VERSION ""

NS_ :

BS_:

BU_: MCTM_LS TIM_LS EOCM2cp_K2_LS EOCM2cp_K1_LS ADIMa_LS BCM_LS SAM_SR_LS SAM_SL_LS SAM_PR_LS SAM_PL_LS CGM3a_LS Dummy_LS VICM_LS ECC_LS PEPS_LS AOS_LS SDM_PR_LS AOS2_LS DLM_LS SCCM_2_LS SCCM_1_LS UPA_LS ADIMb_LS

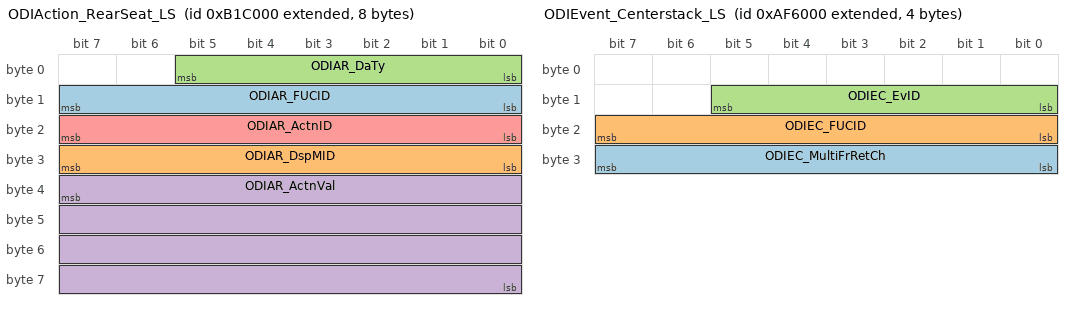
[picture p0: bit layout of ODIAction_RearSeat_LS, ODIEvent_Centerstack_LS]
BO_ 2159132672 ODIAction_RearSeat_LS: 8 MCTM_LS
 SG_ ODIAR_FUCID : 15|8@0+ (1,0) [0|255] ""  ECC_LS,CGM3a_LS
 SG_ ODIAR_DspMID : 31|8@0+ (1,0) [0|255] ""  ECC_LS,CGM3a_LS
 SG_ ODIAR_DaTy : 5|6@0+ (1,0) [0|63] ""  ECC_LS,CGM3a_LS
 SG_ ODIAR_ActnVal : 39|32@0+ (1,0) [0|4294967295] ""  ECC_LS,CGM3a_LS
 SG_ ODIAR_ActnID : 23|8@0+ (1,0) [0|255] ""  ECC_LS,CGM3a_LS

BO_ 2158968832 ODI_RearSeat_2_Centerstack_LS: 8 MCTM_LS
 SG_ ODI_RSD2CntrStck : 7|64@0+ (1,0) [0|1.84467440737096E+019] ""  CGM3a_LS

BO_ 2158895104 ODI_CenterStack_2_RearSeat_LS: 8 CGM3a_LS
 SG_ ODI_CntrStck2RSD : 7|64@0+ (1,0) [0|1.84467440737096E+019] ""  MCTM_LS

BO_ 2158960640 ODIIndication_Centerstack_LS: 8 CGM3a_LS
 SG_ ODIIC_FUCID : 7|8@0+ (1,0) [0|255] ""  MCTM_LS
 SG_ ODIIC_ODIInd9 : 23|1@0+ (1,0) [0|1] ""  MCTM_LS
 SG_ ODIIC_ODIInd8 : 8|1@0+ (1,0) [0|1] ""  MCTM_LS
 SG_ ODIIC_ODIInd7 : 9|1@0+ (1,0) [0|1] ""  MCTM_LS
 SG_ ODIIC_ODIInd6 : 10|1@0+ (1,0) [0|1] ""  MCTM_LS
 SG_ ODIIC_ODIInd56 : 56|1@0+ (1,0) [0|1] ""  MCTM_LS
 SG_ ODIIC_ODIInd55 : 57|1@0+ (1,0) [0|1] ""  MCTM_LS
 SG_ ODIIC_ODIInd54 : 58|1@0+ (1,0) [0|1] ""  MCTM_LS
 SG_ ODIIC_ODIInd53 : 59|1@0+ (1,0) [0|1] ""  MCTM_LS
 SG_ ODIIC_ODIInd52 : 60|1@0+ (1,0) [0|1] ""  MCTM_LS
 SG_ ODIIC_ODIInd51 : 61|1@0+ (1,0) [0|1] ""  MCTM_LS
 SG_ ODIIC_ODIInd50 : 62|1@0+ (1,0) [0|1] ""  MCTM_LS
 SG_ ODIIC_ODIInd5 : 11|1@0+ (1,0) [0|1] ""  MCTM_LS
 SG_ ODIIC_ODIInd49 : 63|1@0+ (1,0) [0|1] ""  MCTM_LS
 SG_ ODIIC_ODIInd48 : 48|1@0+ (1,0) [0|1] ""  MCTM_LS
 SG_ ODIIC_ODIInd47 : 49|1@0+ (1,0) [0|1] ""  MCTM_LS
 SG_ ODIIC_ODIInd46 : 50|1@0+ (1,0) [0|1] ""  MCTM_LS
 SG_ ODIIC_ODIInd45 : 51|1@0+ (1,0) [0|1] ""  MCTM_LS
 SG_ ODIIC_ODIInd44 : 52|1@0+ (1,0) [0|1] ""  MCTM_LS
 SG_ ODIIC_ODIInd43 : 53|1@0+ (1,0) [0|1] ""  MCTM_LS
 SG_ ODIIC_ODIInd42 : 54|1@0+ (1,0) [0|1] ""  MCTM_LS
 SG_ ODIIC_ODIInd41 : 55|1@0+ (1,0) [0|1] ""  MCTM_LS
 SG_ ODIIC_ODIInd40 : 40|1@0+ (1,0) [0|1] ""  MCTM_LS
 SG_ ODIIC_ODIInd4 : 12|1@0+ (1,0) [0|1] ""  MCTM_LS
 SG_ ODIIC_ODIInd39 : 41|1@0+ (1,0) [0|1] ""  MCTM_LS
 SG_ ODIIC_ODIInd38 : 42|1@0+ (1,0) [0|1] ""  MCTM_LS
 SG_ ODIIC_ODIInd37 : 43|1@0+ (1,0) [0|1] ""  MCTM_LS
 SG_ ODIIC_ODIInd36 : 44|1@0+ (1,0) [0|1] ""  MCTM_LS
 SG_ ODIIC_ODIInd35 : 45|1@0+ (1,0) [0|1] ""  MCTM_LS
 SG_ ODIIC_ODIInd34 : 46|1@0+ (1,0) [0|1] ""  MCTM_LS
 SG_ ODIIC_ODIInd33 : 47|1@0+ (1,0) [0|1] ""  MCTM_LS
 SG_ ODIIC_ODIInd32 : 32|1@0+ (1,0) [0|1] ""  MCTM_LS
 SG_ ODIIC_ODIInd31 : 33|1@0+ (1,0) [0|1] ""  MCTM_LS
 SG_ ODIIC_ODIInd30 : 34|1@0+ (1,0) [0|1] ""  MCTM_LS
 SG_ ODIIC_ODIInd3 : 13|1@0+ (1,0) [0|1] ""  MCTM_LS
 SG_ ODIIC_ODIInd29 : 35|1@0+ (1,0) [0|1] ""  MCTM_LS
 SG_ ODIIC_ODIInd28 : 36|1@0+ (1,0) [0|1] ""  MCTM_LS
 SG_ ODIIC_ODIInd27 : 37|1@0+ (1,0) [0|1] ""  MCTM_LS
 SG_ ODIIC_ODIInd26 : 38|1@0+ (1,0) [0|1] ""  MCTM_LS
 SG_ ODIIC_ODIInd25 : 39|1@0+ (1,0) [0|1] ""  MCTM_LS
 SG_ ODIIC_ODIInd24 : 24|1@0+ (1,0) [0|1] ""  MCTM_LS
 SG_ ODIIC_ODIInd23 : 25|1@0+ (1,0) [0|1] ""  MCTM_LS
 SG_ ODIIC_ODIInd22 : 26|1@0+ (1,0) [0|1] ""  MCTM_LS
 SG_ ODIIC_ODIInd21 : 27|1@0+ (1,0) [0|1] ""  MCTM_LS
 SG_ ODIIC_ODIInd20 : 28|1@0+ (1,0) [0|1] ""  MCTM_LS
 SG_ ODIIC_ODIInd2 : 14|1@0+ (1,0) [0|1] ""  MCTM_LS
 SG_ ODIIC_ODIInd19 : 29|1@0+ (1,0) [0|1] ""  MCTM_LS
 SG_ ODIIC_ODIInd18 : 30|1@0+ (1,0) [0|1] ""  MCTM_LS
 SG_ ODIIC_ODIInd17 : 31|1@0+ (1,0) [0|1] ""  MCTM_LS
 SG_ ODIIC_ODIInd16 : 16|1@0+ (1,0) [0|1] ""  MCTM_LS
 SG_ ODIIC_ODIInd15 : 17|1@0+ (1,0) [0|1] ""  MCTM_LS
 SG_ ODIIC_ODIInd14 : 18|1@0+ (1,0) [0|1] ""  MCTM_LS
 SG_ ODIIC_ODIInd13 : 19|1@0+ (1,0) [0|1] ""  MCTM_LS
 SG_ ODIIC_ODIInd12 : 20|1@0+ (1,0) [0|1] ""  MCTM_LS
 SG_ ODIIC_ODIInd11 : 21|1@0+ (1,0) [0|1] ""  MCTM_LS
 SG_ ODIIC_ODIInd10 : 22|1@0+ (1,0) [0|1] ""  MCTM_LS
 SG_ ODIIC_ODIInd1 : 15|1@0+ (1,0) [0|1] ""  MCTM_LS

BO_ 2158977024 ODIEvent_Centerstack_LS: 4 CGM3a_LS
 SG_ ODIEC_MultiFrRetCh : 31|8@0+ (1,0) [0|255] ""  MCTM_LS
 SG_ ODIEC_FUCID : 23|8@0+ (1,0) [0|255] ""  MCTM_LS
 SG_ ODIEC_EvID : 13|6@0+ (1,0) [0|63] ""  MCTM_LS

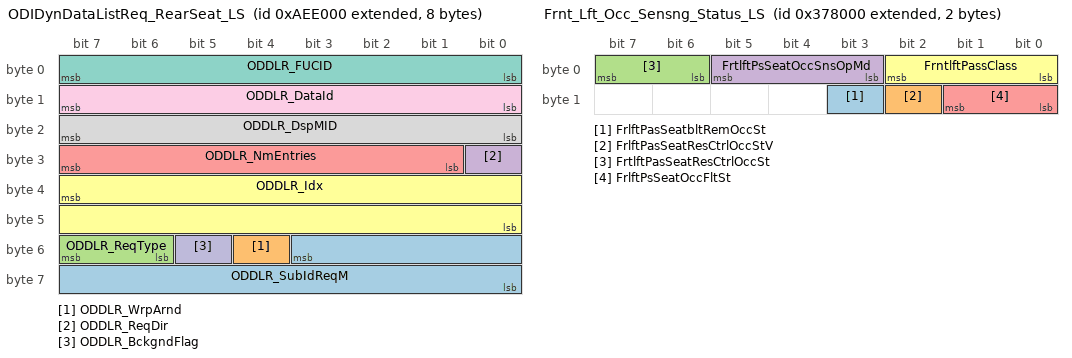
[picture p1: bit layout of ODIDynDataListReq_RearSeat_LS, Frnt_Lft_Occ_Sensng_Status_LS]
BO_ 2158944256 ODIDynDataListReq_RearSeat_LS: 8 MCTM_LS
 SG_ ODDLR_SubIdReqM : 51|12@0+ (1,0) [0|4095] ""  CGM3a_LS
 SG_ ODDLR_WrpArnd : 52|1@0+ (1,0) [0|1] ""  CGM3a_LS
 SG_ ODDLR_ReqType : 55|2@0+ (1,0) [0|3] ""  CGM3a_LS
 SG_ ODDLR_ReqDir : 24|1@0+ (1,0) [0|1] ""  CGM3a_LS
 SG_ ODDLR_NmEntries : 31|7@0+ (1,0) [0|127] ""  CGM3a_LS
 SG_ ODDLR_Idx : 39|16@0+ (1,0) [0|65535] ""  CGM3a_LS
 SG_ ODDLR_FUCID : 7|8@0+ (1,0) [0|255] ""  CGM3a_LS
 SG_ ODDLR_DspMID : 23|8@0+ (1,0) [0|255] ""  CGM3a_LS
 SG_ ODDLR_DataId : 15|8@0+ (1,0) [0|255] ""  CGM3a_LS
 SG_ ODDLR_BckgndFlag : 53|1@0+ (1,0) [0|1] ""  CGM3a_LS

BO_ 2151120896 Frnt_Lft_Occ_Sensng_Status_LS: 2 AOS2_LS
 SG_ FrlftPasSeatbltRemOccSt : 11|1@0+ (1,0) [0|1] ""  SDM_PR_LS,MCTM_LS,ECC_LS,CGM3a_LS,ADIMb_LS
 SG_ FrlftPasSeatResCtrlOccStV : 10|1@0+ (1,0) [0|1] ""  SDM_PR_LS,MCTM_LS,ECC_LS,CGM3a_LS,ADIMb_LS
 SG_ FrtlftPasSeatResCtrlOccSt : 7|2@0+ (1,0) [0|3] ""  SDM_PR_LS,MCTM_LS,ECC_LS,CGM3a_LS,ADIMb_LS
 SG_ FrtlftPsSeatOccSnsOpMd : 5|3@0+ (1,0) [0|7] "N/A"  SDM_PR_LS,MCTM_LS,ECC_LS,CGM3a_LS,ADIMb_LS
 SG_ FrlftPsSeatOccFltSt : 9|2@0+ (1,0) [0|3] "N/A"  SDM_PR_LS,MCTM_LS,ECC_LS,CGM3a_LS,ADIMb_LS
 SG_ FrntlftPassClass : 2|3@0+ (1,0) [0|7] ""  SDM_PR_LS,MCTM_LS,ECC_LS,CGM3a_LS,ADIMb_LS

BO_ 2154332160 Car_Sharing_Veh_Chlng_LS: 8 BCM_LS
 SG_ CrShrngVehChlng : 7|64@0+ (1,0) [0|1.84467440737096E+019] ""  CGM3a_LS

BO_ 2154414080 Car_Shring_Conectn_Uniq_ID1_LS: 8 BCM_LS
 SG_ CrShrngConnUnqIdntfr1 : 7|64@0+ (1,0) [0|1.84467440737096E+019] ""  CGM3a_LS

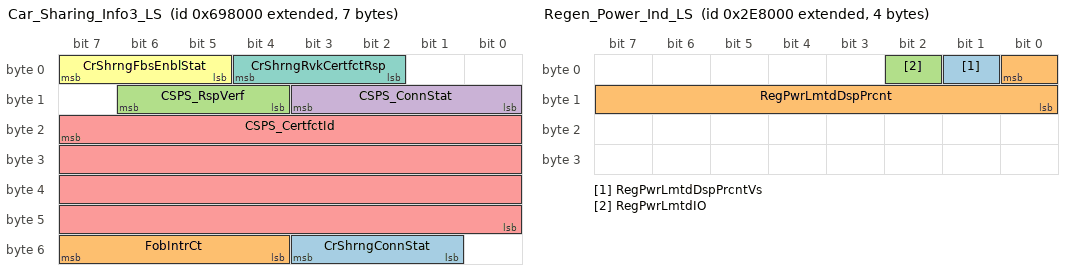
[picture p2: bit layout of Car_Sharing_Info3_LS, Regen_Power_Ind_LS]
BO_ 2154397696 Car_Sharing_Info3_LS: 7 BCM_LS
 SG_ CrShrngConnStat : 51|3@0+ (1,0) [0|7] ""  CGM3a_LS
 SG_ FobIntrCt : 55|4@0+ (1,0) [0|15] ""  CGM3a_LS
 SG_ CSPS_RspVerf : 14|3@0+ (1,0) [0|7] ""  CGM3a_LS
 SG_ CSPS_ConnStat : 11|4@0+ (1,0) [0|15] ""  CGM3a_LS
 SG_ CSPS_CertfctId : 23|32@0+ (1,0) [0|4294967295] ""  CGM3a_LS
 SG_ CrShrngFbsEnblStat : 7|3@0+ (1,0) [0|7] ""  PEPS_LS,CGM3a_LS
 SG_ CrShrngRvkCertfctRsp : 4|3@0+ (1,0) [0|7] ""  CGM3a_LS

BO_ 2154536960 Car_sharing_Encrypt_Secret_LS: 8 BCM_LS
 SG_ CrShrngEncrpScrt : 7|64@0+ (1,0) [0|1.84467440737096E+019] ""  CGM3a_LS

BO_ 2154545152 Car_Shar_Intrmdt_CA_Cert_Rsp_LS: 8 BCM_LS
 SG_ CrShrgIntCtftAthrtyCtftRp : 7|64@0+ (1,0) [0|1.84467440737096E+019] ""  CGM3a_LS

BO_ 2154504192 Car_Sharing_User_Cert_Resp_LS: 8 BCM_LS
 SG_ CrShrngUsrCertfctRsp : 7|64@0+ (1,0) [0|1.84467440737096E+019] ""  CGM3a_LS

BO_ 2154463232 Car_Sharing_Phone_Resp2_LS: 8 CGM3a_LS
 SG_ CrShrngPhRsp2 : 7|64@0+ (1,0) [0|1.84467440737096E+019] ""  BCM_LS

BO_ 2154446848 Car_Sharing_Phone_Resp1_LS: 8 CGM3a_LS
 SG_ CrShrngPhRsp1 : 7|64@0+ (1,0) [0|1.84467440737096E+019] ""  BCM_LS

BO_ 1347 UUDT_Resp_From_SCCM1_LS: 8 SCCM_1_LS
 SG_ DgnInf_LS543 : 7|64@0+ (1,0) [0|1.84467440737096E+019] ""  CGM3a_LS

BO_ 2152177664 OTA_Electric_Pwr_Readiness_LS: 1 BCM_LS
 SG_ RmtRflshElecPwrRdness : 7|8@0+ (0.025,0) [0|6.375] "AmpHour"  CGM3a_LS

BO_ 2150531072 Regen_Power_Ind_LS: 4 VICM_LS
 SG_ RegPwrLmtdDspPrcntVs : 1|1@0+ (1,0) [0|1] ""  CGM3a_LS
 SG_ RegPwrLmtdDspPrcnt : 0|9@0- (0.392157,0) [-100.392192|100.000035] "%"  CGM3a_LS
 SG_ RegPwrLmtdIO : 2|1@0+ (1,0) [0|1] ""  CGM3a_LS

BO_ 856 Temp_Diag_CAN_Resp_LS_358: 8 Dummy_LS
 SG_ DgnInf : 7|64@0+ (1,0) [0|1.84467440737096E+019] ""  CGM3a_LS

BO_ 921 Temp_Diag_CAN_Resp_LS_399: 8 Dummy_LS
 SG_ DgnInf : 7|64@0+ (1,0) [0|1.84467440737096E+019] ""  CGM3a_LS

BO_ 88 Temp_Diag_CAN_Req_LS_058: 8 CGM3a_LS
 SG_ DgnInf : 7|64@0+ (1,0) [0|1.84467440737096E+019] ""  Dummy_LS

BO_ 153 Temp_Diag_CAN_Req_LS_099: 8 CGM3a_LS
 SG_ DgnInf : 7|64@0+ (1,0) [0|1.84467440737096E+019] ""  Dummy_LS

BO_ 2159255552 ODI_CenterStack_2_BCM_LS: 8 CGM3a_LS
 SG_ ODI_CntrStck2BCM : 7|64@0+ (1,0) [0|1.84467440737096E+019] ""  BCM_LS

BO_ 2159247360 ODI_BCM_2_CenterStack_LS: 8 BCM_LS
 SG_ ODI_BCM2CntrStck : 7|64@0+ (1,0) [0|1.84467440737096E+019] ""  CGM3a_LS

BO_ 2154725376 Auxiliary_Heater_LS: 1 ECC_LS
 SG_ AuxHtrAtv378 : 6|1@0+ (1,0) [0|1] ""  CGM3a_LS,ECC_LS
 SG_ AuxHtrRq : 7|1@0+ (1,0) [0|1] ""  CGM3a_LS,ECC_LS

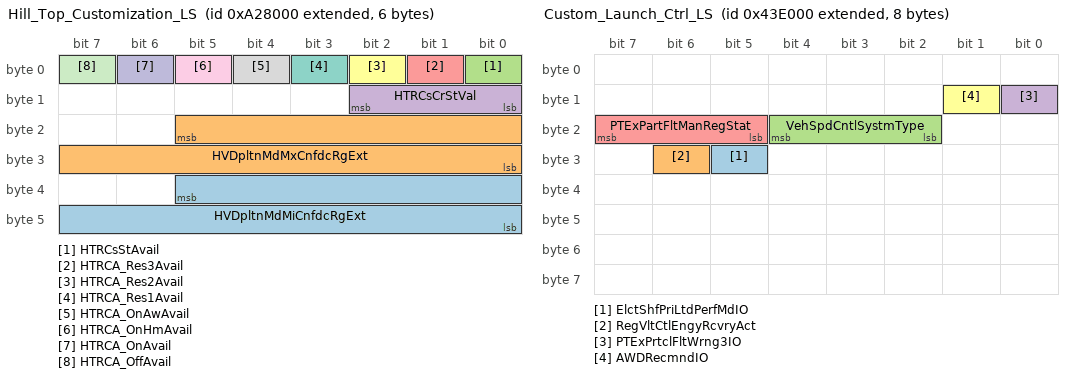
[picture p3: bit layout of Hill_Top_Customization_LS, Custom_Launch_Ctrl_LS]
BO_ 2158133248 Hill_Top_Customization_LS: 6 VICM_LS
 SG_ HVDpltnMdMiCnfdcRgExt : 37|14@0+ (0.1,0) [0|1638.3] "km"  CGM3a_LS
 SG_ HVDpltnMdMxCnfdcRgExt : 21|14@0+ (0.1,0) [0|1638.3] "km"  CGM3a_LS
 SG_ HTRCsStAvail : 0|1@0+ (1,0) [0|1] ""  CGM3a_LS
 SG_ HTRCsCrStVal : 10|3@0+ (1,0) [0|7] ""  CGM3a_LS
 SG_ HTRCA_Res3Avail : 1|1@0+ (1,0) [0|1] ""  CGM3a_LS
 SG_ HTRCA_Res2Avail : 2|1@0+ (1,0) [0|1] ""  CGM3a_LS
 SG_ HTRCA_Res1Avail : 3|1@0+ (1,0) [0|1] ""  CGM3a_LS
 SG_ HTRCA_OnAwAvail : 4|1@0+ (1,0) [0|1] ""  CGM3a_LS
 SG_ HTRCA_OnHmAvail : 5|1@0+ (1,0) [0|1] ""  CGM3a_LS
 SG_ HTRCA_OnAvail : 6|1@0+ (1,0) [0|1] ""  CGM3a_LS
 SG_ HTRCA_OffAvail : 7|1@0+ (1,0) [0|1] ""  CGM3a_LS

BO_ 2151931904 Custom_Launch_Ctrl_LS: 8 BCM_LS
 SG_ ElctShfPriLtdPerfMdIO : 29|1@0+ (1,0) [0|1] ""  CGM3a_LS
 SG_ RegVltCtlEngyRcvryAct : 30|1@0+ (1,0) [0|1] ""  CGM3a_LS
 SG_ VehSpdCntlSystmType : 20|3@0+ (1,0) [0|7] ""  CGM3a_LS
 SG_ PTExPrtclFltWrng3IO : 8|1@0+ (1,0) [0|1] ""  CGM3a_LS
 SG_ PTExPartFltManRegStat : 23|3@0+ (1,0) [0|7] ""  CGM3a_LS
 SG_ AWDRecmndIO : 9|1@0+ (1,0) [0|1] ""  CGM3a_LS

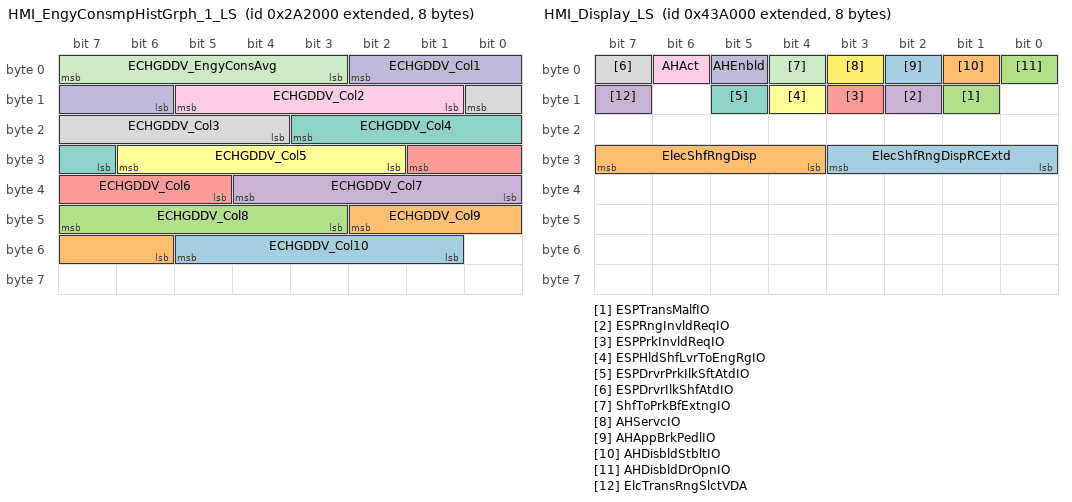
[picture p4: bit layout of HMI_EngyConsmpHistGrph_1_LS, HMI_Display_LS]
BO_ 2150244352 HMI_EngyConsmpHistGrph_1_LS: 8 VICM_LS
 SG_ ECHGDDV_Col10 : 53|5@0+ (1,0) [0|31] ""  CGM3a_LS
 SG_ ECHGDDV_Col9 : 42|5@0+ (1,0) [0|31] ""  CGM3a_LS
 SG_ ECHGDDV_Col8 : 47|5@0+ (1,0) [0|31] ""  CGM3a_LS
 SG_ ECHGDDV_Col7 : 36|5@0+ (1,0) [0|31] ""  CGM3a_LS
 SG_ ECHGDDV_Col6 : 25|5@0+ (1,0) [0|31] ""  CGM3a_LS
 SG_ ECHGDDV_Col5 : 30|5@0+ (1,0) [0|31] ""  CGM3a_LS
 SG_ ECHGDDV_Col4 : 19|5@0+ (1,0) [0|31] ""  CGM3a_LS
 SG_ ECHGDDV_Col3 : 8|5@0+ (1,0) [0|31] ""  CGM3a_LS
 SG_ ECHGDDV_Col2 : 13|5@0+ (1,0) [0|31] ""  CGM3a_LS
 SG_ ECHGDDV_Col1 : 2|5@0+ (1,0) [0|31] ""  CGM3a_LS
 SG_ ECHGDDV_EngyConsAvg : 7|5@0+ (1,0) [0|31] ""  CGM3a_LS

BO_ 579 USDT_Req_to_SCCM1_LS: 8 CGM3a_LS
 SG_ DgnInf : 7|64@0+ (1,0) [0|1.84467440737096E+019] ""  CGM3a_LS,SCCM_1_LS

BO_ 2155028480 Lane_Change_Threat_LS: 2 UPA_LS
 SG_ RtLnChngThrtAprchSpd : 15|8@0- (1,0) [-128|127] "km/h"  BCM_LS,CGM3a_LS
 SG_ RgtLnChgThrt : 0|1@0+ (1,0) [0|1] ""  BCM_LS,CGM3a_LS

BO_ 2151915520 HMI_Display_LS: 8 BCM_LS
 SG_ ElecShfRngDispRCExtd : 27|4@0+ (1,0) [0|15] ""  CGM3a_LS
 SG_ ElecShfRngDisp : 31|4@0+ (1,0) [0|15] ""  CGM3a_LS
 SG_ ESPTransMalfIO : 9|1@0+ (1,0) [0|1] ""  CGM3a_LS
 SG_ ESPRngInvldReqIO : 10|1@0+ (1,0) [0|1] ""  CGM3a_LS
 SG_ ESPPrkInvldReqIO : 11|1@0+ (1,0) [0|1] ""  CGM3a_LS
 SG_ ESPHldShfLvrToEngRgIO : 12|1@0+ (1,0) [0|1] ""  CGM3a_LS
 SG_ ESPDrvrPrkIlkSftAtdIO : 13|1@0+ (1,0) [0|1] ""  CGM3a_LS
 SG_ ESPDrvrIlkShfAtdIO : 7|1@0+ (1,0) [0|1] ""  CGM3a_LS
 SG_ AHAct : 6|1@0+ (1,0) [0|1] ""  CGM3a_LS
 SG_ AHEnbld : 5|1@0+ (1,0) [0|1] ""  CGM3a_LS
 SG_ ShfToPrkBfExtngIO : 4|1@0+ (1,0) [0|1] ""  CGM3a_LS
 SG_ AHServcIO : 3|1@0+ (1,0) [0|1] ""  CGM3a_LS
 SG_ AHAppBrkPedlIO : 2|1@0+ (1,0) [0|1] ""  CGM3a_LS
 SG_ AHDisbldStbltIO : 1|1@0+ (1,0) [0|1] ""  CGM3a_LS
 SG_ AHDisbldDrOpnIO : 0|1@0+ (1,0) [0|1] ""  CGM3a_LS
 SG_ ElcTransRngSlctVDA : 15|1@0+ (1,0) [0|1] ""  CGM3a_LS

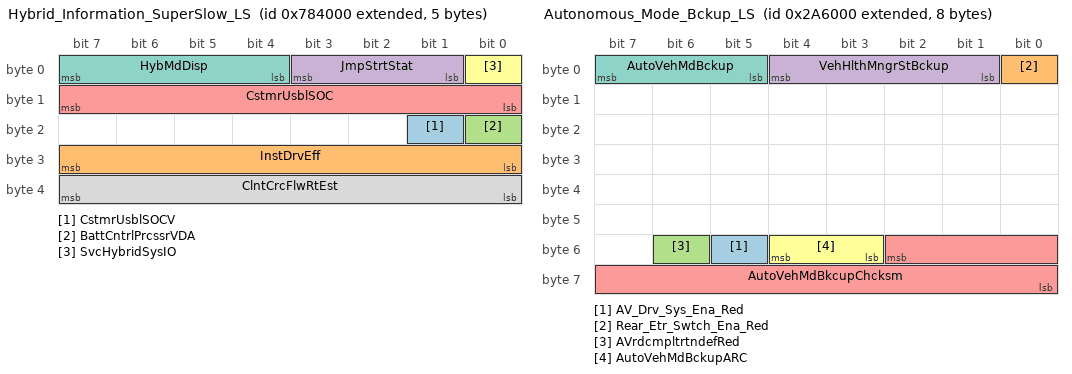
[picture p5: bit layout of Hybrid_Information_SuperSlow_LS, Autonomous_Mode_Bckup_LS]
BO_ 2155364352 Hybrid_Information_SuperSlow_LS: 5 VICM_LS
 SG_ CstmrUsblSOCV : 17|1@0+ (1,0) [0|1] ""  DLM_LS,CGM3a_LS,ADIMa_LS,ADIMb_LS
 SG_ InstDrvEff : 31|8@0- (0.78125,0) [-100|99.21875] "%"  CGM3a_LS
 SG_ BattCntrlPrcssrVDA : 16|1@0+ (1,0) [0|1] ""  CGM3a_LS
 SG_ JmpStrtStat : 3|3@0+ (1,0) [0|7] ""  CGM3a_LS
 SG_ CstmrUsblSOC : 15|8@0+ (0.39216,0) [0|100.0008] "%"  DLM_LS,CGM3a_LS,ADIMa_LS,ADIMb_LS
 SG_ SvcHybridSysIO : 0|1@0+ (1,0) [0|1] ""  CGM3a_LS
 SG_ HybMdDisp : 7|4@0+ (1,0) [0|15] ""  CGM3a_LS
 SG_ ClntCrcFlwRtEst : 39|8@0+ (0.392157,0) [0|100.000035] "%"  CGM3a_LS

BO_ 2150260736 Autonomous_Mode_Bckup_LS: 8 ADIMb_LS
 SG_ AV_Drv_Sys_Ena_Red : 53|1@0+ (1,0) [0|1] ""  MCTM_LS,CGM3a_LS
 SG_ Rear_Etr_Swtch_Ena_Red : 0|1@0+ (1,0) [0|1] ""  MCTM_LS,CGM3a_LS
 SG_ AVrdcmpltrtndefRed : 54|1@0+ (1,0) [0|1] ""  CGM3a_LS,MCTM_LS,BCM_LS
 SG_ VehHlthMngrStBckup : 4|4@0+ (1,0) [0|15] ""  CGM3a_LS,SDM_PR_LS
 SG_ AutoVehMdBkcupChcksm : 50|11@0+ (1,0) [0|2047] ""  MCTM_LS,CGM3a_LS,SCCM_2_LS,SCCM_1_LS,SDM_PR_LS,BCM_LS
 SG_ AutoVehMdBckupARC : 52|2@0+ (1,0) [0|3] ""  MCTM_LS,CGM3a_LS,SCCM_2_LS,SCCM_1_LS,SDM_PR_LS,BCM_LS
 SG_ AutoVehMdBckup : 7|3@0+ (1,0) [0|7] ""  MCTM_LS,CGM3a_LS,PEPS_LS,SCCM_2_LS,SCCM_1_LS,SDM_PR_LS,BCM_LS

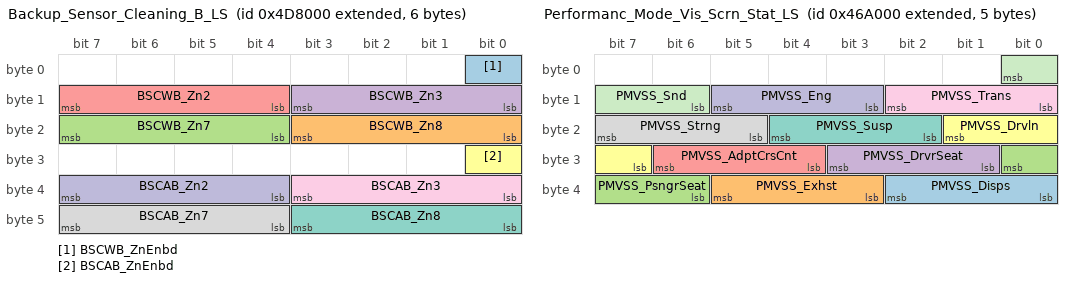
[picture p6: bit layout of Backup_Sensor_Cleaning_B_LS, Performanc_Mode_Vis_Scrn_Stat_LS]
BO_ 2152562688 Backup_Sensor_Cleaning_B_LS: 6 ADIMb_LS
 SG_ BSCWB_ZnEnbd : 0|1@0+ (1,0) [0|1] ""  CGM3a_LS,SCCM_2_LS
 SG_ BSCWB_Zn8 : 19|4@0+ (0.25,0) [0|3.75] "s"  CGM3a_LS,SCCM_2_LS
 SG_ BSCWB_Zn7 : 23|4@0+ (0.25,0) [0|3.75] "s"  CGM3a_LS,SCCM_2_LS
 SG_ BSCWB_Zn3 : 11|4@0+ (0.25,0) [0|3.75] "s"  CGM3a_LS,SCCM_2_LS
 SG_ BSCWB_Zn2 : 15|4@0+ (0.25,0) [0|3.75] "s"  CGM3a_LS,SCCM_2_LS
 SG_ BSCAB_ZnEnbd : 24|1@0+ (1,0) [0|1] ""  CGM3a_LS,SCCM_2_LS
 SG_ BSCAB_Zn8 : 43|4@0+ (0.25,0) [0|3.75] "s"  CGM3a_LS,SCCM_2_LS
 SG_ BSCAB_Zn7 : 47|4@0+ (0.25,0) [0|3.75] "s"  CGM3a_LS,SCCM_2_LS
 SG_ BSCAB_Zn3 : 35|4@0+ (0.25,0) [0|3.75] "s"  CGM3a_LS,SCCM_2_LS
 SG_ BSCAB_Zn2 : 39|4@0+ (0.25,0) [0|3.75] "s"  CGM3a_LS,SCCM_2_LS

BO_ 2152112128 Performanc_Mode_Vis_Scrn_Stat_LS: 5 BCM_LS
 SG_ PMVSS_Disps : 34|3@0+ (1,0) [0|7] ""  CGM3a_LS
 SG_ PMVSS_Exhst : 37|3@0+ (1,0) [0|7] ""  CGM3a_LS
 SG_ PMVSS_PsngrSeat : 24|3@0+ (1,0) [0|7] ""  CGM3a_LS
 SG_ PMVSS_DrvrSeat : 27|3@0+ (1,0) [0|7] ""  CGM3a_LS
 SG_ PMVSS_AdptCrsCnt : 30|3@0+ (1,0) [0|7] ""  CGM3a_LS
 SG_ PMVSS_Drvln : 17|3@0+ (1,0) [0|7] ""  CGM3a_LS
 SG_ PMVSS_Susp : 20|3@0+ (1,0) [0|7] ""  CGM3a_LS
 SG_ PMVSS_Strng : 23|3@0+ (1,0) [0|7] ""  CGM3a_LS
 SG_ PMVSS_Trans : 10|3@0+ (1,0) [0|7] ""  CGM3a_LS
 SG_ PMVSS_Eng : 13|3@0+ (1,0) [0|7] ""  CGM3a_LS
 SG_ PMVSS_Snd : 0|3@0+ (1,0) [0|7] ""  CGM3a_LS

BO_ 2153857024 Teen_Driver_Event_Report_2_LS: 8 BCM_LS
 SG_ TnDrvTrCtrlEvntsRpt : 49|10@0+ (1,0) [0|1023] "counts"  CGM3a_LS
 SG_ TnDrvDrowDrvAlrtsRpt : 43|10@0+ (1,0) [0|1023] "counts"  CGM3a_LS
 SG_ TDRCADD_WOTEvnts : 11|1@0+ (1,0) [0|1] ""  CGM3a_LS
 SG_ TDRCADD_LDWEvnts : 10|1@0+ (1,0) [0|1] ""  CGM3a_LS
 SG_ TDRCADD_FCMBrEvts : 13|1@0+ (1,0) [0|1] ""  CGM3a_LS
 SG_ TDRCADD_DrwDrvAlrt : 12|1@0+ (1,0) [0|1] ""  CGM3a_LS
 SG_ TDRCADD_RCMBrEvts : 14|1@0+ (1,0) [0|1] ""  CGM3a_LS
 SG_ TDRCADD_FCImntAlrts : 15|1@0+ (1,0) [0|1] ""  CGM3a_LS
 SG_ TDRCADD_FCHdwyAlrt : 0|1@0+ (1,0) [0|1] ""  CGM3a_LS
 SG_ TDRCADD_StCtrlEvnts : 2|1@0+ (1,0) [0|1] ""  CGM3a_LS
 SG_ TDRCADD_ABSAtvEvt : 1|1@0+ (1,0) [0|1] ""  CGM3a_LS
 SG_ TDRCADD_TrCtrlEvnts : 3|1@0+ (1,0) [0|1] ""  CGM3a_LS
 SG_ TDRCADD_OvSpdEvnt : 4|1@0+ (1,0) [0|1] ""  CGM3a_LS
 SG_ TDRCADD_DistDrvn : 5|1@0+ (1,0) [0|1] ""  CGM3a_LS
 SG_ TDRCADD_MaxSpd : 6|1@0+ (1,0) [0|1] ""  CGM3a_LS
 SG_ TnDrvStblCtrlEvntsRpt : 37|10@0+ (1,0) [0|1023] "counts"  CGM3a_LS
 SG_ TnDrvABSAtvEvntsRpt : 31|10@0+ (1,0) [0|1023] "counts"  CGM3a_LS
 SG_ TeenDrvWOTEvntsRpt : 9|10@0+ (1,0) [0|1023] "counts"  CGM3a_LS

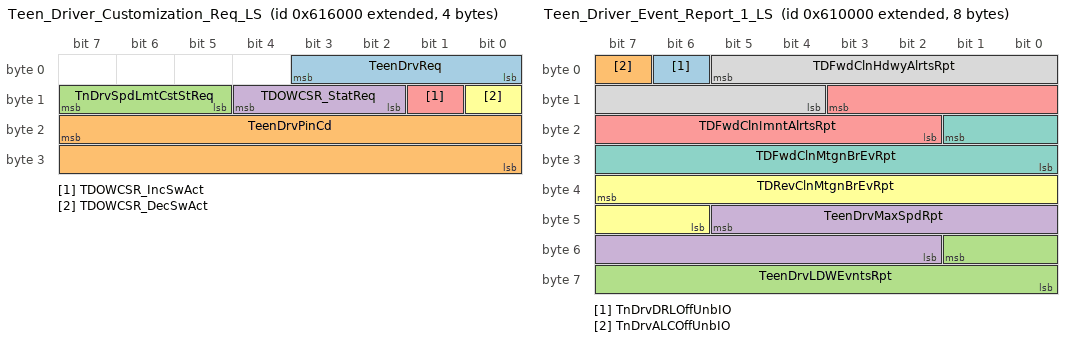
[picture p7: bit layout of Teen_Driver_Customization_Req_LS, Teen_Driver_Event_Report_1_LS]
BO_ 2153865216 Teen_Driver_Customization_Req_LS: 4 CGM3a_LS
 SG_ TeenDrvReq : 3|4@0+ (1,0) [0|15] ""  BCM_LS
 SG_ TeenDrvPinCd : 23|16@0+ (1,0) [0|39321] ""  BCM_LS
 SG_ TnDrvSpdLmtCstStReq : 15|3@0+ (1,0) [0|7] ""  BCM_LS
 SG_ TDOWCSR_StatReq : 12|3@0+ (1,0) [0|7] ""  BCM_LS
 SG_ TDOWCSR_IncSwAct : 9|1@0+ (1,0) [0|1] ""  BCM_LS
 SG_ TDOWCSR_DecSwAct : 8|1@0+ (1,0) [0|1] ""  BCM_LS

BO_ 2153840640 Teen_Driver_Event_Report_1_LS: 8 BCM_LS
 SG_ TnDrvDRLOffUnbIO : 6|1@0+ (1,0) [0|1] ""  CGM3a_LS
 SG_ TnDrvALCOffUnbIO : 7|1@0+ (1,0) [0|1] ""  CGM3a_LS
 SG_ TeenDrvLDWEvntsRpt : 49|10@0+ (1,0) [0|1023] "counts"  CGM3a_LS
 SG_ TeenDrvMaxSpdRpt : 45|12@0+ (0.0625,0) [0|255.9375] "km/h"  CGM3a_LS
 SG_ TDFwdClnImntAlrtsRpt : 11|10@0+ (1,0) [0|1023] "counts"  CGM3a_LS
 SG_ TDRevClnMtgnBrEvRpt : 39|10@0+ (1,0) [0|1023] "counts"  CGM3a_LS
 SG_ TDFwdClnMtgnBrEvRpt : 17|10@0+ (1,0) [0|1023] "counts"  CGM3a_LS
 SG_ TDFwdClnHdwyAlrtsRpt : 5|10@0+ (1,0) [0|1023] "counts"  CGM3a_LS

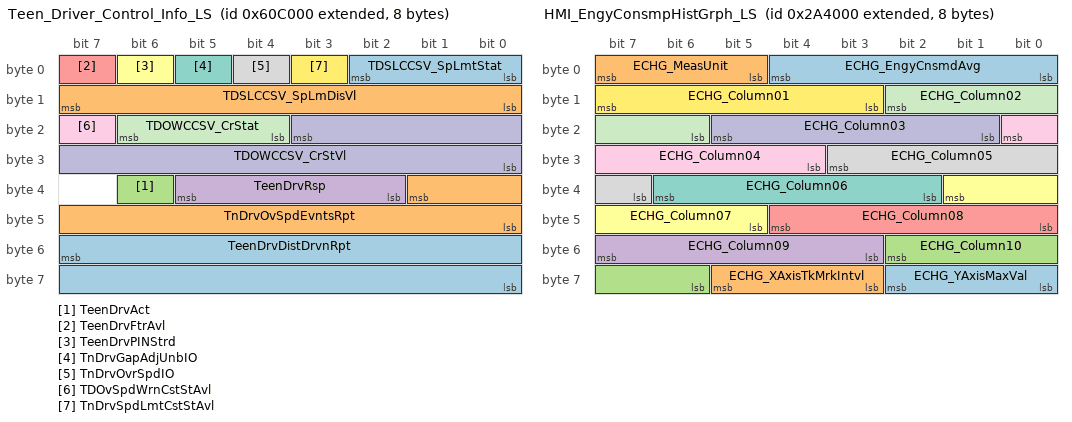
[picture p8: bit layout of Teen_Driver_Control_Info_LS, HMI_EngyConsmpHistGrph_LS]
BO_ 2153824256 Teen_Driver_Control_Info_LS: 8 BCM_LS
 SG_ TeenDrvDistDrvnRpt : 55|16@0+ (1,0) [0|65535] "km"  CGM3a_LS,EOCM2cp_K2_LS
 SG_ TnDrvOvSpdEvntsRpt : 33|10@0+ (1,0) [0|1023] "counts"  CGM3a_LS,EOCM2cp_K2_LS
 SG_ TeenDrvAct : 38|1@0+ (1,0) [0|1] ""  CGM3a_LS,UPA_LS,EOCM2cp_K2_LS
 SG_ TeenDrvRsp : 37|4@0+ (1,0) [0|15] ""  CGM3a_LS,EOCM2cp_K2_LS
 SG_ TeenDrvFtrAvl : 7|1@0+ (1,0) [0|1] ""  CGM3a_LS,EOCM2cp_K2_LS
 SG_ TeenDrvPINStrd : 6|1@0+ (1,0) [0|1] ""  CGM3a_LS,EOCM2cp_K2_LS
 SG_ TnDrvGapAdjUnbIO : 5|1@0+ (1,0) [0|1] ""  CGM3a_LS,EOCM2cp_K2_LS
 SG_ TnDrvOvrSpdIO : 4|1@0+ (1,0) [0|1] ""  CGM3a_LS,EOCM2cp_K2_LS
 SG_ TDOvSpdWrnCstStAvl : 23|1@0+ (1,0) [0|1] ""  CGM3a_LS,EOCM2cp_K2_LS
 SG_ TDOWCCSV_CrStVl : 19|12@0+ (0.0625,0) [0|255.9375] "km/h"  CGM3a_LS,EOCM2cp_K2_LS
 SG_ TDOWCCSV_CrStat : 22|3@0+ (1,0) [0|7] ""  CGM3a_LS,EOCM2cp_K2_LS
 SG_ TnDrvSpdLmtCstStAvl : 3|1@0+ (1,0) [0|1] ""  CGM3a_LS,EOCM2cp_K2_LS
 SG_ TDSLCCSV_SpLmtStat : 2|3@0+ (1,0) [0|7] ""  CGM3a_LS,EOCM2cp_K2_LS
 SG_ TDSLCCSV_SpLmDisVl : 15|8@0+ (2,0) [0|510] "km/h"  CGM3a_LS,EOCM2cp_K2_LS

BO_ 2150252544 HMI_EngyConsmpHistGrph_LS: 8 VICM_LS
 SG_ ECHG_YAxisMaxVal : 58|3@0+ (1,0) [0|7] ""  CGM3a_LS
 SG_ ECHG_XAxisTkMrkIntvl : 61|3@0+ (1,0) [0|7] ""  CGM3a_LS
 SG_ ECHG_Column10 : 50|5@0+ (1,0) [0|31] ""  CGM3a_LS
 SG_ ECHG_Column09 : 55|5@0+ (1,0) [0|31] ""  CGM3a_LS
 SG_ ECHG_Column08 : 44|5@0+ (1,0) [0|31] ""  CGM3a_LS
 SG_ ECHG_Column07 : 33|5@0+ (1,0) [0|31] ""  CGM3a_LS
 SG_ ECHG_Column06 : 38|5@0+ (1,0) [0|31] ""  CGM3a_LS
 SG_ ECHG_Column05 : 27|5@0+ (1,0) [0|31] ""  CGM3a_LS
 SG_ ECHG_Column04 : 16|5@0+ (1,0) [0|31] ""  CGM3a_LS
 SG_ ECHG_Column03 : 21|5@0+ (1,0) [0|31] ""  CGM3a_LS
 SG_ ECHG_Column02 : 10|5@0+ (1,0) [0|31] ""  CGM3a_LS
 SG_ ECHG_Column01 : 15|5@0+ (1,0) [0|31] ""  CGM3a_LS
 SG_ ECHG_EngyCnsmdAvg : 4|5@0+ (1,0) [0|31] ""  CGM3a_LS
 SG_ ECHG_MeasUnit : 7|3@0+ (1,0) [0|7] ""  CGM3a_LS

BO_ 2150391808 HMI_Hourmeter_Data_LS: 6 CGM3a_LS
 SG_ EngRunAtvTm : 31|24@0+ (1,0) [0|16777215] "min"  BCM_LS
 SG_ EngIdlAtvTm : 7|24@0+ (1,0) [0|16777215] "min"  BCM_LS

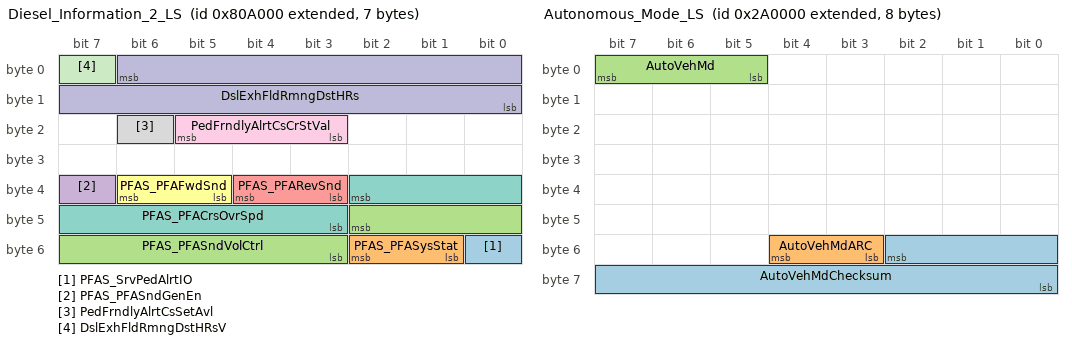
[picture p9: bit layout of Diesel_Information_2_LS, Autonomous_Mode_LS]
BO_ 2155913216 Diesel_Information_2_LS: 7 BCM_LS
 SG_ PFAS_SrvPedAlrtIO : 48|1@0+ (1,0) [0|1] ""  CGM3a_LS
 SG_ PFAS_PFASysStat : 50|2@0+ (1,0) [0|3] ""  CGM3a_LS
 SG_ PFAS_PFASndVolCtrl : 42|8@0+ (0.392157,0) [0|100.000035] "%"  CGM3a_LS
 SG_ PFAS_PFASndGenEn : 39|1@0+ (1,0) [0|1] ""  CGM3a_LS
 SG_ PFAS_PFARevSnd : 36|2@0+ (1,0) [0|3] ""  CGM3a_LS
 SG_ PFAS_PFAFwdSnd : 38|2@0+ (1,0) [0|3] ""  CGM3a_LS
 SG_ PFAS_PFACrsOvrSpd : 34|8@0+ (1,0) [0|255] "km/h"  CGM3a_LS
 SG_ PedFrndlyAlrtCsSetAvl : 22|1@0+ (1,0) [0|1] ""  CGM3a_LS
 SG_ PedFrndlyAlrtCsCrStVal : 21|3@0+ (1,0) [0|7] ""  CGM3a_LS
 SG_ DslExhFldRmngDstHRs : 6|15@0+ (2,0) [0|65534] "km"  CGM3a_LS
 SG_ DslExhFldRmngDstHRsV : 7|1@0+ (1,0) [0|1] ""  CGM3a_LS

BO_ 2034 CCP_Data_Transmission_Object_LS: 8 SAM_PL_LS
 SG_ DgnInf : 7|64@0+ (1,0) [0|1.84467440737096E+019] ""  CGM3a_LS

BO_ 2032 CCP_Command_Receive_Object_LS: 8 CGM3a_LS
 SG_ DgnInf : 7|64@0+ (1,0) [0|1.84467440737096E+019] ""  SAM_SR_LS,SAM_SL_LS,SAM_PR_LS,SAM_PL_LS

BO_ 2150236160 Autonomous_Mode_LS: 8 ADIMa_LS
 SG_ AutoVehMdChecksum : 50|11@0+ (1,0) [0|2047] ""  SAM_SR_LS,SAM_SL_LS,SAM_PR_LS,SAM_PL_LS,SCCM_2_LS,SCCM_1_LS,CGM3a_LS,SDM_PR_LS
 SG_ AutoVehMdARC : 52|2@0+ (1,0) [0|3] ""  SAM_SR_LS,SAM_SL_LS,SAM_PR_LS,SAM_PL_LS,SCCM_2_LS,SCCM_1_LS,CGM3a_LS,SDM_PR_LS
 SG_ AutoVehMd : 7|3@0+ (1,0) [0|7] ""  SAM_SR_LS,SAM_SL_LS,SAM_PR_LS,SAM_PL_LS,SCCM_2_LS,SCCM_1_LS,PEPS_LS,CGM3a_LS,SDM_PR_LS

BO_ 2159157248 ODI_CenterStack_2_TEL_LS: 8 MCTM_LS
 SG_ ODI_CntrStck2TEL : 7|64@0+ (1,0) [0|1.84467440737096E+019] ""  CGM3a_LS

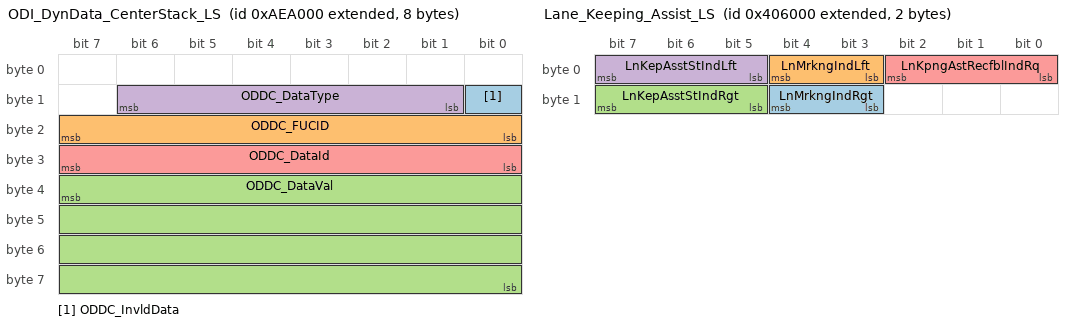
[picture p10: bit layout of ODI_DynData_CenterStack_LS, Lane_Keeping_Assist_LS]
BO_ 2158927872 ODI_DynData_CenterStack_LS: 8 MCTM_LS
 SG_ ODDC_InvldData : 8|1@0+ (1,0) [0|1] ""  MCTM_LS,CGM3a_LS
 SG_ ODDC_FUCID : 23|8@0+ (1,0) [0|255] ""  MCTM_LS,CGM3a_LS
 SG_ ODDC_DataVal : 39|32@0+ (1,0) [0|4294967295] ""  MCTM_LS,CGM3a_LS
 SG_ ODDC_DataType : 14|6@0+ (1,0) [0|63] ""  MCTM_LS,CGM3a_LS
 SG_ ODDC_DataId : 31|8@0+ (1,0) [0|255] ""  MCTM_LS,CGM3a_LS

BO_ 2151702528 Lane_Keeping_Assist_LS: 2 EOCM2cp_K2_LS
 SG_ LnMrkngIndRgt : 12|2@0+ (1,0) [0|3] ""  CGM3a_LS
 SG_ LnMrkngIndLft : 4|2@0+ (1,0) [0|3] ""  CGM3a_LS
 SG_ LnKepAsstStIndRgt : 15|3@0+ (1,0) [0|7] ""  CGM3a_LS
 SG_ LnKepAsstStIndLft : 7|3@0+ (1,0) [0|7] ""  CGM3a_LS
 SG_ LnKpngAstRecfblIndRq : 2|3@0+ (1,0) [0|7] ""  CGM3a_LS

BO_ 2155970560 HVAC_PowerManager_Status_LS: 1 ECC_LS
 SG_ ClmCntLdShdLvlRq : 3|4@0+ (1,0) [0|15] ""  CGM3a_LS
 SG_ ClmCntBatSaverIO : 5|1@0+ (1,0) [0|1] ""  CGM3a_LS

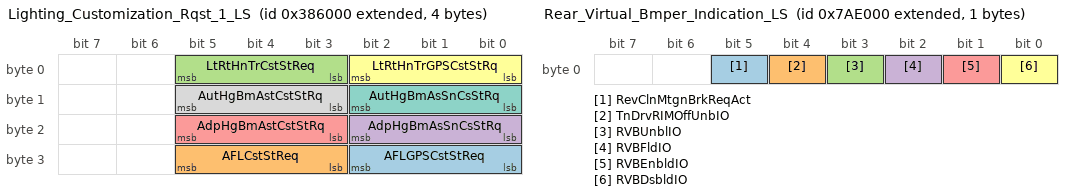
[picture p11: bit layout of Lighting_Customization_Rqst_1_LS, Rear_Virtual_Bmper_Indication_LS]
BO_ 2151178240 Lighting_Customization_Rqst_1_LS: 4 CGM3a_LS
 SG_ AFLGPSCstStReq : 26|3@0+ (1,0) [0|7] ""  EOCM2cp_K2_LS,BCM_LS
 SG_ AFLCstStReq : 29|3@0+ (1,0) [0|7] ""  BCM_LS,EOCM2cp_K2_LS
 SG_ LtRtHnTrCstStReq : 5|3@0+ (1,0) [0|7] ""  BCM_LS
 SG_ AdpHgBmAsSnCsStRq : 18|3@0+ (1,0) [0|7] ""  BCM_LS,EOCM2cp_K2_LS
 SG_ AdpHgBmAstCstStRq : 21|3@0+ (1,0) [0|7] ""  BCM_LS,EOCM2cp_K2_LS
 SG_ LtRtHnTrGPSCstStRq : 2|3@0+ (1,0) [0|7] ""  BCM_LS
 SG_ AutHgBmAsSnCsStRq : 10|3@0+ (1,0) [0|7] ""  BCM_LS,EOCM2cp_K2_LS
 SG_ AutHgBmAstCstStRq : 13|3@0+ (1,0) [0|7] ""  BCM_LS,EOCM2cp_K2_LS

BO_ 2152013824 Smart_High_Beam_Cust_LS: 1 EOCM2cp_K2_LS
 SG_ SmrtHgBmAstCstSetAvail : 4|1@0+ (1,0) [0|1] ""  CGM3a_LS
 SG_ SmrtHgBmAstCstCurrSetVal : 7|3@0+ (1,0) [0|7] ""  CGM3a_LS

BO_ 2155536384 Rear_Virtual_Bmper_Indication_LS: 1 EOCM2cp_K2_LS
 SG_ RevClnMtgnBrkReqAct : 5|1@0+ (1,0) [0|1] ""  CGM3a_LS
 SG_ TnDrvRIMOffUnbIO : 4|1@0+ (1,0) [0|1] ""  CGM3a_LS
 SG_ RVBUnblIO : 3|1@0+ (1,0) [0|1] ""  CGM3a_LS
 SG_ RVBFldIO : 2|1@0+ (1,0) [0|1] ""  CGM3a_LS
 SG_ RVBEnbldIO : 1|1@0+ (1,0) [0|1] ""  CGM3a_LS
 SG_ RVBDsbldIO : 0|1@0+ (1,0) [0|1] ""  CGM3a_LS

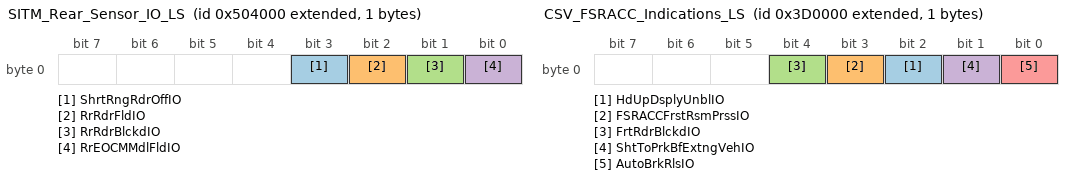
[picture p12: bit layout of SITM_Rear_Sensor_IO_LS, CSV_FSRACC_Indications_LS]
BO_ 2152742912 SITM_Rear_Sensor_IO_LS: 1 EOCM2cp_K2_LS
 SG_ ShrtRngRdrOffIO : 3|1@0+ (1,0) [0|1] ""  CGM3a_LS
 SG_ RrRdrFldIO : 2|1@0+ (1,0) [0|1] ""  CGM3a_LS
 SG_ RrRdrBlckdIO : 1|1@0+ (1,0) [0|1] ""  CGM3a_LS
 SG_ RrEOCMMdlFldIO : 0|1@0+ (1,0) [0|1] ""  CGM3a_LS

BO_ 2151481344 CSV_FSRACC_Indications_LS: 1 EOCM2cp_K2_LS
 SG_ HdUpDsplyUnblIO : 2|1@0+ (1,0) [0|1] ""  CGM3a_LS
 SG_ FSRACCFrstRsmPrssIO : 3|1@0+ (1,0) [0|1] ""  CGM3a_LS
 SG_ FrtRdrBlckdIO : 4|1@0+ (1,0) [0|1] ""  CGM3a_LS
 SG_ ShtToPrkBfExtngVehIO : 1|1@0+ (1,0) [0|1] ""  CGM3a_LS
 SG_ AutoBrkRlsIO : 0|1@0+ (1,0) [0|1] ""  CGM3a_LS

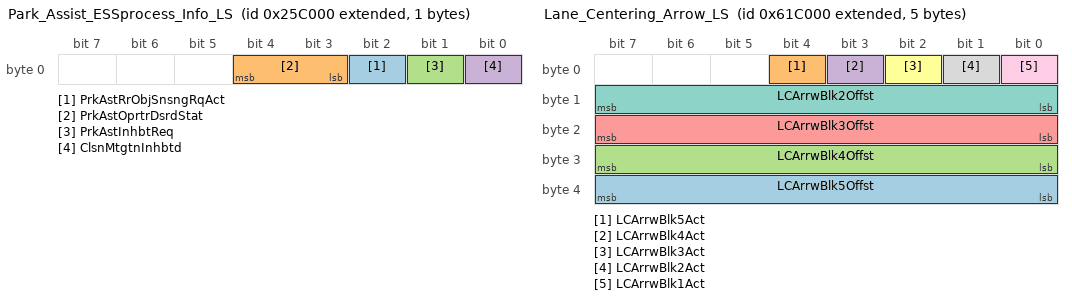
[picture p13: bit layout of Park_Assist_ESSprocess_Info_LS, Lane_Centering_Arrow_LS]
BO_ 2149957632 Park_Assist_ESSprocess_Info_LS: 1 EOCM2cp_K2_LS
 SG_ PrkAstRrObjSnsngRqAct : 2|1@0+ (1,0) [0|1] ""  CGM3a_LS,UPA_LS
 SG_ PrkAstOprtrDsrdStat : 4|2@0+ (1,0) [0|3] ""  CGM3a_LS,UPA_LS
 SG_ PrkAstInhbtReq : 1|1@0+ (1,0) [0|1] ""  CGM3a_LS,UPA_LS
 SG_ ClsnMtgtnInhbtd : 0|1@0+ (1,0) [0|1] ""  CGM3a_LS,UPA_LS

BO_ 2153889792 Lane_Centering_Arrow_LS: 5 EOCM2cp_K2_LS
 SG_ LCArrwBlk5Offst : 39|8@0- (1,0) [-128|127] ""  CGM3a_LS
 SG_ LCArrwBlk5Act : 4|1@0+ (1,0) [0|1] ""  CGM3a_LS
 SG_ LCArrwBlk4Offst : 31|8@0- (1,0) [-128|127] ""  CGM3a_LS
 SG_ LCArrwBlk4Act : 3|1@0+ (1,0) [0|1] ""  CGM3a_LS
 SG_ LCArrwBlk3Offst : 23|8@0- (1,0) [-128|127] ""  CGM3a_LS
 SG_ LCArrwBlk3Act : 2|1@0+ (1,0) [0|1] ""  CGM3a_LS
 SG_ LCArrwBlk2Offst : 15|8@0- (1,0) [-128|127] ""  CGM3a_LS
 SG_ LCArrwBlk2Act : 1|1@0+ (1,0) [0|1] ""  CGM3a_LS
 SG_ LCArrwBlk1Act : 0|1@0+ (1,0) [0|1] ""  CGM3a_LS

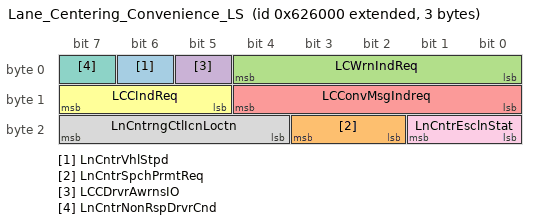
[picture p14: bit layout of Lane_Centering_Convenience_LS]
BO_ 2153930752 Lane_Centering_Convenience_LS: 3 EOCM2cp_K2_LS
 SG_ LnCntrVhlStpd : 6|1@0+ (1,0) [0|1] ""  CGM3a_LS
 SG_ LnCntrSpchPrmtReq : 19|2@0+ (1,0) [0|3] ""  CGM3a_LS
 SG_ LCWrnIndReq : 4|5@0+ (1,0) [0|31] ""  CGM3a_LS
 SG_ LCCDrvrAwrnsIO : 5|1@0+ (1,0) [0|1] ""  CGM3a_LS
 SG_ LCConvMsgIndreq : 12|5@0+ (1,0) [0|31] ""  CGM3a_LS
 SG_ LCCIndReq : 15|3@0+ (1,0) [0|7] ""  CGM3a_LS
 SG_ LnCntrNonRspDrvrCnd : 7|1@0+ (1,0) [0|1] ""  CGM3a_LS
 SG_ LnCntrngCtlIcnLoctn : 23|4@0- (1,0) [-8|7] ""  CGM3a_LS
 SG_ LnCntrEsclnStat : 17|2@0+ (1,0) [0|3] ""  CGM3a_LS

BO_TX_BU_ 2154725376 : BCM_LS,ECC_LS;
BO_TX_BU_ 2155028480 : EOCM2cp_K2_LS,UPA_LS;
BO_TX_BU_ 2034 : SAM_SR_LS,SAM_SL_LS,SAM_PR_LS,SAM_PL_LS;
BO_TX_BU_ 2158927872 : CGM3a_LS,MCTM_LS;
CM_ SG_ 2159132672 ODIAR_FUCID "ODI - Primary ID of Functional Unit in FU Database";
CM_ SG_ 2159132672 ODIAR_DspMID "ODI - ID that identifies the display requesting the data.  See detailed requirements in ODI GMLAN Protocol.";
CM_ SG_ 2159132672 ODIAR_ActnVal "ODI-Integer value for Actions with values.
FUDatabase definition of Action includes ActionDataType that defines whether or not Action has a value. 
For Actions without a value, this field is always sent as 0.";
CM_ SG_ 2159132672 ODIAR_ActnID "ODI-ActionId within the FUClass";
CM_ SG_ 2158960640 ODIIC_FUCID "ODI - Primary ID of Functional Unit in FU Database";
CM_ SG_ 2158977024 ODIEC_FUCID "ODI - Primary ID of Functional Unit in FU Database";
CM_ SG_ 2158977024 ODIEC_EvID "EventID within FUClass";
CM_ SG_ 2158944256 ODDLR_SubIdReqM "ODI-The number of list entries, starting at the Index, to send";
CM_ SG_ 2158944256 ODDLR_WrpArnd "ODI-Boolean that shall be set to true if the list shall wrap around.";
CM_ SG_ 2158944256 ODDLR_ReqType "ODI - Type of Request";
CM_ SG_ 2158944256 ODDLR_ReqDir "ODI-Boolean that shall be set to true if req down, set to false if set to up";
CM_ SG_ 2158944256 ODDLR_NmEntries "ODI-The number of list entries, starting at the Index, to send";
CM_ SG_ 2158944256 ODDLR_Idx "ODI-The index within the remote FU’s list at which to start sending data";
CM_ SG_ 2158944256 ODDLR_FUCID "ODI - Primary ID of Functional Unit in FU Database";
CM_ SG_ 2158944256 ODDLR_DspMID "ODI - ID that identifies the display requesting the data.  See detailed requirements in ODI GMLAN Protocol.";
CM_ SG_ 2158944256 ODDLR_DataId "ODI-Data Id for the dynamic list";
CM_ SG_ 2158944256 ODDLR_BckgndFlag "ODI-Informs FU as to priority of response.
Applies to all DataIds in the message.
$0=Immediate response required
$1=Background response";
CM_ SG_ 2151120896 FrtlftPsSeatOccSnsOpMd "TBD";
CM_ SG_ 2151120896 FrlftPsSeatOccFltSt "TBD";
CM_ SG_ 2154725376 AuxHtrAtv378 "Auxiliary Heater shall be used to denote a heater function that uses some kind of power, electrical or mechanical,  that was generated by the engine.";
CM_ SG_ 2154725376 AuxHtrRq "Auxiliary Heater shall be used to denote a heater function that uses some kind of power, electrical or mechanical,  that was generated by the engine.";
CM_ SG_ 2158927872 ODDC_InvldData "ODI";
CM_ SG_ 2158927872 ODDC_FUCID "ODI - Primary ID of Functional Unit in FU Database";
CM_ SG_ 2158927872 ODDC_DataVal "ODI";
CM_ SG_ 2158927872 ODDC_DataType "ODI";
CM_ SG_ 2158927872 ODDC_DataId "ODI-Data Id for the dynamic list";
CM_ BO_ 2151481344 "CAUTION!!!! BOTH GATED AND Tx ON LS!! DO NOT ADD ONLY GATED SIGNALS";
BA_DEF_ SG_  "VNSigPrimaryTriggering" ENUM  "No","Yes";
BA_DEF_ SG_  "VNSigRemoteDiagnostics" ENUM  "No","Yes";
BA_DEF_ SG_  "VNSigInfotainment" ENUM  "No","Yes";
BA_DEF_ SG_  "VNSigParkedVehicle" ENUM  "No","Yes";
BA_DEF_ SG_  "VNSigIntermediate" ENUM  "No","Yes";
BA_DEF_ SG_  "VNSigUnused_4" ENUM  "No","Yes";
BA_DEF_ SG_  "SignalType" STRING ;
BA_DEF_ SG_  "PacketOrder" INT 0 65535;
BA_DEF_ SG_  "SignalLongName" STRING ;
BA_DEF_ SG_  "GenSigStartValue" INT 0 65535;
BA_DEF_ SG_  "VNSigDiagnostic" ENUM  "No","Yes";
BA_DEF_ SG_  "VNSigAllNodes" ENUM  "No","Yes";
BA_DEF_ SG_  "GenSigDeltaValue" INT 0 0;
BA_DEF_ SG_  "GenSigSendType" ENUM  "not used","not used","not used","not used","not used","not used","not used","NoSigSendType","not used","not used","OnAnyChange","OnChangeIfActive","OnDelta";
BA_DEF_ SG_  "GenSigSendOnInit" ENUM  "Not Initialized","Application","Handler";
BA_DEF_ BO_  "AppGenMsgCycleTime" INT 0 0;
BA_DEF_ BO_  "TpTxIndex" INT 0 99;
BA_DEF_ BO_  "GenMsgILSupport" ENUM  "No","Yes";
BA_DEF_ BO_  "TpApplType" STRING ;
BA_DEF_ BO_  "Prio" INT 0 7;
BA_DEF_ BO_  "MessageSubnet" ENUM  "LS","HS","CE","PE","HV","FO","LE","HE2","PHS","PCE","DLCLS","DLCHS","DLCCE","DLCFO";
BA_DEF_ BO_  "GenMsgMandatoryToSupervision" ENUM  "No","Yes";
BA_DEF_ BO_  "DiagState" ENUM  "No","Yes";
BA_DEF_ BO_  "GenMsgStartDelayTime" INT 0 100000;
BA_DEF_ BO_  "GenMsgDelayTime" INT 0 100000;
BA_DEF_ BO_  "GenMsgCycleTime" INT 0 100000;
BA_DEF_ BO_  "GenMsgCycleTimeFast" INT 0 100000;
BA_DEF_ BO_  "GenMsgSendType" ENUM  "cyclicX","spontanX","cyclicIfActiveX","spontanWithDelay","cyclicAndSpontanX","cyclicAndSpontanWithDelay","spontanWithRepitition","cyclicIfActiveAndSpontanWD";
BA_DEF_ BO_  "DiagResponse" ENUM  "No","Yes";
BA_DEF_ BO_  "DiagRequest" ENUM  "No","Yes";
BA_DEF_ BO_  "NmMessage" ENUM  "No","Yes";
BA_DEF_REL_ BU_SG_REL_  "GenSigSuprvRespComment" STRING ;
BA_DEF_REL_ BU_SG_REL_  "GenSigVBitResp" ENUM  "No","Yes";
BA_DEF_REL_ BU_SG_REL_  "GenSigVBitRespComment" STRING ;
BA_DEF_REL_ BU_SG_REL_  "GenSigVDAFailComment" STRING ;
BA_DEF_REL_ BU_SG_REL_  "GenSigVDAFailResp" ENUM  "No","Yes";
BA_DEF_REL_ BU_SG_REL_  "GenSigRxStartValue" STRING ;
BA_DEF_REL_ BU_SG_REL_  "GenSigSuprvRespSubValue" INT 0 65535;
BA_DEF_REL_ BU_SG_REL_  "GenSigSuprvResp" ENUM  "None","Notify App","Substitute Default";
BA_DEF_REL_ BU_SG_REL_  "GenSigTimeoutMsg" HEX 0 268435455;
BA_DEF_REL_ BU_SG_REL_  "GenSigTimeoutTime" INT 0 15000;
BA_DEF_DEF_  "VNSigPrimaryTriggering" "No";
BA_DEF_DEF_  "VNSigRemoteDiagnostics" "No";
BA_DEF_DEF_  "VNSigInfotainment" "No";
BA_DEF_DEF_  "VNSigParkedVehicle" "No";
BA_DEF_DEF_  "VNSigIntermediate" "No";
BA_DEF_DEF_  "VNSigUnused_4" "No";
BA_DEF_DEF_  "SignalType" "";
BA_DEF_DEF_  "PacketOrder" 0;
BA_DEF_DEF_  "SignalLongName" "";
BA_DEF_DEF_  "GenSigStartValue" 0;
BA_DEF_DEF_  "VNSigDiagnostic" "No";
BA_DEF_DEF_  "VNSigAllNodes" "No";
BA_DEF_DEF_  "GenSigDeltaValue" 0;
BA_DEF_DEF_  "GenSigSendType" "NoSigSendType";
BA_DEF_DEF_  "GenSigSendOnInit" "Not Initialized";
BA_DEF_DEF_  "AppGenMsgCycleTime" 0;
BA_DEF_DEF_  "TpTxIndex" 0;
BA_DEF_DEF_  "GenMsgILSupport" "Yes";
BA_DEF_DEF_  "TpApplType" "";
BA_DEF_DEF_  "Prio" 4;
BA_DEF_DEF_  "MessageSubnet" "LS";
BA_DEF_DEF_  "GenMsgMandatoryToSupervision" "No";
BA_DEF_DEF_  "DiagState" "No";
BA_DEF_DEF_  "GenMsgStartDelayTime" 0;
BA_DEF_DEF_  "GenMsgDelayTime" 0;
BA_DEF_DEF_  "GenMsgCycleTime" 0;
BA_DEF_DEF_  "GenMsgCycleTimeFast" 0;
BA_DEF_DEF_  "GenMsgSendType" "spontanX";
BA_DEF_DEF_  "DiagResponse" "No";
BA_DEF_DEF_  "DiagRequest" "No";
BA_DEF_DEF_  "NmMessage" "No";
BA_DEF_DEF_REL_ "GenSigSuprvRespComment" "";
BA_DEF_DEF_REL_ "GenSigVBitResp" "No";
BA_DEF_DEF_REL_ "GenSigVBitRespComment" "";
BA_DEF_DEF_REL_ "GenSigVDAFailComment" "";
BA_DEF_DEF_REL_ "GenSigVDAFailResp" "No";
BA_DEF_DEF_REL_ "GenSigRxStartValue" "";
BA_DEF_DEF_REL_ "GenSigSuprvRespSubValue" 0;
BA_DEF_DEF_REL_ "GenSigSuprvResp" "None";
BA_DEF_DEF_REL_ "GenSigTimeoutMsg" 0;
BA_DEF_DEF_REL_ "GenSigTimeoutTime" 0;
BA_ "GenMsgDelayTime" BO_ 2159132672 20;
BA_ "GenMsgDelayTime" BO_ 2158968832 10;
BA_ "GenMsgDelayTime" BO_ 2158895104 10;
BA_ "GenMsgDelayTime" BO_ 2158960640 100;
BA_ "GenMsgDelayTime" BO_ 2158977024 100;
BA_ "GenMsgDelayTime" BO_ 2158944256 20;
BA_ "GenMsgDelayTime" BO_ 2151120896 100;
BA_ "GenMsgDelayTime" BO_ 2154332160 100;
BA_ "GenMsgDelayTime" BO_ 2154414080 100;
BA_ "GenMsgDelayTime" BO_ 2154397696 100;
BA_ "TpTxIndex" BO_ 2154536960 3;
BA_ "TpTxIndex" BO_ 2154545152 2;
BA_ "TpTxIndex" BO_ 2154504192 1;
BA_ "GenMsgDelayTime" BO_ 2154463232 100;
BA_ "GenMsgDelayTime" BO_ 2154446848 100;
BA_ "GenMsgILSupport" BO_ 1347 0;
BA_ "TpApplType" BO_ 1347 "DiagUUDTResponse";
BA_ "Prio" BO_ 1347 0;
BA_ "GenMsgCycleTime" BO_ 2152177664 2000;
BA_ "GenMsgSendType" BO_ 2152177664 0;
BA_ "GenMsgDelayTime" BO_ 2150531072 100;
BA_ "Prio" BO_ 856 0;
BA_ "DiagResponse" BO_ 856 1;
BA_ "Prio" BO_ 921 0;
BA_ "DiagResponse" BO_ 921 1;
BA_ "Prio" BO_ 88 0;
BA_ "DiagRequest" BO_ 88 1;
BA_ "Prio" BO_ 153 0;
BA_ "DiagRequest" BO_ 153 1;
BA_ "GenMsgDelayTime" BO_ 2159255552 10;
BA_ "GenMsgDelayTime" BO_ 2159247360 10;
BA_ "GenMsgDelayTime" BO_ 2154725376 100;
BA_ "GenMsgDelayTime" BO_ 2158133248 100;
BA_ "GenMsgDelayTime" BO_ 2151931904 100;
BA_ "GenMsgDelayTime" BO_ 2150244352 100;
BA_ "Prio" BO_ 579 0;
BA_ "DiagRequest" BO_ 579 1;
BA_ "GenMsgDelayTime" BO_ 2155028480 100;
BA_ "GenMsgCycleTime" BO_ 2151915520 250;
BA_ "GenMsgSendType" BO_ 2151915520 0;
BA_ "GenMsgStartDelayTime" BO_ 2155364352 10;
BA_ "GenMsgDelayTime" BO_ 2155364352 100;
BA_ "GenMsgCycleTime" BO_ 2155364352 250;
BA_ "Prio" BO_ 2150260736 0;
BA_ "GenMsgCycleTime" BO_ 2150260736 100;
BA_ "GenMsgSendType" BO_ 2150260736 0;
BA_ "GenMsgDelayTime" BO_ 2152562688 100;
BA_ "GenMsgDelayTime" BO_ 2152112128 100;
BA_ "GenMsgDelayTime" BO_ 2153857024 100;
BA_ "GenMsgDelayTime" BO_ 2153865216 100;
BA_ "GenMsgDelayTime" BO_ 2153840640 100;
BA_ "GenMsgDelayTime" BO_ 2153824256 100;
BA_ "GenMsgDelayTime" BO_ 2150252544 100;
BA_ "GenMsgDelayTime" BO_ 2150391808 100;
BA_ "GenMsgCycleTime" BO_ 2155913216 1000;
BA_ "GenMsgSendType" BO_ 2155913216 0;
BA_ "Prio" BO_ 2034 0;
BA_ "DiagResponse" BO_ 2034 1;
BA_ "Prio" BO_ 2032 0;
BA_ "DiagRequest" BO_ 2032 1;
BA_ "Prio" BO_ 2150236160 0;
BA_ "GenMsgCycleTime" BO_ 2150236160 100;
BA_ "GenMsgSendType" BO_ 2150236160 0;
BA_ "GenMsgDelayTime" BO_ 2159157248 10;
BA_ "GenMsgDelayTime" BO_ 2158927872 100;
BA_ "GenMsgDelayTime" BO_ 2151702528 100;
BA_ "GenMsgDelayTime" BO_ 2155970560 100;
BA_ "GenMsgDelayTime" BO_ 2151178240 100;
BA_ "GenMsgDelayTime" BO_ 2152013824 100;
BA_ "GenMsgDelayTime" BO_ 2155536384 100;
BA_ "GenMsgDelayTime" BO_ 2152742912 100;
BA_ "GenMsgCycleTime" BO_ 2151481344 200;
BA_ "GenMsgSendType" BO_ 2151481344 0;
BA_ "GenMsgDelayTime" BO_ 2149957632 100;
BA_ "AppGenMsgCycleTime" BO_ 2153889792 250;
BA_ "GenMsgDelayTime" BO_ 2153889792 100;
BA_ "GenMsgDelayTime" BO_ 2153930752 100;
BA_ "SignalType" SG_ 2159132672 ODIAR_FUCID "UNM";
BA_ "PacketOrder" SG_ 2159132672 ODIAR_FUCID 2;
BA_ "SignalLongName" SG_ 2159132672 ODIAR_FUCID "Open Display Interface Action Rear Seat Display : FU Class ID";
BA_ "VNSigAllNodes" SG_ 2159132672 ODIAR_FUCID 1;
BA_ "SignalType" SG_ 2159132672 ODIAR_DspMID "ENM";
BA_ "PacketOrder" SG_ 2159132672 ODIAR_DspMID 4;
BA_ "SignalLongName" SG_ 2159132672 ODIAR_DspMID "Open Display Interface Action Rear Seat Display : Display Mask ID";
BA_ "VNSigAllNodes" SG_ 2159132672 ODIAR_DspMID 1;
BA_ "SignalType" SG_ 2159132672 ODIAR_DaTy "ENM";
BA_ "PacketOrder" SG_ 2159132672 ODIAR_DaTy 1;
BA_ "SignalLongName" SG_ 2159132672 ODIAR_DaTy "Open Display Interface Action Rear Seat Display : DataType";
BA_ "VNSigAllNodes" SG_ 2159132672 ODIAR_DaTy 1;
BA_ "SignalType" SG_ 2159132672 ODIAR_ActnVal "UNM";
BA_ "PacketOrder" SG_ 2159132672 ODIAR_ActnVal 5;
BA_ "SignalLongName" SG_ 2159132672 ODIAR_ActnVal "Open Display Interface Action Rear Seat Display : Action Value";
BA_ "VNSigAllNodes" SG_ 2159132672 ODIAR_ActnVal 1;
BA_ "SignalType" SG_ 2159132672 ODIAR_ActnID "UNM";
BA_ "PacketOrder" SG_ 2159132672 ODIAR_ActnID 3;
BA_ "SignalLongName" SG_ 2159132672 ODIAR_ActnID "Open Display Interface Action Rear Seat Display : Action ID";
BA_ "VNSigAllNodes" SG_ 2159132672 ODIAR_ActnID 1;
BA_ "GenSigDeltaValue" SG_ 2158968832 ODI_RSD2CntrStck 1;
BA_ "SignalType" SG_ 2158968832 ODI_RSD2CntrStck "UNM";
BA_ "SignalLongName" SG_ 2158968832 ODI_RSD2CntrStck "Open Display Interface Rear Seat Display 2 Centerstack";
BA_ "VNSigAllNodes" SG_ 2158968832 ODI_RSD2CntrStck 1;
BA_ "GenSigDeltaValue" SG_ 2158895104 ODI_CntrStck2RSD 1;
BA_ "SignalType" SG_ 2158895104 ODI_CntrStck2RSD "UNM";
BA_ "SignalLongName" SG_ 2158895104 ODI_CntrStck2RSD "Open Display Interface Centerstack 2 Rear Seat Display";
BA_ "VNSigAllNodes" SG_ 2158895104 ODI_CntrStck2RSD 1;
BA_ "VNSigInfotainment" SG_ 2158960640 ODIIC_FUCID 1;
BA_ "SignalType" SG_ 2158960640 ODIIC_FUCID "UNM";
BA_ "PacketOrder" SG_ 2158960640 ODIIC_FUCID 1;
BA_ "SignalLongName" SG_ 2158960640 ODIIC_FUCID "Open Display Interface Indication Centerstack: Functional Unit Class ID";
BA_ "VNSigAllNodes" SG_ 2158960640 ODIIC_FUCID 1;
BA_ "VNSigInfotainment" SG_ 2158960640 ODIIC_ODIInd9 1;
BA_ "SignalType" SG_ 2158960640 ODIIC_ODIInd9 "BLN";
BA_ "PacketOrder" SG_ 2158960640 ODIIC_ODIInd9 10;
BA_ "SignalLongName" SG_ 2158960640 ODIIC_ODIInd9 "Open Display Interface Indication Centerstack : Open Display Interface Indication 9";
BA_ "VNSigAllNodes" SG_ 2158960640 ODIIC_ODIInd9 1;
BA_ "VNSigInfotainment" SG_ 2158960640 ODIIC_ODIInd8 1;
BA_ "SignalType" SG_ 2158960640 ODIIC_ODIInd8 "BLN";
BA_ "PacketOrder" SG_ 2158960640 ODIIC_ODIInd8 9;
BA_ "SignalLongName" SG_ 2158960640 ODIIC_ODIInd8 "Open Display Interface Indication Centerstack : Open Display Interface Indication 8";
BA_ "VNSigAllNodes" SG_ 2158960640 ODIIC_ODIInd8 1;
BA_ "VNSigInfotainment" SG_ 2158960640 ODIIC_ODIInd7 1;
BA_ "SignalType" SG_ 2158960640 ODIIC_ODIInd7 "BLN";
BA_ "PacketOrder" SG_ 2158960640 ODIIC_ODIInd7 8;
BA_ "SignalLongName" SG_ 2158960640 ODIIC_ODIInd7 "Open Display Interface Indication Centerstack : Open Display Interface Indication 7";
BA_ "VNSigAllNodes" SG_ 2158960640 ODIIC_ODIInd7 1;
BA_ "VNSigInfotainment" SG_ 2158960640 ODIIC_ODIInd6 1;
BA_ "SignalType" SG_ 2158960640 ODIIC_ODIInd6 "BLN";
BA_ "PacketOrder" SG_ 2158960640 ODIIC_ODIInd6 7;
BA_ "SignalLongName" SG_ 2158960640 ODIIC_ODIInd6 "Open Display Interface Indication Centerstack : Open Display Interface Indication 6";
BA_ "VNSigAllNodes" SG_ 2158960640 ODIIC_ODIInd6 1;
BA_ "VNSigInfotainment" SG_ 2158960640 ODIIC_ODIInd56 1;
BA_ "SignalType" SG_ 2158960640 ODIIC_ODIInd56 "BLN";
BA_ "PacketOrder" SG_ 2158960640 ODIIC_ODIInd56 57;
BA_ "SignalLongName" SG_ 2158960640 ODIIC_ODIInd56 "Open Display Interface Indication Centerstack : Open Display Interface Indication 56";
BA_ "VNSigAllNodes" SG_ 2158960640 ODIIC_ODIInd56 1;
BA_ "VNSigInfotainment" SG_ 2158960640 ODIIC_ODIInd55 1;
BA_ "SignalType" SG_ 2158960640 ODIIC_ODIInd55 "BLN";
BA_ "PacketOrder" SG_ 2158960640 ODIIC_ODIInd55 56;
BA_ "SignalLongName" SG_ 2158960640 ODIIC_ODIInd55 "Open Display Interface Indication Centerstack : Open Display Interface Indication 55";
BA_ "VNSigAllNodes" SG_ 2158960640 ODIIC_ODIInd55 1;
BA_ "VNSigInfotainment" SG_ 2158960640 ODIIC_ODIInd54 1;
BA_ "SignalType" SG_ 2158960640 ODIIC_ODIInd54 "BLN";
BA_ "PacketOrder" SG_ 2158960640 ODIIC_ODIInd54 55;
BA_ "SignalLongName" SG_ 2158960640 ODIIC_ODIInd54 "Open Display Interface Indication Centerstack : Open Display Interface Indication 54";
BA_ "VNSigAllNodes" SG_ 2158960640 ODIIC_ODIInd54 1;
BA_ "VNSigInfotainment" SG_ 2158960640 ODIIC_ODIInd53 1;
BA_ "SignalType" SG_ 2158960640 ODIIC_ODIInd53 "BLN";
BA_ "PacketOrder" SG_ 2158960640 ODIIC_ODIInd53 54;
BA_ "SignalLongName" SG_ 2158960640 ODIIC_ODIInd53 "Open Display Interface Indication Centerstack : Open Display Interface Indication 53";
BA_ "VNSigAllNodes" SG_ 2158960640 ODIIC_ODIInd53 1;
BA_ "VNSigInfotainment" SG_ 2158960640 ODIIC_ODIInd52 1;
BA_ "SignalType" SG_ 2158960640 ODIIC_ODIInd52 "BLN";
BA_ "PacketOrder" SG_ 2158960640 ODIIC_ODIInd52 53;
BA_ "SignalLongName" SG_ 2158960640 ODIIC_ODIInd52 "Open Display Interface Indication Centerstack : Open Display Interface Indication 52";
BA_ "VNSigAllNodes" SG_ 2158960640 ODIIC_ODIInd52 1;
BA_ "VNSigInfotainment" SG_ 2158960640 ODIIC_ODIInd51 1;
BA_ "SignalType" SG_ 2158960640 ODIIC_ODIInd51 "BLN";
BA_ "PacketOrder" SG_ 2158960640 ODIIC_ODIInd51 52;
BA_ "SignalLongName" SG_ 2158960640 ODIIC_ODIInd51 "Open Display Interface Indication Centerstack : Open Display Interface Indication 51";
BA_ "VNSigAllNodes" SG_ 2158960640 ODIIC_ODIInd51 1;
BA_ "VNSigInfotainment" SG_ 2158960640 ODIIC_ODIInd50 1;
BA_ "SignalType" SG_ 2158960640 ODIIC_ODIInd50 "BLN";
BA_ "PacketOrder" SG_ 2158960640 ODIIC_ODIInd50 51;
BA_ "SignalLongName" SG_ 2158960640 ODIIC_ODIInd50 "Open Display Interface Indication Centerstack : Open Display Interface Indication 50";
BA_ "VNSigAllNodes" SG_ 2158960640 ODIIC_ODIInd50 1;
BA_ "VNSigInfotainment" SG_ 2158960640 ODIIC_ODIInd5 1;
BA_ "SignalType" SG_ 2158960640 ODIIC_ODIInd5 "BLN";
BA_ "PacketOrder" SG_ 2158960640 ODIIC_ODIInd5 6;
BA_ "SignalLongName" SG_ 2158960640 ODIIC_ODIInd5 "Open Display Interface Indication Centerstack : Open Display Interface Indication 5";
BA_ "VNSigAllNodes" SG_ 2158960640 ODIIC_ODIInd5 1;
BA_ "VNSigInfotainment" SG_ 2158960640 ODIIC_ODIInd49 1;
BA_ "SignalType" SG_ 2158960640 ODIIC_ODIInd49 "BLN";
BA_ "PacketOrder" SG_ 2158960640 ODIIC_ODIInd49 50;
BA_ "SignalLongName" SG_ 2158960640 ODIIC_ODIInd49 "Open Display Interface Indication Centerstack : Open Display Interface Indication 49";
BA_ "VNSigAllNodes" SG_ 2158960640 ODIIC_ODIInd49 1;
BA_ "VNSigInfotainment" SG_ 2158960640 ODIIC_ODIInd48 1;
BA_ "SignalType" SG_ 2158960640 ODIIC_ODIInd48 "BLN";
BA_ "PacketOrder" SG_ 2158960640 ODIIC_ODIInd48 49;
BA_ "SignalLongName" SG_ 2158960640 ODIIC_ODIInd48 "Open Display Interface Indication Centerstack : Open Display Interface Indication 48";
BA_ "VNSigAllNodes" SG_ 2158960640 ODIIC_ODIInd48 1;
BA_ "VNSigInfotainment" SG_ 2158960640 ODIIC_ODIInd47 1;
BA_ "SignalType" SG_ 2158960640 ODIIC_ODIInd47 "BLN";
BA_ "PacketOrder" SG_ 2158960640 ODIIC_ODIInd47 48;
BA_ "SignalLongName" SG_ 2158960640 ODIIC_ODIInd47 "Open Display Interface Indication Centerstack : Open Display Interface Indication 47";
BA_ "VNSigAllNodes" SG_ 2158960640 ODIIC_ODIInd47 1;
BA_ "VNSigInfotainment" SG_ 2158960640 ODIIC_ODIInd46 1;
BA_ "SignalType" SG_ 2158960640 ODIIC_ODIInd46 "BLN";
BA_ "PacketOrder" SG_ 2158960640 ODIIC_ODIInd46 47;
BA_ "SignalLongName" SG_ 2158960640 ODIIC_ODIInd46 "Open Display Interface Indication Centerstack : Open Display Interface Indication 46";
BA_ "VNSigAllNodes" SG_ 2158960640 ODIIC_ODIInd46 1;
BA_ "VNSigInfotainment" SG_ 2158960640 ODIIC_ODIInd45 1;
BA_ "SignalType" SG_ 2158960640 ODIIC_ODIInd45 "BLN";
BA_ "PacketOrder" SG_ 2158960640 ODIIC_ODIInd45 46;
BA_ "SignalLongName" SG_ 2158960640 ODIIC_ODIInd45 "Open Display Interface Indication Centerstack : Open Display Interface Indication 45";
BA_ "VNSigAllNodes" SG_ 2158960640 ODIIC_ODIInd45 1;
BA_ "VNSigInfotainment" SG_ 2158960640 ODIIC_ODIInd44 1;
BA_ "SignalType" SG_ 2158960640 ODIIC_ODIInd44 "BLN";
BA_ "PacketOrder" SG_ 2158960640 ODIIC_ODIInd44 45;
BA_ "SignalLongName" SG_ 2158960640 ODIIC_ODIInd44 "Open Display Interface Indication Centerstack : Open Display Interface Indication 44";
BA_ "VNSigAllNodes" SG_ 2158960640 ODIIC_ODIInd44 1;
BA_ "VNSigInfotainment" SG_ 2158960640 ODIIC_ODIInd43 1;
BA_ "SignalType" SG_ 2158960640 ODIIC_ODIInd43 "BLN";
BA_ "PacketOrder" SG_ 2158960640 ODIIC_ODIInd43 44;
BA_ "SignalLongName" SG_ 2158960640 ODIIC_ODIInd43 "Open Display Interface Indication Centerstack : Open Display Interface Indication 43";
BA_ "VNSigAllNodes" SG_ 2158960640 ODIIC_ODIInd43 1;
BA_ "VNSigInfotainment" SG_ 2158960640 ODIIC_ODIInd42 1;
BA_ "SignalType" SG_ 2158960640 ODIIC_ODIInd42 "BLN";
BA_ "PacketOrder" SG_ 2158960640 ODIIC_ODIInd42 43;
BA_ "SignalLongName" SG_ 2158960640 ODIIC_ODIInd42 "Open Display Interface Indication Centerstack : Open Display Interface Indication 42";
BA_ "VNSigAllNodes" SG_ 2158960640 ODIIC_ODIInd42 1;
BA_ "VNSigInfotainment" SG_ 2158960640 ODIIC_ODIInd41 1;
BA_ "SignalType" SG_ 2158960640 ODIIC_ODIInd41 "BLN";
BA_ "PacketOrder" SG_ 2158960640 ODIIC_ODIInd41 42;
BA_ "SignalLongName" SG_ 2158960640 ODIIC_ODIInd41 "Open Display Interface Indication Centerstack : Open Display Interface Indication 41";
BA_ "VNSigAllNodes" SG_ 2158960640 ODIIC_ODIInd41 1;
BA_ "VNSigInfotainment" SG_ 2158960640 ODIIC_ODIInd40 1;
BA_ "SignalType" SG_ 2158960640 ODIIC_ODIInd40 "BLN";
BA_ "PacketOrder" SG_ 2158960640 ODIIC_ODIInd40 41;
BA_ "SignalLongName" SG_ 2158960640 ODIIC_ODIInd40 "Open Display Interface Indication Centerstack : Open Display Interface Indication 40";
BA_ "VNSigAllNodes" SG_ 2158960640 ODIIC_ODIInd40 1;
BA_ "VNSigInfotainment" SG_ 2158960640 ODIIC_ODIInd4 1;
BA_ "SignalType" SG_ 2158960640 ODIIC_ODIInd4 "BLN";
BA_ "PacketOrder" SG_ 2158960640 ODIIC_ODIInd4 5;
BA_ "SignalLongName" SG_ 2158960640 ODIIC_ODIInd4 "Open Display Interface Indication Centerstack : Open Display Interface Indication 4";
BA_ "VNSigAllNodes" SG_ 2158960640 ODIIC_ODIInd4 1;
BA_ "VNSigInfotainment" SG_ 2158960640 ODIIC_ODIInd39 1;
BA_ "SignalType" SG_ 2158960640 ODIIC_ODIInd39 "BLN";
BA_ "PacketOrder" SG_ 2158960640 ODIIC_ODIInd39 40;
BA_ "SignalLongName" SG_ 2158960640 ODIIC_ODIInd39 "Open Display Interface Indication Centerstack : Open Display Interface Indication 39";
BA_ "VNSigAllNodes" SG_ 2158960640 ODIIC_ODIInd39 1;
BA_ "VNSigInfotainment" SG_ 2158960640 ODIIC_ODIInd38 1;
BA_ "SignalType" SG_ 2158960640 ODIIC_ODIInd38 "BLN";
BA_ "PacketOrder" SG_ 2158960640 ODIIC_ODIInd38 39;
BA_ "SignalLongName" SG_ 2158960640 ODIIC_ODIInd38 "Open Display Interface Indication Centerstack : Open Display Interface Indication 38";
BA_ "VNSigAllNodes" SG_ 2158960640 ODIIC_ODIInd38 1;
BA_ "VNSigInfotainment" SG_ 2158960640 ODIIC_ODIInd37 1;
BA_ "SignalType" SG_ 2158960640 ODIIC_ODIInd37 "BLN";
BA_ "PacketOrder" SG_ 2158960640 ODIIC_ODIInd37 38;
BA_ "SignalLongName" SG_ 2158960640 ODIIC_ODIInd37 "Open Display Interface Indication Centerstack : Open Display Interface Indication 37";
BA_ "VNSigAllNodes" SG_ 2158960640 ODIIC_ODIInd37 1;
BA_ "VNSigInfotainment" SG_ 2158960640 ODIIC_ODIInd36 1;
BA_ "SignalType" SG_ 2158960640 ODIIC_ODIInd36 "BLN";
BA_ "PacketOrder" SG_ 2158960640 ODIIC_ODIInd36 37;
BA_ "SignalLongName" SG_ 2158960640 ODIIC_ODIInd36 "Open Display Interface Indication Centerstack : Open Display Interface Indication 36";
BA_ "VNSigAllNodes" SG_ 2158960640 ODIIC_ODIInd36 1;
BA_ "VNSigInfotainment" SG_ 2158960640 ODIIC_ODIInd35 1;
BA_ "SignalType" SG_ 2158960640 ODIIC_ODIInd35 "BLN";
BA_ "PacketOrder" SG_ 2158960640 ODIIC_ODIInd35 36;
BA_ "SignalLongName" SG_ 2158960640 ODIIC_ODIInd35 "Open Display Interface Indication Centerstack : Open Display Interface Indication 35";
BA_ "VNSigAllNodes" SG_ 2158960640 ODIIC_ODIInd35 1;
BA_ "VNSigInfotainment" SG_ 2158960640 ODIIC_ODIInd34 1;
BA_ "SignalType" SG_ 2158960640 ODIIC_ODIInd34 "BLN";
BA_ "PacketOrder" SG_ 2158960640 ODIIC_ODIInd34 35;
BA_ "SignalLongName" SG_ 2158960640 ODIIC_ODIInd34 "Open Display Interface Indication Centerstack : Open Display Interface Indication 34";
BA_ "VNSigAllNodes" SG_ 2158960640 ODIIC_ODIInd34 1;
BA_ "VNSigInfotainment" SG_ 2158960640 ODIIC_ODIInd33 1;
BA_ "SignalType" SG_ 2158960640 ODIIC_ODIInd33 "BLN";
BA_ "PacketOrder" SG_ 2158960640 ODIIC_ODIInd33 34;
BA_ "SignalLongName" SG_ 2158960640 ODIIC_ODIInd33 "Open Display Interface Indication Centerstack : Open Display Interface Indication 33";
BA_ "VNSigAllNodes" SG_ 2158960640 ODIIC_ODIInd33 1;
BA_ "VNSigInfotainment" SG_ 2158960640 ODIIC_ODIInd32 1;
BA_ "SignalType" SG_ 2158960640 ODIIC_ODIInd32 "BLN";
BA_ "PacketOrder" SG_ 2158960640 ODIIC_ODIInd32 33;
BA_ "SignalLongName" SG_ 2158960640 ODIIC_ODIInd32 "Open Display Interface Indication Centerstack : Open Display Interface Indication 32";
BA_ "VNSigAllNodes" SG_ 2158960640 ODIIC_ODIInd32 1;
BA_ "VNSigInfotainment" SG_ 2158960640 ODIIC_ODIInd31 1;
BA_ "SignalType" SG_ 2158960640 ODIIC_ODIInd31 "BLN";
BA_ "PacketOrder" SG_ 2158960640 ODIIC_ODIInd31 32;
BA_ "SignalLongName" SG_ 2158960640 ODIIC_ODIInd31 "Open Display Interface Indication Centerstack : Open Display Interface Indication 31";
BA_ "VNSigAllNodes" SG_ 2158960640 ODIIC_ODIInd31 1;
BA_ "VNSigInfotainment" SG_ 2158960640 ODIIC_ODIInd30 1;
BA_ "SignalType" SG_ 2158960640 ODIIC_ODIInd30 "BLN";
BA_ "PacketOrder" SG_ 2158960640 ODIIC_ODIInd30 31;
BA_ "SignalLongName" SG_ 2158960640 ODIIC_ODIInd30 "Open Display Interface Indication Centerstack : Open Display Interface Indication 30";
BA_ "VNSigAllNodes" SG_ 2158960640 ODIIC_ODIInd30 1;
BA_ "VNSigInfotainment" SG_ 2158960640 ODIIC_ODIInd3 1;
BA_ "SignalType" SG_ 2158960640 ODIIC_ODIInd3 "BLN";
BA_ "PacketOrder" SG_ 2158960640 ODIIC_ODIInd3 4;
BA_ "SignalLongName" SG_ 2158960640 ODIIC_ODIInd3 "Open Display Interface Indication Centerstack : Open Display Interface Indication 3";
BA_ "VNSigAllNodes" SG_ 2158960640 ODIIC_ODIInd3 1;
BA_ "VNSigInfotainment" SG_ 2158960640 ODIIC_ODIInd29 1;
BA_ "SignalType" SG_ 2158960640 ODIIC_ODIInd29 "BLN";
BA_ "PacketOrder" SG_ 2158960640 ODIIC_ODIInd29 30;
BA_ "SignalLongName" SG_ 2158960640 ODIIC_ODIInd29 "Open Display Interface Indication Centerstack : Open Display Interface Indication 29";
BA_ "VNSigAllNodes" SG_ 2158960640 ODIIC_ODIInd29 1;
BA_ "VNSigInfotainment" SG_ 2158960640 ODIIC_ODIInd28 1;
BA_ "SignalType" SG_ 2158960640 ODIIC_ODIInd28 "BLN";
BA_ "PacketOrder" SG_ 2158960640 ODIIC_ODIInd28 29;
BA_ "SignalLongName" SG_ 2158960640 ODIIC_ODIInd28 "Open Display Interface Indication Centerstack : Open Display Interface Indication 28";
BA_ "VNSigAllNodes" SG_ 2158960640 ODIIC_ODIInd28 1;
BA_ "VNSigInfotainment" SG_ 2158960640 ODIIC_ODIInd27 1;
BA_ "SignalType" SG_ 2158960640 ODIIC_ODIInd27 "BLN";
BA_ "PacketOrder" SG_ 2158960640 ODIIC_ODIInd27 28;
BA_ "SignalLongName" SG_ 2158960640 ODIIC_ODIInd27 "Open Display Interface Indication Centerstack : Open Display Interface Indication 27";
BA_ "VNSigAllNodes" SG_ 2158960640 ODIIC_ODIInd27 1;
BA_ "VNSigInfotainment" SG_ 2158960640 ODIIC_ODIInd26 1;
BA_ "SignalType" SG_ 2158960640 ODIIC_ODIInd26 "BLN";
BA_ "PacketOrder" SG_ 2158960640 ODIIC_ODIInd26 27;
BA_ "SignalLongName" SG_ 2158960640 ODIIC_ODIInd26 "Open Display Interface Indication Centerstack : Open Display Interface Indication 26";
BA_ "VNSigAllNodes" SG_ 2158960640 ODIIC_ODIInd26 1;
BA_ "VNSigInfotainment" SG_ 2158960640 ODIIC_ODIInd25 1;
BA_ "SignalType" SG_ 2158960640 ODIIC_ODIInd25 "BLN";
BA_ "PacketOrder" SG_ 2158960640 ODIIC_ODIInd25 26;
BA_ "SignalLongName" SG_ 2158960640 ODIIC_ODIInd25 "Open Display Interface Indication Centerstack : Open Display Interface Indication 25";
BA_ "VNSigAllNodes" SG_ 2158960640 ODIIC_ODIInd25 1;
BA_ "VNSigInfotainment" SG_ 2158960640 ODIIC_ODIInd24 1;
BA_ "SignalType" SG_ 2158960640 ODIIC_ODIInd24 "BLN";
BA_ "PacketOrder" SG_ 2158960640 ODIIC_ODIInd24 25;
BA_ "SignalLongName" SG_ 2158960640 ODIIC_ODIInd24 "Open Display Interface Indication Centerstack : Open Display Interface Indication 24";
BA_ "VNSigAllNodes" SG_ 2158960640 ODIIC_ODIInd24 1;
BA_ "VNSigInfotainment" SG_ 2158960640 ODIIC_ODIInd23 1;
BA_ "SignalType" SG_ 2158960640 ODIIC_ODIInd23 "BLN";
BA_ "PacketOrder" SG_ 2158960640 ODIIC_ODIInd23 24;
BA_ "SignalLongName" SG_ 2158960640 ODIIC_ODIInd23 "Open Display Interface Indication Centerstack : Open Display Interface Indication 23";
BA_ "VNSigAllNodes" SG_ 2158960640 ODIIC_ODIInd23 1;
BA_ "VNSigInfotainment" SG_ 2158960640 ODIIC_ODIInd22 1;
BA_ "SignalType" SG_ 2158960640 ODIIC_ODIInd22 "BLN";
BA_ "PacketOrder" SG_ 2158960640 ODIIC_ODIInd22 23;
BA_ "SignalLongName" SG_ 2158960640 ODIIC_ODIInd22 "Open Display Interface Indication Centerstack : Open Display Interface Indication 22";
BA_ "VNSigAllNodes" SG_ 2158960640 ODIIC_ODIInd22 1;
BA_ "VNSigInfotainment" SG_ 2158960640 ODIIC_ODIInd21 1;
BA_ "SignalType" SG_ 2158960640 ODIIC_ODIInd21 "BLN";
BA_ "PacketOrder" SG_ 2158960640 ODIIC_ODIInd21 22;
BA_ "SignalLongName" SG_ 2158960640 ODIIC_ODIInd21 "Open Display Interface Indication Centerstack : Open Display Interface Indication 21";
BA_ "VNSigAllNodes" SG_ 2158960640 ODIIC_ODIInd21 1;
BA_ "VNSigInfotainment" SG_ 2158960640 ODIIC_ODIInd20 1;
BA_ "SignalType" SG_ 2158960640 ODIIC_ODIInd20 "BLN";
BA_ "PacketOrder" SG_ 2158960640 ODIIC_ODIInd20 21;
BA_ "SignalLongName" SG_ 2158960640 ODIIC_ODIInd20 "Open Display Interface Indication Centerstack : Open Display Interface Indication 20";
BA_ "VNSigAllNodes" SG_ 2158960640 ODIIC_ODIInd20 1;
BA_ "VNSigInfotainment" SG_ 2158960640 ODIIC_ODIInd2 1;
BA_ "SignalType" SG_ 2158960640 ODIIC_ODIInd2 "BLN";
BA_ "PacketOrder" SG_ 2158960640 ODIIC_ODIInd2 3;
BA_ "SignalLongName" SG_ 2158960640 ODIIC_ODIInd2 "Open Display Interface Indication Centerstack : Open Display Interface Indication 2";
BA_ "VNSigAllNodes" SG_ 2158960640 ODIIC_ODIInd2 1;
BA_ "VNSigInfotainment" SG_ 2158960640 ODIIC_ODIInd19 1;
BA_ "SignalType" SG_ 2158960640 ODIIC_ODIInd19 "BLN";
BA_ "PacketOrder" SG_ 2158960640 ODIIC_ODIInd19 20;
BA_ "SignalLongName" SG_ 2158960640 ODIIC_ODIInd19 "Open Display Interface Indication Centerstack : Open Display Interface Indication 19";
BA_ "VNSigAllNodes" SG_ 2158960640 ODIIC_ODIInd19 1;
BA_ "VNSigInfotainment" SG_ 2158960640 ODIIC_ODIInd18 1;
BA_ "SignalType" SG_ 2158960640 ODIIC_ODIInd18 "BLN";
BA_ "PacketOrder" SG_ 2158960640 ODIIC_ODIInd18 19;
BA_ "SignalLongName" SG_ 2158960640 ODIIC_ODIInd18 "Open Display Interface Indication Centerstack : Open Display Interface Indication 18";
BA_ "VNSigAllNodes" SG_ 2158960640 ODIIC_ODIInd18 1;
BA_ "VNSigInfotainment" SG_ 2158960640 ODIIC_ODIInd17 1;
BA_ "SignalType" SG_ 2158960640 ODIIC_ODIInd17 "BLN";
BA_ "PacketOrder" SG_ 2158960640 ODIIC_ODIInd17 18;
BA_ "SignalLongName" SG_ 2158960640 ODIIC_ODIInd17 "Open Display Interface Indication Centerstack : Open Display Interface Indication 17";
BA_ "VNSigAllNodes" SG_ 2158960640 ODIIC_ODIInd17 1;
BA_ "VNSigInfotainment" SG_ 2158960640 ODIIC_ODIInd16 1;
BA_ "SignalType" SG_ 2158960640 ODIIC_ODIInd16 "BLN";
BA_ "PacketOrder" SG_ 2158960640 ODIIC_ODIInd16 17;
BA_ "SignalLongName" SG_ 2158960640 ODIIC_ODIInd16 "Open Display Interface Indication Centerstack : Open Display Interface Indication 16";
BA_ "VNSigAllNodes" SG_ 2158960640 ODIIC_ODIInd16 1;
BA_ "VNSigInfotainment" SG_ 2158960640 ODIIC_ODIInd15 1;
BA_ "SignalType" SG_ 2158960640 ODIIC_ODIInd15 "BLN";
BA_ "PacketOrder" SG_ 2158960640 ODIIC_ODIInd15 16;
BA_ "SignalLongName" SG_ 2158960640 ODIIC_ODIInd15 "Open Display Interface Indication Centerstack : Open Display Interface Indication 15";
BA_ "VNSigAllNodes" SG_ 2158960640 ODIIC_ODIInd15 1;
BA_ "VNSigInfotainment" SG_ 2158960640 ODIIC_ODIInd14 1;
BA_ "SignalType" SG_ 2158960640 ODIIC_ODIInd14 "BLN";
BA_ "PacketOrder" SG_ 2158960640 ODIIC_ODIInd14 15;
BA_ "SignalLongName" SG_ 2158960640 ODIIC_ODIInd14 "Open Display Interface Indication Centerstack : Open Display Interface Indication 14";
BA_ "VNSigAllNodes" SG_ 2158960640 ODIIC_ODIInd14 1;
BA_ "VNSigInfotainment" SG_ 2158960640 ODIIC_ODIInd13 1;
BA_ "SignalType" SG_ 2158960640 ODIIC_ODIInd13 "BLN";
BA_ "PacketOrder" SG_ 2158960640 ODIIC_ODIInd13 14;
BA_ "SignalLongName" SG_ 2158960640 ODIIC_ODIInd13 "Open Display Interface Indication Centerstack : Open Display Interface Indication 13";
BA_ "VNSigAllNodes" SG_ 2158960640 ODIIC_ODIInd13 1;
BA_ "VNSigInfotainment" SG_ 2158960640 ODIIC_ODIInd12 1;
BA_ "SignalType" SG_ 2158960640 ODIIC_ODIInd12 "BLN";
BA_ "PacketOrder" SG_ 2158960640 ODIIC_ODIInd12 13;
BA_ "SignalLongName" SG_ 2158960640 ODIIC_ODIInd12 "Open Display Interface Indication Centerstack : Open Display Interface Indication 12";
BA_ "VNSigAllNodes" SG_ 2158960640 ODIIC_ODIInd12 1;
BA_ "VNSigInfotainment" SG_ 2158960640 ODIIC_ODIInd11 1;
BA_ "SignalType" SG_ 2158960640 ODIIC_ODIInd11 "BLN";
BA_ "PacketOrder" SG_ 2158960640 ODIIC_ODIInd11 12;
BA_ "SignalLongName" SG_ 2158960640 ODIIC_ODIInd11 "Open Display Interface Indication Centerstack : Open Display Interface Indication 11";
BA_ "VNSigAllNodes" SG_ 2158960640 ODIIC_ODIInd11 1;
BA_ "VNSigInfotainment" SG_ 2158960640 ODIIC_ODIInd10 1;
BA_ "SignalType" SG_ 2158960640 ODIIC_ODIInd10 "BLN";
BA_ "PacketOrder" SG_ 2158960640 ODIIC_ODIInd10 11;
BA_ "SignalLongName" SG_ 2158960640 ODIIC_ODIInd10 "Open Display Interface Indication Centerstack : Open Display Interface Indication 10";
BA_ "VNSigAllNodes" SG_ 2158960640 ODIIC_ODIInd10 1;
BA_ "VNSigInfotainment" SG_ 2158960640 ODIIC_ODIInd1 1;
BA_ "SignalType" SG_ 2158960640 ODIIC_ODIInd1 "BLN";
BA_ "PacketOrder" SG_ 2158960640 ODIIC_ODIInd1 2;
BA_ "SignalLongName" SG_ 2158960640 ODIIC_ODIInd1 "Open Display Interface Indication Centerstack : Open Display Interface Indication 1";
BA_ "VNSigAllNodes" SG_ 2158960640 ODIIC_ODIInd1 1;
BA_ "VNSigInfotainment" SG_ 2158977024 ODIEC_MultiFrRetCh 1;
BA_ "SignalType" SG_ 2158977024 ODIEC_MultiFrRetCh "UNM";
BA_ "PacketOrder" SG_ 2158977024 ODIEC_MultiFrRetCh 3;
BA_ "SignalLongName" SG_ 2158977024 ODIEC_MultiFrRetCh "Open Display Interface Event Packet Centerstack : MultiFrameReturnChannel";
BA_ "VNSigAllNodes" SG_ 2158977024 ODIEC_MultiFrRetCh 1;
BA_ "VNSigInfotainment" SG_ 2158977024 ODIEC_FUCID 1;
BA_ "SignalType" SG_ 2158977024 ODIEC_FUCID "UNM";
BA_ "PacketOrder" SG_ 2158977024 ODIEC_FUCID 2;
BA_ "SignalLongName" SG_ 2158977024 ODIEC_FUCID "Open Display Interface Event Packet Centerstack : Functional Unit Class ID";
BA_ "VNSigAllNodes" SG_ 2158977024 ODIEC_FUCID 1;
BA_ "VNSigInfotainment" SG_ 2158977024 ODIEC_EvID 1;
BA_ "SignalType" SG_ 2158977024 ODIEC_EvID "UNM";
BA_ "PacketOrder" SG_ 2158977024 ODIEC_EvID 1;
BA_ "SignalLongName" SG_ 2158977024 ODIEC_EvID "Open Display Interface Event Packet Centerstack : Event ID";
BA_ "VNSigAllNodes" SG_ 2158977024 ODIEC_EvID 1;
BA_ "SignalType" SG_ 2158944256 ODDLR_SubIdReqM "UNM";
BA_ "PacketOrder" SG_ 2158944256 ODDLR_SubIdReqM 10;
BA_ "SignalLongName" SG_ 2158944256 ODDLR_SubIdReqM "Open Display Interface Dynamic Data List Request Rear Seat Display : Sub Id Request Mask";
BA_ "VNSigAllNodes" SG_ 2158944256 ODDLR_SubIdReqM 1;
BA_ "SignalType" SG_ 2158944256 ODDLR_WrpArnd "BLN";
BA_ "PacketOrder" SG_ 2158944256 ODDLR_WrpArnd 9;
BA_ "SignalLongName" SG_ 2158944256 ODDLR_WrpArnd "Open Display Interface Dynamic Data List Request Rear Seat Display : Wrap Around";
BA_ "VNSigAllNodes" SG_ 2158944256 ODDLR_WrpArnd 1;
BA_ "SignalType" SG_ 2158944256 ODDLR_ReqType "ENM";
BA_ "PacketOrder" SG_ 2158944256 ODDLR_ReqType 7;
BA_ "SignalLongName" SG_ 2158944256 ODDLR_ReqType "Open Display Interface Dynamic Data List Request Rear Seat Display : Request Type";
BA_ "VNSigAllNodes" SG_ 2158944256 ODDLR_ReqType 1;
BA_ "SignalType" SG_ 2158944256 ODDLR_ReqDir "BLN";
BA_ "PacketOrder" SG_ 2158944256 ODDLR_ReqDir 5;
BA_ "SignalLongName" SG_ 2158944256 ODDLR_ReqDir "Open Display Interface Dynamic Data List Request Rear Seat Display : Req Direction";
BA_ "VNSigAllNodes" SG_ 2158944256 ODDLR_ReqDir 1;
BA_ "SignalType" SG_ 2158944256 ODDLR_NmEntries "UNM";
BA_ "PacketOrder" SG_ 2158944256 ODDLR_NmEntries 4;
BA_ "SignalLongName" SG_ 2158944256 ODDLR_NmEntries "Open Display Interface Dynamic Data List Request Rear Seat Display : Num Entries";
BA_ "VNSigAllNodes" SG_ 2158944256 ODDLR_NmEntries 1;
BA_ "SignalType" SG_ 2158944256 ODDLR_Idx "UNM";
BA_ "PacketOrder" SG_ 2158944256 ODDLR_Idx 6;
BA_ "SignalLongName" SG_ 2158944256 ODDLR_Idx "Open Display Interface Dynamic Data List Request Rear Seat Display : Index";
BA_ "VNSigAllNodes" SG_ 2158944256 ODDLR_Idx 1;
BA_ "SignalType" SG_ 2158944256 ODDLR_FUCID "UNM";
BA_ "PacketOrder" SG_ 2158944256 ODDLR_FUCID 1;
BA_ "SignalLongName" SG_ 2158944256 ODDLR_FUCID "Open Display Interface Dynamic Data List Request Rear Seat Display : Functional Unit Class ID";
BA_ "VNSigAllNodes" SG_ 2158944256 ODDLR_FUCID 1;
BA_ "SignalType" SG_ 2158944256 ODDLR_DspMID "ENM";
BA_ "PacketOrder" SG_ 2158944256 ODDLR_DspMID 3;
BA_ "SignalLongName" SG_ 2158944256 ODDLR_DspMID "Open Display Interface Dynamic Data List Request Rear Seat Display : Display Mask Id";
BA_ "VNSigAllNodes" SG_ 2158944256 ODDLR_DspMID 1;
BA_ "SignalType" SG_ 2158944256 ODDLR_DataId "UNM";
BA_ "PacketOrder" SG_ 2158944256 ODDLR_DataId 2;
BA_ "SignalLongName" SG_ 2158944256 ODDLR_DataId "Open Display Interface Dynamic Data List Request Rear Seat Display : Data Id";
BA_ "VNSigAllNodes" SG_ 2158944256 ODDLR_DataId 1;
BA_ "SignalType" SG_ 2158944256 ODDLR_BckgndFlag "ENM";
BA_ "PacketOrder" SG_ 2158944256 ODDLR_BckgndFlag 8;
BA_ "SignalLongName" SG_ 2158944256 ODDLR_BckgndFlag "Open Display Interface Dynamic Data List Request Rear Seat Display : Background Flag";
BA_ "VNSigAllNodes" SG_ 2158944256 ODDLR_BckgndFlag 1;
BA_ "GenSigSendType" SG_ 2151120896 FrlftPasSeatbltRemOccSt 10;
BA_ "GenSigSendOnInit" SG_ 2151120896 FrlftPasSeatbltRemOccSt 2;
BA_ "SignalType" SG_ 2151120896 FrlftPasSeatbltRemOccSt "ENM";
BA_ "SignalLongName" SG_ 2151120896 FrlftPasSeatbltRemOccSt "Front Left Passenger Seatbelt Reminder Occupancy Status";
BA_ "VNSigAllNodes" SG_ 2151120896 FrlftPasSeatbltRemOccSt 1;
BA_ "GenSigSendType" SG_ 2151120896 FrlftPasSeatResCtrlOccStV 10;
BA_ "GenSigSendOnInit" SG_ 2151120896 FrlftPasSeatResCtrlOccStV 2;
BA_ "SignalType" SG_ 2151120896 FrlftPasSeatResCtrlOccStV "ENM";
BA_ "SignalLongName" SG_ 2151120896 FrlftPasSeatResCtrlOccStV "Front Left Passenger Seat Restraint Control Occupancy Status Validity";
BA_ "VNSigAllNodes" SG_ 2151120896 FrlftPasSeatResCtrlOccStV 1;
BA_ "GenSigSendType" SG_ 2151120896 FrtlftPasSeatResCtrlOccSt 10;
BA_ "GenSigSendOnInit" SG_ 2151120896 FrtlftPasSeatResCtrlOccSt 2;
BA_ "SignalType" SG_ 2151120896 FrtlftPasSeatResCtrlOccSt "ENM";
BA_ "SignalLongName" SG_ 2151120896 FrtlftPasSeatResCtrlOccSt "Front Left Passenger Seat Restraint Control Occupancy Status";
BA_ "VNSigAllNodes" SG_ 2151120896 FrtlftPasSeatResCtrlOccSt 1;
BA_ "GenSigSendType" SG_ 2151120896 FrtlftPsSeatOccSnsOpMd 10;
BA_ "GenSigSendOnInit" SG_ 2151120896 FrtlftPsSeatOccSnsOpMd 2;
BA_ "SignalType" SG_ 2151120896 FrtlftPsSeatOccSnsOpMd "ENM";
BA_ "SignalLongName" SG_ 2151120896 FrtlftPsSeatOccSnsOpMd "Front Left Passenger Seat Occupancy Sensing Operating Mode";
BA_ "VNSigAllNodes" SG_ 2151120896 FrtlftPsSeatOccSnsOpMd 1;
BA_ "GenSigSendType" SG_ 2151120896 FrlftPsSeatOccFltSt 10;
BA_ "GenSigSendOnInit" SG_ 2151120896 FrlftPsSeatOccFltSt 2;
BA_ "SignalType" SG_ 2151120896 FrlftPsSeatOccFltSt "ENM";
BA_ "SignalLongName" SG_ 2151120896 FrlftPsSeatOccFltSt "Front Left Passenger Seat Occupancy Fault Status";
BA_ "VNSigAllNodes" SG_ 2151120896 FrlftPsSeatOccFltSt 1;
BA_ "GenSigSendType" SG_ 2151120896 FrntlftPassClass 10;
BA_ "GenSigSendOnInit" SG_ 2151120896 FrntlftPassClass 2;
BA_ "SignalType" SG_ 2151120896 FrntlftPassClass "ENM";
BA_ "SignalLongName" SG_ 2151120896 FrntlftPassClass "Front Left Passenger Classification";
BA_ "VNSigAllNodes" SG_ 2151120896 FrntlftPassClass 1;
BA_ "GenSigDeltaValue" SG_ 2154332160 CrShrngVehChlng 1;
BA_ "VNSigIntermediate" SG_ 2154332160 CrShrngVehChlng 1;
BA_ "SignalType" SG_ 2154332160 CrShrngVehChlng "UNM";
BA_ "SignalLongName" SG_ 2154332160 CrShrngVehChlng "Car Sharing Vehicle Challenge";
BA_ "GenSigDeltaValue" SG_ 2154414080 CrShrngConnUnqIdntfr1 1;
BA_ "VNSigIntermediate" SG_ 2154414080 CrShrngConnUnqIdntfr1 1;
BA_ "SignalType" SG_ 2154414080 CrShrngConnUnqIdntfr1 "UNM";
BA_ "SignalLongName" SG_ 2154414080 CrShrngConnUnqIdntfr1 "Car Sharing Connection Unique Identifier 1";
BA_ "GenSigSendType" SG_ 2154397696 CrShrngConnStat 10;
BA_ "VNSigIntermediate" SG_ 2154397696 CrShrngConnStat 1;
BA_ "SignalType" SG_ 2154397696 CrShrngConnStat "ENM";
BA_ "SignalLongName" SG_ 2154397696 CrShrngConnStat "Car Sharing Connection Status";
BA_ "GenSigDeltaValue" SG_ 2154397696 FobIntrCt 1;
BA_ "GenSigSendType" SG_ 2154397696 FobIntrCt 12;
BA_ "VNSigIntermediate" SG_ 2154397696 FobIntrCt 1;
BA_ "SignalType" SG_ 2154397696 FobIntrCt "UNM";
BA_ "SignalLongName" SG_ 2154397696 FobIntrCt "Fob Interior Count";
BA_ "GenSigSendType" SG_ 2154397696 CSPS_RspVerf 10;
BA_ "PacketOrder" SG_ 2154397696 CSPS_RspVerf 1;
BA_ "VNSigIntermediate" SG_ 2154397696 CSPS_RspVerf 1;
BA_ "SignalType" SG_ 2154397696 CSPS_RspVerf "ENM";
BA_ "SignalLongName" SG_ 2154397696 CSPS_RspVerf "Car Sharing Phone Status : Response Verification";
BA_ "GenSigSendType" SG_ 2154397696 CSPS_ConnStat 10;
BA_ "PacketOrder" SG_ 2154397696 CSPS_ConnStat 2;
BA_ "VNSigIntermediate" SG_ 2154397696 CSPS_ConnStat 1;
BA_ "SignalType" SG_ 2154397696 CSPS_ConnStat "ENM";
BA_ "SignalLongName" SG_ 2154397696 CSPS_ConnStat "Car Sharing Phone Status : Connection Status";
BA_ "GenSigSendType" SG_ 2154397696 CSPS_CertfctId 12;
BA_ "PacketOrder" SG_ 2154397696 CSPS_CertfctId 3;
BA_ "VNSigIntermediate" SG_ 2154397696 CSPS_CertfctId 1;
BA_ "SignalType" SG_ 2154397696 CSPS_CertfctId "UNM";
BA_ "SignalLongName" SG_ 2154397696 CSPS_CertfctId "Car Sharing Phone Status : Certificate Identification";
BA_ "GenSigSendType" SG_ 2154397696 CrShrngFbsEnblStat 10;
BA_ "VNSigIntermediate" SG_ 2154397696 CrShrngFbsEnblStat 1;
BA_ "SignalType" SG_ 2154397696 CrShrngFbsEnblStat "ENM";
BA_ "SignalLongName" SG_ 2154397696 CrShrngFbsEnblStat "Car Sharing Fobs Enable Status";
BA_ "GenSigSendType" SG_ 2154397696 CrShrngRvkCertfctRsp 10;
BA_ "VNSigIntermediate" SG_ 2154397696 CrShrngRvkCertfctRsp 1;
BA_ "SignalType" SG_ 2154397696 CrShrngRvkCertfctRsp "ENM";
BA_ "SignalLongName" SG_ 2154397696 CrShrngRvkCertfctRsp "Car Sharing Revoke Certificate Response";
BA_ "GenSigDeltaValue" SG_ 2154536960 CrShrngEncrpScrt 1;
BA_ "GenSigSendType" SG_ 2154536960 CrShrngEncrpScrt 12;
BA_ "VNSigIntermediate" SG_ 2154536960 CrShrngEncrpScrt 1;
BA_ "SignalType" SG_ 2154536960 CrShrngEncrpScrt "UNM";
BA_ "SignalLongName" SG_ 2154536960 CrShrngEncrpScrt "Car Sharing Encrypted Secret";
BA_ "GenSigDeltaValue" SG_ 2154545152 CrShrgIntCtftAthrtyCtftRp 1;
BA_ "GenSigSendType" SG_ 2154545152 CrShrgIntCtftAthrtyCtftRp 12;
BA_ "VNSigIntermediate" SG_ 2154545152 CrShrgIntCtftAthrtyCtftRp 1;
BA_ "SignalType" SG_ 2154545152 CrShrgIntCtftAthrtyCtftRp "UNM";
BA_ "SignalLongName" SG_ 2154545152 CrShrgIntCtftAthrtyCtftRp "Car Sharing Intermediate Certificate Authority Certificate Response";
BA_ "GenSigDeltaValue" SG_ 2154504192 CrShrngUsrCertfctRsp 1;
BA_ "GenSigSendType" SG_ 2154504192 CrShrngUsrCertfctRsp 12;
BA_ "VNSigIntermediate" SG_ 2154504192 CrShrngUsrCertfctRsp 1;
BA_ "SignalType" SG_ 2154504192 CrShrngUsrCertfctRsp "UNM";
BA_ "SignalLongName" SG_ 2154504192 CrShrngUsrCertfctRsp "Car Sharing User Certificate Response";
BA_ "GenSigDeltaValue" SG_ 2154463232 CrShrngPhRsp2 1;
BA_ "GenSigSendType" SG_ 2154463232 CrShrngPhRsp2 12;
BA_ "VNSigIntermediate" SG_ 2154463232 CrShrngPhRsp2 1;
BA_ "SignalType" SG_ 2154463232 CrShrngPhRsp2 "UNM";
BA_ "SignalLongName" SG_ 2154463232 CrShrngPhRsp2 "Car Sharing Phone Response 2";
BA_ "GenSigDeltaValue" SG_ 2154446848 CrShrngPhRsp1 1;
BA_ "GenSigSendType" SG_ 2154446848 CrShrngPhRsp1 12;
BA_ "VNSigIntermediate" SG_ 2154446848 CrShrngPhRsp1 1;
BA_ "SignalType" SG_ 2154446848 CrShrngPhRsp1 "UNM";
BA_ "SignalLongName" SG_ 2154446848 CrShrngPhRsp1 "Car Sharing Phone Response 1";
BA_ "SignalType" SG_ 1347 DgnInf_LS543 "UNM";
BA_ "SignalLongName" SG_ 1347 DgnInf_LS543 "Diagnostic Information LS543";
BA_ "VNSigDiagnostic" SG_ 1347 DgnInf_LS543 1;
BA_ "VNSigAllNodes" SG_ 1347 DgnInf_LS543 1;
BA_ "VNSigInfotainment" SG_ 2152177664 RmtRflshElecPwrRdness 1;
BA_ "SignalType" SG_ 2152177664 RmtRflshElecPwrRdness "UNM";
BA_ "SignalLongName" SG_ 2152177664 RmtRflshElecPwrRdness "Remote Reflash Electric Power Readiness";
BA_ "VNSigAllNodes" SG_ 2152177664 RmtRflshElecPwrRdness 1;
BA_ "GenSigSendType" SG_ 2150531072 RegPwrLmtdDspPrcntVs 10;
BA_ "GenSigSendOnInit" SG_ 2150531072 RegPwrLmtdDspPrcntVs 1;
BA_ "SignalType" SG_ 2150531072 RegPwrLmtdDspPrcntVs "BLN";
BA_ "SignalLongName" SG_ 2150531072 RegPwrLmtdDspPrcntVs "Regenerative Power Limited Display Percent Visible";
BA_ "VNSigAllNodes" SG_ 2150531072 RegPwrLmtdDspPrcntVs 1;
BA_ "GenSigDeltaValue" SG_ 2150531072 RegPwrLmtdDspPrcnt 1;
BA_ "GenSigSendType" SG_ 2150531072 RegPwrLmtdDspPrcnt 12;
BA_ "GenSigSendOnInit" SG_ 2150531072 RegPwrLmtdDspPrcnt 1;
BA_ "SignalType" SG_ 2150531072 RegPwrLmtdDspPrcnt "SNM";
BA_ "SignalLongName" SG_ 2150531072 RegPwrLmtdDspPrcnt "Regenerative Power Limited Display Percent";
BA_ "VNSigAllNodes" SG_ 2150531072 RegPwrLmtdDspPrcnt 1;
BA_ "GenSigSendType" SG_ 2150531072 RegPwrLmtdIO 10;
BA_ "GenSigSendOnInit" SG_ 2150531072 RegPwrLmtdIO 1;
BA_ "SignalType" SG_ 2150531072 RegPwrLmtdIO "BLN";
BA_ "SignalLongName" SG_ 2150531072 RegPwrLmtdIO "Regenerative Power Limited Indication On";
BA_ "VNSigAllNodes" SG_ 2150531072 RegPwrLmtdIO 1;
BA_ "SignalType" SG_ 856 DgnInf "UNM";
BA_ "SignalLongName" SG_ 856 DgnInf "Diagnostic Information";
BA_ "VNSigDiagnostic" SG_ 856 DgnInf 1;
BA_ "VNSigAllNodes" SG_ 856 DgnInf 1;
BA_ "SignalType" SG_ 921 DgnInf "UNM";
BA_ "SignalLongName" SG_ 921 DgnInf "Diagnostic Information";
BA_ "VNSigDiagnostic" SG_ 921 DgnInf 1;
BA_ "VNSigAllNodes" SG_ 921 DgnInf 1;
BA_ "SignalType" SG_ 88 DgnInf "UNM";
BA_ "SignalLongName" SG_ 88 DgnInf "Diagnostic Information";
BA_ "VNSigDiagnostic" SG_ 88 DgnInf 1;
BA_ "VNSigAllNodes" SG_ 88 DgnInf 1;
BA_ "SignalType" SG_ 153 DgnInf "UNM";
BA_ "SignalLongName" SG_ 153 DgnInf "Diagnostic Information";
BA_ "VNSigDiagnostic" SG_ 153 DgnInf 1;
BA_ "VNSigAllNodes" SG_ 153 DgnInf 1;
BA_ "GenSigDeltaValue" SG_ 2159255552 ODI_CntrStck2BCM 1;
BA_ "GenSigSendType" SG_ 2159255552 ODI_CntrStck2BCM 12;
BA_ "VNSigInfotainment" SG_ 2159255552 ODI_CntrStck2BCM 1;
BA_ "SignalType" SG_ 2159255552 ODI_CntrStck2BCM "UNM";
BA_ "SignalLongName" SG_ 2159255552 ODI_CntrStck2BCM "Open Display Interface CenterStack 2 BCM";
BA_ "VNSigAllNodes" SG_ 2159255552 ODI_CntrStck2BCM 1;
BA_ "GenSigDeltaValue" SG_ 2159247360 ODI_BCM2CntrStck 1;
BA_ "GenSigSendType" SG_ 2159247360 ODI_BCM2CntrStck 12;
BA_ "VNSigInfotainment" SG_ 2159247360 ODI_BCM2CntrStck 1;
BA_ "SignalType" SG_ 2159247360 ODI_BCM2CntrStck "UNM";
BA_ "SignalLongName" SG_ 2159247360 ODI_BCM2CntrStck "Open Display Interface BCM 2 CenterStack";
BA_ "VNSigAllNodes" SG_ 2159247360 ODI_BCM2CntrStck 1;
BA_ "GenSigSendType" SG_ 2154725376 AuxHtrAtv378 10;
BA_ "SignalType" SG_ 2154725376 AuxHtrAtv378 "BLN";
BA_ "SignalLongName" SG_ 2154725376 AuxHtrAtv378 "Auxiliary Heater Active";
BA_ "VNSigAllNodes" SG_ 2154725376 AuxHtrAtv378 1;
BA_ "GenSigSendType" SG_ 2154725376 AuxHtrRq 10;
BA_ "SignalType" SG_ 2154725376 AuxHtrRq "ENM";
BA_ "SignalLongName" SG_ 2154725376 AuxHtrRq "Auxiliary Heater Request";
BA_ "VNSigAllNodes" SG_ 2154725376 AuxHtrRq 1;
BA_ "GenSigDeltaValue" SG_ 2158133248 HVDpltnMdMiCnfdcRgExt 1;
BA_ "GenSigSendType" SG_ 2158133248 HVDpltnMdMiCnfdcRgExt 12;
BA_ "GenSigSendOnInit" SG_ 2158133248 HVDpltnMdMiCnfdcRgExt 1;
BA_ "SignalType" SG_ 2158133248 HVDpltnMdMiCnfdcRgExt "UNM";
BA_ "SignalLongName" SG_ 2158133248 HVDpltnMdMiCnfdcRgExt "High Voltage Depletion Mode Minimum Confidence Range Extended";
BA_ "VNSigAllNodes" SG_ 2158133248 HVDpltnMdMiCnfdcRgExt 1;
BA_ "GenSigDeltaValue" SG_ 2158133248 HVDpltnMdMxCnfdcRgExt 1;
BA_ "GenSigSendType" SG_ 2158133248 HVDpltnMdMxCnfdcRgExt 12;
BA_ "GenSigSendOnInit" SG_ 2158133248 HVDpltnMdMxCnfdcRgExt 1;
BA_ "SignalType" SG_ 2158133248 HVDpltnMdMxCnfdcRgExt "UNM";
BA_ "SignalLongName" SG_ 2158133248 HVDpltnMdMxCnfdcRgExt "High Voltage Depletion Mode Maximum Confidence Range Extended";
BA_ "VNSigAllNodes" SG_ 2158133248 HVDpltnMdMxCnfdcRgExt 1;
BA_ "GenSigSendType" SG_ 2158133248 HTRCsStAvail 10;
BA_ "GenSigSendOnInit" SG_ 2158133248 HTRCsStAvail 1;
BA_ "VNSigInfotainment" SG_ 2158133248 HTRCsStAvail 1;
BA_ "SignalType" SG_ 2158133248 HTRCsStAvail "BLN";
BA_ "SignalLongName" SG_ 2158133248 HTRCsStAvail "Hill Top Reserve Customization Setting Available";
BA_ "VNSigAllNodes" SG_ 2158133248 HTRCsStAvail 1;
BA_ "GenSigSendType" SG_ 2158133248 HTRCsCrStVal 10;
BA_ "GenSigSendOnInit" SG_ 2158133248 HTRCsCrStVal 1;
BA_ "VNSigInfotainment" SG_ 2158133248 HTRCsCrStVal 1;
BA_ "SignalType" SG_ 2158133248 HTRCsCrStVal "ENM";
BA_ "SignalLongName" SG_ 2158133248 HTRCsCrStVal "Hill Top Reserve Customization Current Setting Value";
BA_ "VNSigAllNodes" SG_ 2158133248 HTRCsCrStVal 1;
BA_ "GenSigSendType" SG_ 2158133248 HTRCA_Res3Avail 10;
BA_ "GenSigSendOnInit" SG_ 2158133248 HTRCA_Res3Avail 1;
BA_ "VNSigInfotainment" SG_ 2158133248 HTRCA_Res3Avail 1;
BA_ "SignalType" SG_ 2158133248 HTRCA_Res3Avail "BLN";
BA_ "PacketOrder" SG_ 2158133248 HTRCA_Res3Avail 7;
BA_ "SignalLongName" SG_ 2158133248 HTRCA_Res3Avail "Hill Top Reserve Customization Available : Reserved3 Available";
BA_ "VNSigAllNodes" SG_ 2158133248 HTRCA_Res3Avail 1;
BA_ "GenSigSendType" SG_ 2158133248 HTRCA_Res2Avail 10;
BA_ "GenSigSendOnInit" SG_ 2158133248 HTRCA_Res2Avail 1;
BA_ "VNSigInfotainment" SG_ 2158133248 HTRCA_Res2Avail 1;
BA_ "SignalType" SG_ 2158133248 HTRCA_Res2Avail "BLN";
BA_ "PacketOrder" SG_ 2158133248 HTRCA_Res2Avail 6;
BA_ "SignalLongName" SG_ 2158133248 HTRCA_Res2Avail "Hill Top Reserve Customization Available : Reserved2 Available";
BA_ "VNSigAllNodes" SG_ 2158133248 HTRCA_Res2Avail 1;
BA_ "GenSigSendType" SG_ 2158133248 HTRCA_Res1Avail 10;
BA_ "GenSigSendOnInit" SG_ 2158133248 HTRCA_Res1Avail 1;
BA_ "VNSigInfotainment" SG_ 2158133248 HTRCA_Res1Avail 1;
BA_ "SignalType" SG_ 2158133248 HTRCA_Res1Avail "BLN";
BA_ "PacketOrder" SG_ 2158133248 HTRCA_Res1Avail 5;
BA_ "SignalLongName" SG_ 2158133248 HTRCA_Res1Avail "Hill Top Reserve Customization Available : Reserved1 Available";
BA_ "VNSigAllNodes" SG_ 2158133248 HTRCA_Res1Avail 1;
BA_ "GenSigSendType" SG_ 2158133248 HTRCA_OnAwAvail 10;
BA_ "GenSigSendOnInit" SG_ 2158133248 HTRCA_OnAwAvail 1;
BA_ "VNSigInfotainment" SG_ 2158133248 HTRCA_OnAwAvail 1;
BA_ "SignalType" SG_ 2158133248 HTRCA_OnAwAvail "BLN";
BA_ "PacketOrder" SG_ 2158133248 HTRCA_OnAwAvail 4;
BA_ "SignalLongName" SG_ 2158133248 HTRCA_OnAwAvail "Hill Top Reserve Customization Available : On Away Available";
BA_ "VNSigAllNodes" SG_ 2158133248 HTRCA_OnAwAvail 1;
BA_ "GenSigSendType" SG_ 2158133248 HTRCA_OnHmAvail 10;
BA_ "GenSigSendOnInit" SG_ 2158133248 HTRCA_OnHmAvail 1;
BA_ "VNSigInfotainment" SG_ 2158133248 HTRCA_OnHmAvail 1;
BA_ "SignalType" SG_ 2158133248 HTRCA_OnHmAvail "BLN";
BA_ "PacketOrder" SG_ 2158133248 HTRCA_OnHmAvail 3;
BA_ "SignalLongName" SG_ 2158133248 HTRCA_OnHmAvail "Hill Top Reserve Customization Available : On Home Available";
BA_ "VNSigAllNodes" SG_ 2158133248 HTRCA_OnHmAvail 1;
BA_ "GenSigSendType" SG_ 2158133248 HTRCA_OnAvail 10;
BA_ "GenSigSendOnInit" SG_ 2158133248 HTRCA_OnAvail 1;
BA_ "VNSigInfotainment" SG_ 2158133248 HTRCA_OnAvail 1;
BA_ "SignalType" SG_ 2158133248 HTRCA_OnAvail "BLN";
BA_ "PacketOrder" SG_ 2158133248 HTRCA_OnAvail 2;
BA_ "SignalLongName" SG_ 2158133248 HTRCA_OnAvail "Hill Top Reserve Customization Available : On Available";
BA_ "VNSigAllNodes" SG_ 2158133248 HTRCA_OnAvail 1;
BA_ "GenSigSendType" SG_ 2158133248 HTRCA_OffAvail 10;
BA_ "GenSigSendOnInit" SG_ 2158133248 HTRCA_OffAvail 1;
BA_ "VNSigInfotainment" SG_ 2158133248 HTRCA_OffAvail 1;
BA_ "SignalType" SG_ 2158133248 HTRCA_OffAvail "BLN";
BA_ "PacketOrder" SG_ 2158133248 HTRCA_OffAvail 1;
BA_ "SignalLongName" SG_ 2158133248 HTRCA_OffAvail "Hill Top Reserve Customization Available : Off Available";
BA_ "VNSigAllNodes" SG_ 2158133248 HTRCA_OffAvail 1;
BA_ "GenSigSendType" SG_ 2151931904 ElctShfPriLtdPerfMdIO 10;
BA_ "SignalType" SG_ 2151931904 ElctShfPriLtdPerfMdIO "BLN";
BA_ "SignalLongName" SG_ 2151931904 ElctShfPriLtdPerfMdIO "Electronic Shift Primary Limited Performance Mode Indication On";
BA_ "VNSigAllNodes" SG_ 2151931904 ElctShfPriLtdPerfMdIO 1;
BA_ "GenSigSendType" SG_ 2151931904 RegVltCtlEngyRcvryAct 10;
BA_ "SignalType" SG_ 2151931904 RegVltCtlEngyRcvryAct "BLN";
BA_ "SignalLongName" SG_ 2151931904 RegVltCtlEngyRcvryAct "Regulated Voltage Control Energy Recovery Active";
BA_ "VNSigAllNodes" SG_ 2151931904 RegVltCtlEngyRcvryAct 1;
BA_ "GenSigSendType" SG_ 2151931904 VehSpdCntlSystmType 10;
BA_ "SignalType" SG_ 2151931904 VehSpdCntlSystmType "ENM";
BA_ "SignalLongName" SG_ 2151931904 VehSpdCntlSystmType "Vehicle Speed Control System Type";
BA_ "VNSigAllNodes" SG_ 2151931904 VehSpdCntlSystmType 1;
BA_ "GenSigSendType" SG_ 2151931904 PTExPrtclFltWrng3IO 10;
BA_ "SignalType" SG_ 2151931904 PTExPrtclFltWrng3IO "BLN";
BA_ "SignalLongName" SG_ 2151931904 PTExPrtclFltWrng3IO "Powertrain Exhaust Particle Filter Warning 3 Indication On";
BA_ "VNSigAllNodes" SG_ 2151931904 PTExPrtclFltWrng3IO 1;
BA_ "GenSigSendType" SG_ 2151931904 PTExPartFltManRegStat 10;
BA_ "SignalType" SG_ 2151931904 PTExPartFltManRegStat "ENM";
BA_ "SignalLongName" SG_ 2151931904 PTExPartFltManRegStat "Powertrain Exhaust Particle Filter Manual Regeneration Status";
BA_ "VNSigAllNodes" SG_ 2151931904 PTExPartFltManRegStat 1;
BA_ "GenSigSendType" SG_ 2151931904 AWDRecmndIO 10;
BA_ "SignalType" SG_ 2151931904 AWDRecmndIO "BLN";
BA_ "SignalLongName" SG_ 2151931904 AWDRecmndIO "All Wheel Drive Recommended Indication On";
BA_ "VNSigAllNodes" SG_ 2151931904 AWDRecmndIO 1;
BA_ "GenSigDeltaValue" SG_ 2150244352 ECHGDDV_Col10 1;
BA_ "GenSigSendType" SG_ 2150244352 ECHGDDV_Col10 12;
BA_ "GenSigSendOnInit" SG_ 2150244352 ECHGDDV_Col10 1;
BA_ "PacketOrder" SG_ 2150244352 ECHGDDV_Col10 11;
BA_ "VNSigInfotainment" SG_ 2150244352 ECHGDDV_Col10 1;
BA_ "SignalType" SG_ 2150244352 ECHGDDV_Col10 "UNM";
BA_ "SignalLongName" SG_ 2150244352 ECHGDDV_Col10 "Energy Consumption History Graph Display Data Values : Column 10";
BA_ "VNSigAllNodes" SG_ 2150244352 ECHGDDV_Col10 1;
BA_ "GenSigDeltaValue" SG_ 2150244352 ECHGDDV_Col9 1;
BA_ "GenSigSendType" SG_ 2150244352 ECHGDDV_Col9 12;
BA_ "GenSigSendOnInit" SG_ 2150244352 ECHGDDV_Col9 1;
BA_ "PacketOrder" SG_ 2150244352 ECHGDDV_Col9 10;
BA_ "VNSigInfotainment" SG_ 2150244352 ECHGDDV_Col9 1;
BA_ "SignalType" SG_ 2150244352 ECHGDDV_Col9 "UNM";
BA_ "SignalLongName" SG_ 2150244352 ECHGDDV_Col9 "Energy Consumption History Graph Display Data Values : Column 09";
BA_ "VNSigAllNodes" SG_ 2150244352 ECHGDDV_Col9 1;
BA_ "GenSigDeltaValue" SG_ 2150244352 ECHGDDV_Col8 1;
BA_ "GenSigSendType" SG_ 2150244352 ECHGDDV_Col8 12;
BA_ "GenSigSendOnInit" SG_ 2150244352 ECHGDDV_Col8 1;
BA_ "PacketOrder" SG_ 2150244352 ECHGDDV_Col8 9;
BA_ "VNSigInfotainment" SG_ 2150244352 ECHGDDV_Col8 1;
BA_ "SignalType" SG_ 2150244352 ECHGDDV_Col8 "UNM";
BA_ "SignalLongName" SG_ 2150244352 ECHGDDV_Col8 "Energy Consumption History Graph Display Data Values : Column 08";
BA_ "VNSigAllNodes" SG_ 2150244352 ECHGDDV_Col8 1;
BA_ "GenSigDeltaValue" SG_ 2150244352 ECHGDDV_Col7 1;
BA_ "GenSigSendType" SG_ 2150244352 ECHGDDV_Col7 12;
BA_ "GenSigSendOnInit" SG_ 2150244352 ECHGDDV_Col7 1;
BA_ "PacketOrder" SG_ 2150244352 ECHGDDV_Col7 8;
BA_ "VNSigInfotainment" SG_ 2150244352 ECHGDDV_Col7 1;
BA_ "SignalType" SG_ 2150244352 ECHGDDV_Col7 "UNM";
BA_ "SignalLongName" SG_ 2150244352 ECHGDDV_Col7 "Energy Consumption History Graph Display Data Values : Column 07";
BA_ "VNSigAllNodes" SG_ 2150244352 ECHGDDV_Col7 1;
BA_ "GenSigDeltaValue" SG_ 2150244352 ECHGDDV_Col6 1;
BA_ "GenSigSendType" SG_ 2150244352 ECHGDDV_Col6 12;
BA_ "GenSigSendOnInit" SG_ 2150244352 ECHGDDV_Col6 1;
BA_ "PacketOrder" SG_ 2150244352 ECHGDDV_Col6 7;
BA_ "VNSigInfotainment" SG_ 2150244352 ECHGDDV_Col6 1;
BA_ "SignalType" SG_ 2150244352 ECHGDDV_Col6 "UNM";
BA_ "SignalLongName" SG_ 2150244352 ECHGDDV_Col6 "Energy Consumption History Graph Display Data Values : Column 06";
BA_ "VNSigAllNodes" SG_ 2150244352 ECHGDDV_Col6 1;
BA_ "GenSigDeltaValue" SG_ 2150244352 ECHGDDV_Col5 1;
BA_ "GenSigSendType" SG_ 2150244352 ECHGDDV_Col5 12;
BA_ "GenSigSendOnInit" SG_ 2150244352 ECHGDDV_Col5 1;
BA_ "PacketOrder" SG_ 2150244352 ECHGDDV_Col5 6;
BA_ "VNSigInfotainment" SG_ 2150244352 ECHGDDV_Col5 1;
BA_ "SignalType" SG_ 2150244352 ECHGDDV_Col5 "UNM";
BA_ "SignalLongName" SG_ 2150244352 ECHGDDV_Col5 "Energy Consumption History Graph Display Data Values : Column 05";
BA_ "VNSigAllNodes" SG_ 2150244352 ECHGDDV_Col5 1;
BA_ "GenSigDeltaValue" SG_ 2150244352 ECHGDDV_Col4 1;
BA_ "GenSigSendType" SG_ 2150244352 ECHGDDV_Col4 12;
BA_ "GenSigSendOnInit" SG_ 2150244352 ECHGDDV_Col4 1;
BA_ "PacketOrder" SG_ 2150244352 ECHGDDV_Col4 5;
BA_ "VNSigInfotainment" SG_ 2150244352 ECHGDDV_Col4 1;
BA_ "SignalType" SG_ 2150244352 ECHGDDV_Col4 "UNM";
BA_ "SignalLongName" SG_ 2150244352 ECHGDDV_Col4 "Energy Consumption History Graph Display Data Values : Column 04";
BA_ "VNSigAllNodes" SG_ 2150244352 ECHGDDV_Col4 1;
BA_ "GenSigDeltaValue" SG_ 2150244352 ECHGDDV_Col3 1;
BA_ "GenSigSendType" SG_ 2150244352 ECHGDDV_Col3 12;
BA_ "GenSigSendOnInit" SG_ 2150244352 ECHGDDV_Col3 1;
BA_ "PacketOrder" SG_ 2150244352 ECHGDDV_Col3 4;
BA_ "VNSigInfotainment" SG_ 2150244352 ECHGDDV_Col3 1;
BA_ "SignalType" SG_ 2150244352 ECHGDDV_Col3 "UNM";
BA_ "SignalLongName" SG_ 2150244352 ECHGDDV_Col3 "Energy Consumption History Graph Display Data Values : Column 03";
BA_ "VNSigAllNodes" SG_ 2150244352 ECHGDDV_Col3 1;
BA_ "GenSigDeltaValue" SG_ 2150244352 ECHGDDV_Col2 1;
BA_ "GenSigSendType" SG_ 2150244352 ECHGDDV_Col2 12;
BA_ "GenSigSendOnInit" SG_ 2150244352 ECHGDDV_Col2 1;
BA_ "PacketOrder" SG_ 2150244352 ECHGDDV_Col2 3;
BA_ "VNSigInfotainment" SG_ 2150244352 ECHGDDV_Col2 1;
BA_ "SignalType" SG_ 2150244352 ECHGDDV_Col2 "UNM";
BA_ "SignalLongName" SG_ 2150244352 ECHGDDV_Col2 "Energy Consumption History Graph Display Data Values : Column 02";
BA_ "VNSigAllNodes" SG_ 2150244352 ECHGDDV_Col2 1;
BA_ "GenSigDeltaValue" SG_ 2150244352 ECHGDDV_Col1 1;
BA_ "GenSigSendType" SG_ 2150244352 ECHGDDV_Col1 12;
BA_ "GenSigSendOnInit" SG_ 2150244352 ECHGDDV_Col1 1;
BA_ "PacketOrder" SG_ 2150244352 ECHGDDV_Col1 2;
BA_ "VNSigInfotainment" SG_ 2150244352 ECHGDDV_Col1 1;
BA_ "SignalType" SG_ 2150244352 ECHGDDV_Col1 "UNM";
BA_ "SignalLongName" SG_ 2150244352 ECHGDDV_Col1 "Energy Consumption History Graph Display Data Values : Column 01";
BA_ "VNSigAllNodes" SG_ 2150244352 ECHGDDV_Col1 1;
BA_ "GenSigDeltaValue" SG_ 2150244352 ECHGDDV_EngyConsAvg 1;
BA_ "GenSigSendType" SG_ 2150244352 ECHGDDV_EngyConsAvg 12;
BA_ "GenSigSendOnInit" SG_ 2150244352 ECHGDDV_EngyConsAvg 1;
BA_ "PacketOrder" SG_ 2150244352 ECHGDDV_EngyConsAvg 1;
BA_ "VNSigInfotainment" SG_ 2150244352 ECHGDDV_EngyConsAvg 1;
BA_ "SignalType" SG_ 2150244352 ECHGDDV_EngyConsAvg "UNM";
BA_ "SignalLongName" SG_ 2150244352 ECHGDDV_EngyConsAvg "Energy Consumption History Graph Display Data Values : Energy Consumed Average";
BA_ "VNSigAllNodes" SG_ 2150244352 ECHGDDV_EngyConsAvg 1;
BA_ "SignalType" SG_ 579 DgnInf "UNM";
BA_ "SignalLongName" SG_ 579 DgnInf "Diagnostic Information";
BA_ "VNSigDiagnostic" SG_ 579 DgnInf 1;
BA_ "VNSigAllNodes" SG_ 579 DgnInf 1;
BA_ "GenSigDeltaValue" SG_ 2155028480 RtLnChngThrtAprchSpd 1;
BA_ "GenSigSendType" SG_ 2155028480 RtLnChngThrtAprchSpd 12;
BA_ "SignalType" SG_ 2155028480 RtLnChngThrtAprchSpd "SNM";
BA_ "SignalLongName" SG_ 2155028480 RtLnChngThrtAprchSpd "Right Lane Change Threat Approach Speed";
BA_ "VNSigAllNodes" SG_ 2155028480 RtLnChngThrtAprchSpd 1;
BA_ "GenSigSendType" SG_ 2155028480 RgtLnChgThrt 10;
BA_ "SignalType" SG_ 2155028480 RgtLnChgThrt "BLN";
BA_ "SignalLongName" SG_ 2155028480 RgtLnChgThrt "Right Lane Change Threat";
BA_ "VNSigAllNodes" SG_ 2155028480 RgtLnChgThrt 1;
BA_ "SignalType" SG_ 2151915520 ElecShfRngDispRCExtd "UNM";
BA_ "SignalLongName" SG_ 2151915520 ElecShfRngDispRCExtd "Electronic Shift Range Display Rolling Count Extended";
BA_ "VNSigAllNodes" SG_ 2151915520 ElecShfRngDispRCExtd 1;
BA_ "SignalType" SG_ 2151915520 ElecShfRngDisp "ENM";
BA_ "SignalLongName" SG_ 2151915520 ElecShfRngDisp "Electronic Shift Range Display";
BA_ "VNSigAllNodes" SG_ 2151915520 ElecShfRngDisp 1;
BA_ "SignalType" SG_ 2151915520 ESPTransMalfIO "BLN";
BA_ "SignalLongName" SG_ 2151915520 ESPTransMalfIO "Electronic Shift Primary Transmission Malfunction Indication On";
BA_ "VNSigAllNodes" SG_ 2151915520 ESPTransMalfIO 1;
BA_ "SignalType" SG_ 2151915520 ESPRngInvldReqIO "BLN";
BA_ "SignalLongName" SG_ 2151915520 ESPRngInvldReqIO "Electronic Shift Primary Range Invalid Request Indication On";
BA_ "VNSigAllNodes" SG_ 2151915520 ESPRngInvldReqIO 1;
BA_ "SignalType" SG_ 2151915520 ESPPrkInvldReqIO "BLN";
BA_ "SignalLongName" SG_ 2151915520 ESPPrkInvldReqIO "Electronic Shift Primary Park Invalid Request Indication On";
BA_ "VNSigAllNodes" SG_ 2151915520 ESPPrkInvldReqIO 1;
BA_ "SignalType" SG_ 2151915520 ESPHldShfLvrToEngRgIO "BLN";
BA_ "SignalLongName" SG_ 2151915520 ESPHldShfLvrToEngRgIO "Electronic Shift Primary Hold Shift Lever to Engage Range Indication On";
BA_ "VNSigAllNodes" SG_ 2151915520 ESPHldShfLvrToEngRgIO 1;
BA_ "SignalType" SG_ 2151915520 ESPDrvrPrkIlkSftAtdIO "BLN";
BA_ "SignalLongName" SG_ 2151915520 ESPDrvrPrkIlkSftAtdIO "Electronic Shift Primary Driver Park Interlock Shift Attempted Indication On";
BA_ "VNSigAllNodes" SG_ 2151915520 ESPDrvrPrkIlkSftAtdIO 1;
BA_ "SignalType" SG_ 2151915520 ESPDrvrIlkShfAtdIO "BLN";
BA_ "SignalLongName" SG_ 2151915520 ESPDrvrIlkShfAtdIO "Electronic Shift Primary Driver Interlock Shift Attempted Indication On";
BA_ "VNSigAllNodes" SG_ 2151915520 ESPDrvrIlkShfAtdIO 1;
BA_ "SignalType" SG_ 2151915520 AHAct "BLN";
BA_ "SignalLongName" SG_ 2151915520 AHAct "Auto Hold Active";
BA_ "VNSigAllNodes" SG_ 2151915520 AHAct 1;
BA_ "SignalType" SG_ 2151915520 AHEnbld "BLN";
BA_ "SignalLongName" SG_ 2151915520 AHEnbld "Auto Hold Enabled";
BA_ "VNSigAllNodes" SG_ 2151915520 AHEnbld 1;
BA_ "SignalType" SG_ 2151915520 ShfToPrkBfExtngIO "BLN";
BA_ "SignalLongName" SG_ 2151915520 ShfToPrkBfExtngIO "Shift To Park Before Exiting Indication On";
BA_ "VNSigAllNodes" SG_ 2151915520 ShfToPrkBfExtngIO 1;
BA_ "SignalType" SG_ 2151915520 AHServcIO "BLN";
BA_ "SignalLongName" SG_ 2151915520 AHServcIO "Auto Hold Service Indication On";
BA_ "VNSigAllNodes" SG_ 2151915520 AHServcIO 1;
BA_ "SignalType" SG_ 2151915520 AHAppBrkPedlIO "BLN";
BA_ "SignalLongName" SG_ 2151915520 AHAppBrkPedlIO "Auto Hold Apply Brake Pedal Indication On";
BA_ "VNSigAllNodes" SG_ 2151915520 AHAppBrkPedlIO 1;
BA_ "SignalType" SG_ 2151915520 AHDisbldStbltIO "BLN";
BA_ "SignalLongName" SG_ 2151915520 AHDisbldStbltIO "Auto Hold Disabled Seatbelt Indication On";
BA_ "VNSigAllNodes" SG_ 2151915520 AHDisbldStbltIO 1;
BA_ "SignalType" SG_ 2151915520 AHDisbldDrOpnIO "BLN";
BA_ "SignalLongName" SG_ 2151915520 AHDisbldDrOpnIO "Auto Hold Disabled Door Open Indication On";
BA_ "VNSigAllNodes" SG_ 2151915520 AHDisbldDrOpnIO 1;
BA_ "SignalType" SG_ 2151915520 ElcTransRngSlctVDA "ENM";
BA_ "SignalLongName" SG_ 2151915520 ElcTransRngSlctVDA "Electronic Transmission Range Select Virtual Device Availability";
BA_ "GenSigStartValue" SG_ 2151915520 ElcTransRngSlctVDA 1;
BA_ "VNSigAllNodes" SG_ 2151915520 ElcTransRngSlctVDA 1;
BA_ "VNSigInfotainment" SG_ 2155364352 CstmrUsblSOCV 1;
BA_ "SignalType" SG_ 2155364352 CstmrUsblSOCV "ENM";
BA_ "SignalLongName" SG_ 2155364352 CstmrUsblSOCV "Customer Usable State of Charge Validity";
BA_ "VNSigAllNodes" SG_ 2155364352 CstmrUsblSOCV 1;
BA_ "GenSigDeltaValue" SG_ 2155364352 InstDrvEff 1;
BA_ "VNSigInfotainment" SG_ 2155364352 InstDrvEff 1;
BA_ "SignalType" SG_ 2155364352 InstDrvEff "SNM";
BA_ "SignalLongName" SG_ 2155364352 InstDrvEff "Instantaneous Drive Efficiency";
BA_ "VNSigAllNodes" SG_ 2155364352 InstDrvEff 1;
BA_ "VNSigInfotainment" SG_ 2155364352 BattCntrlPrcssrVDA 1;
BA_ "SignalType" SG_ 2155364352 BattCntrlPrcssrVDA "ENM";
BA_ "SignalLongName" SG_ 2155364352 BattCntrlPrcssrVDA "Battery Control Processor Virtual Device Availability";
BA_ "GenSigStartValue" SG_ 2155364352 BattCntrlPrcssrVDA 1;
BA_ "VNSigAllNodes" SG_ 2155364352 BattCntrlPrcssrVDA 1;
BA_ "VNSigInfotainment" SG_ 2155364352 JmpStrtStat 1;
BA_ "SignalType" SG_ 2155364352 JmpStrtStat "ENM";
BA_ "SignalLongName" SG_ 2155364352 JmpStrtStat "Jump Start Status";
BA_ "VNSigAllNodes" SG_ 2155364352 JmpStrtStat 1;
BA_ "GenSigDeltaValue" SG_ 2155364352 CstmrUsblSOC 1;
BA_ "VNSigInfotainment" SG_ 2155364352 CstmrUsblSOC 1;
BA_ "SignalType" SG_ 2155364352 CstmrUsblSOC "UNM";
BA_ "SignalLongName" SG_ 2155364352 CstmrUsblSOC "Customer Usable State of Charge";
BA_ "VNSigAllNodes" SG_ 2155364352 CstmrUsblSOC 1;
BA_ "VNSigInfotainment" SG_ 2155364352 SvcHybridSysIO 1;
BA_ "SignalType" SG_ 2155364352 SvcHybridSysIO "BLN";
BA_ "SignalLongName" SG_ 2155364352 SvcHybridSysIO "Service Hybrid System Indication On";
BA_ "VNSigAllNodes" SG_ 2155364352 SvcHybridSysIO 1;
BA_ "VNSigInfotainment" SG_ 2155364352 HybMdDisp 1;
BA_ "SignalType" SG_ 2155364352 HybMdDisp "ENM";
BA_ "SignalLongName" SG_ 2155364352 HybMdDisp "Hybrid Mode Display";
BA_ "VNSigAllNodes" SG_ 2155364352 HybMdDisp 1;
BA_ "GenSigDeltaValue" SG_ 2155364352 ClntCrcFlwRtEst 1;
BA_ "VNSigInfotainment" SG_ 2155364352 ClntCrcFlwRtEst 1;
BA_ "SignalType" SG_ 2155364352 ClntCrcFlwRtEst "UNM";
BA_ "SignalLongName" SG_ 2155364352 ClntCrcFlwRtEst "Coolant Circulation Flow Rate Estimated";
BA_ "VNSigAllNodes" SG_ 2155364352 ClntCrcFlwRtEst 1;
BA_ "SignalType" SG_ 2150260736 AV_Drv_Sys_Ena_Red "BLN";
BA_ "SignalLongName" SG_ 2150260736 AV_Drv_Sys_Ena_Red "Autonomous Drive System Enabled Redundant";
BA_ "VNSigAllNodes" SG_ 2150260736 AV_Drv_Sys_Ena_Red 1;
BA_ "SignalType" SG_ 2150260736 Rear_Etr_Swtch_Ena_Red "BLN";
BA_ "SignalLongName" SG_ 2150260736 Rear_Etr_Swtch_Ena_Red "Rear Ethernet Switches Enabled  Redundant";
BA_ "VNSigAllNodes" SG_ 2150260736 Rear_Etr_Swtch_Ena_Red 1;
BA_ "SignalType" SG_ 2150260736 AVrdcmpltrtndefRed "BLN";
BA_ "SignalLongName" SG_ 2150260736 AVrdcmpltrtndefRed "AV Ride Completed Return to Default setting Redundant";
BA_ "VNSigAllNodes" SG_ 2150260736 AVrdcmpltrtndefRed 1;
BA_ "SignalType" SG_ 2150260736 VehHlthMngrStBckup "ENM";
BA_ "SignalLongName" SG_ 2150260736 VehHlthMngrStBckup "Vehicle Health Manager Backup State";
BA_ "VNSigAllNodes" SG_ 2150260736 VehHlthMngrStBckup 1;
BA_ "SignalType" SG_ 2150260736 AutoVehMdBkcupChcksm "UNM";
BA_ "SignalLongName" SG_ 2150260736 AutoVehMdBkcupChcksm "Autonomous Vehicle Mode Backup Checksum";
BA_ "VNSigAllNodes" SG_ 2150260736 AutoVehMdBkcupChcksm 1;
BA_ "SignalType" SG_ 2150260736 AutoVehMdBckupARC "UNM";
BA_ "SignalLongName" SG_ 2150260736 AutoVehMdBckupARC "Autonomous Vehicle Mode Backup Alive Rolling Count";
BA_ "VNSigAllNodes" SG_ 2150260736 AutoVehMdBckupARC 1;
BA_ "SignalType" SG_ 2150260736 AutoVehMdBckup "ENM";
BA_ "SignalLongName" SG_ 2150260736 AutoVehMdBckup "Autonomous Vehicle Mode Backup";
BA_ "VNSigAllNodes" SG_ 2150260736 AutoVehMdBckup 1;
BA_ "GenSigSendType" SG_ 2152562688 BSCWB_ZnEnbd 10;
BA_ "SignalType" SG_ 2152562688 BSCWB_ZnEnbd "BLN";
BA_ "SignalLongName" SG_ 2152562688 BSCWB_ZnEnbd "Backup Sensor Cleaning Wash B: Zone Enabled";
BA_ "VNSigAllNodes" SG_ 2152562688 BSCWB_ZnEnbd 1;
BA_ "GenSigDeltaValue" SG_ 2152562688 BSCWB_Zn8 1;
BA_ "GenSigSendType" SG_ 2152562688 BSCWB_Zn8 12;
BA_ "SignalType" SG_ 2152562688 BSCWB_Zn8 "UNM";
BA_ "SignalLongName" SG_ 2152562688 BSCWB_Zn8 "Backup Sensor Cleaning Wash B: Zone 8";
BA_ "VNSigAllNodes" SG_ 2152562688 BSCWB_Zn8 1;
BA_ "GenSigDeltaValue" SG_ 2152562688 BSCWB_Zn7 1;
BA_ "GenSigSendType" SG_ 2152562688 BSCWB_Zn7 12;
BA_ "SignalType" SG_ 2152562688 BSCWB_Zn7 "UNM";
BA_ "SignalLongName" SG_ 2152562688 BSCWB_Zn7 "Backup Sensor Cleaning Wash B: Zone 7";
BA_ "VNSigAllNodes" SG_ 2152562688 BSCWB_Zn7 1;
BA_ "GenSigDeltaValue" SG_ 2152562688 BSCWB_Zn3 1;
BA_ "GenSigSendType" SG_ 2152562688 BSCWB_Zn3 12;
BA_ "SignalType" SG_ 2152562688 BSCWB_Zn3 "UNM";
BA_ "SignalLongName" SG_ 2152562688 BSCWB_Zn3 "Backup Sensor Cleaning Wash B: Zone 3";
BA_ "VNSigAllNodes" SG_ 2152562688 BSCWB_Zn3 1;
BA_ "GenSigDeltaValue" SG_ 2152562688 BSCWB_Zn2 1;
BA_ "GenSigSendType" SG_ 2152562688 BSCWB_Zn2 12;
BA_ "SignalType" SG_ 2152562688 BSCWB_Zn2 "UNM";
BA_ "SignalLongName" SG_ 2152562688 BSCWB_Zn2 "Backup Sensor Cleaning Wash B: Zone 2";
BA_ "VNSigAllNodes" SG_ 2152562688 BSCWB_Zn2 1;
BA_ "GenSigSendType" SG_ 2152562688 BSCAB_ZnEnbd 10;
BA_ "SignalType" SG_ 2152562688 BSCAB_ZnEnbd "BLN";
BA_ "SignalLongName" SG_ 2152562688 BSCAB_ZnEnbd "Backup Sensor Cleaning Air B: Zone Enabled";
BA_ "VNSigAllNodes" SG_ 2152562688 BSCAB_ZnEnbd 1;
BA_ "GenSigDeltaValue" SG_ 2152562688 BSCAB_Zn8 1;
BA_ "GenSigSendType" SG_ 2152562688 BSCAB_Zn8 12;
BA_ "SignalType" SG_ 2152562688 BSCAB_Zn8 "UNM";
BA_ "SignalLongName" SG_ 2152562688 BSCAB_Zn8 "Backup Sensor Cleaning Air B: Zone 8";
BA_ "VNSigAllNodes" SG_ 2152562688 BSCAB_Zn8 1;
BA_ "GenSigDeltaValue" SG_ 2152562688 BSCAB_Zn7 1;
BA_ "GenSigSendType" SG_ 2152562688 BSCAB_Zn7 12;
BA_ "SignalType" SG_ 2152562688 BSCAB_Zn7 "UNM";
BA_ "SignalLongName" SG_ 2152562688 BSCAB_Zn7 "Backup Sensor Cleaning Air B: Zone 7";
BA_ "VNSigAllNodes" SG_ 2152562688 BSCAB_Zn7 1;
BA_ "GenSigDeltaValue" SG_ 2152562688 BSCAB_Zn3 1;
BA_ "GenSigSendType" SG_ 2152562688 BSCAB_Zn3 12;
BA_ "SignalType" SG_ 2152562688 BSCAB_Zn3 "UNM";
BA_ "SignalLongName" SG_ 2152562688 BSCAB_Zn3 "Backup Sensor Cleaning Air B: Zone 3";
BA_ "VNSigAllNodes" SG_ 2152562688 BSCAB_Zn3 1;
BA_ "GenSigDeltaValue" SG_ 2152562688 BSCAB_Zn2 1;
BA_ "GenSigSendType" SG_ 2152562688 BSCAB_Zn2 12;
BA_ "SignalType" SG_ 2152562688 BSCAB_Zn2 "UNM";
BA_ "SignalLongName" SG_ 2152562688 BSCAB_Zn2 "Backup Sensor Cleaning Air B: Zone 2";
BA_ "VNSigAllNodes" SG_ 2152562688 BSCAB_Zn2 1;
BA_ "GenSigSendType" SG_ 2152112128 PMVSS_Disps 10;
BA_ "GenSigSendOnInit" SG_ 2152112128 PMVSS_Disps 2;
BA_ "SignalType" SG_ 2152112128 PMVSS_Disps "ENM";
BA_ "PacketOrder" SG_ 2152112128 PMVSS_Disps 11;
BA_ "SignalLongName" SG_ 2152112128 PMVSS_Disps "Performance Mode Visualization Screen Status : Displays";
BA_ "VNSigAllNodes" SG_ 2152112128 PMVSS_Disps 1;
BA_ "GenSigSendType" SG_ 2152112128 PMVSS_Exhst 10;
BA_ "GenSigSendOnInit" SG_ 2152112128 PMVSS_Exhst 2;
BA_ "SignalType" SG_ 2152112128 PMVSS_Exhst "ENM";
BA_ "PacketOrder" SG_ 2152112128 PMVSS_Exhst 10;
BA_ "SignalLongName" SG_ 2152112128 PMVSS_Exhst "Performance Mode Visualization Screen Status : Exhaust";
BA_ "VNSigAllNodes" SG_ 2152112128 PMVSS_Exhst 1;
BA_ "GenSigSendType" SG_ 2152112128 PMVSS_PsngrSeat 10;
BA_ "GenSigSendOnInit" SG_ 2152112128 PMVSS_PsngrSeat 2;
BA_ "SignalType" SG_ 2152112128 PMVSS_PsngrSeat "ENM";
BA_ "PacketOrder" SG_ 2152112128 PMVSS_PsngrSeat 9;
BA_ "SignalLongName" SG_ 2152112128 PMVSS_PsngrSeat "Performance Mode Visualization Screen Status : Passenger Seat";
BA_ "VNSigAllNodes" SG_ 2152112128 PMVSS_PsngrSeat 1;
BA_ "GenSigSendType" SG_ 2152112128 PMVSS_DrvrSeat 10;
BA_ "GenSigSendOnInit" SG_ 2152112128 PMVSS_DrvrSeat 2;
BA_ "SignalType" SG_ 2152112128 PMVSS_DrvrSeat "ENM";
BA_ "PacketOrder" SG_ 2152112128 PMVSS_DrvrSeat 8;
BA_ "SignalLongName" SG_ 2152112128 PMVSS_DrvrSeat "Performance Mode Visualization Screen Status : Driver Seat";
BA_ "VNSigAllNodes" SG_ 2152112128 PMVSS_DrvrSeat 1;
BA_ "GenSigSendType" SG_ 2152112128 PMVSS_AdptCrsCnt 10;
BA_ "GenSigSendOnInit" SG_ 2152112128 PMVSS_AdptCrsCnt 2;
BA_ "SignalType" SG_ 2152112128 PMVSS_AdptCrsCnt "ENM";
BA_ "PacketOrder" SG_ 2152112128 PMVSS_AdptCrsCnt 7;
BA_ "SignalLongName" SG_ 2152112128 PMVSS_AdptCrsCnt "Performance Mode Visualization Screen Status : Adaptive Cruise Control";
BA_ "VNSigAllNodes" SG_ 2152112128 PMVSS_AdptCrsCnt 1;
BA_ "GenSigSendType" SG_ 2152112128 PMVSS_Drvln 10;
BA_ "GenSigSendOnInit" SG_ 2152112128 PMVSS_Drvln 2;
BA_ "SignalType" SG_ 2152112128 PMVSS_Drvln "ENM";
BA_ "PacketOrder" SG_ 2152112128 PMVSS_Drvln 6;
BA_ "SignalLongName" SG_ 2152112128 PMVSS_Drvln "Performance Mode Visualization Screen Status : Driveline";
BA_ "VNSigAllNodes" SG_ 2152112128 PMVSS_Drvln 1;
BA_ "GenSigSendType" SG_ 2152112128 PMVSS_Susp 10;
BA_ "GenSigSendOnInit" SG_ 2152112128 PMVSS_Susp 2;
BA_ "SignalType" SG_ 2152112128 PMVSS_Susp "ENM";
BA_ "PacketOrder" SG_ 2152112128 PMVSS_Susp 5;
BA_ "SignalLongName" SG_ 2152112128 PMVSS_Susp "Performance Mode Visualization Screen Status : Suspension";
BA_ "VNSigAllNodes" SG_ 2152112128 PMVSS_Susp 1;
BA_ "GenSigSendType" SG_ 2152112128 PMVSS_Strng 10;
BA_ "GenSigSendOnInit" SG_ 2152112128 PMVSS_Strng 2;
BA_ "SignalType" SG_ 2152112128 PMVSS_Strng "ENM";
BA_ "PacketOrder" SG_ 2152112128 PMVSS_Strng 4;
BA_ "SignalLongName" SG_ 2152112128 PMVSS_Strng "Performance Mode Visualization Screen Status : Steering";
BA_ "VNSigAllNodes" SG_ 2152112128 PMVSS_Strng 1;
BA_ "GenSigSendType" SG_ 2152112128 PMVSS_Trans 10;
BA_ "GenSigSendOnInit" SG_ 2152112128 PMVSS_Trans 2;
BA_ "SignalType" SG_ 2152112128 PMVSS_Trans "ENM";
BA_ "PacketOrder" SG_ 2152112128 PMVSS_Trans 3;
BA_ "SignalLongName" SG_ 2152112128 PMVSS_Trans "Performance Mode Visualization Screen Status : Transmission";
BA_ "VNSigAllNodes" SG_ 2152112128 PMVSS_Trans 1;
BA_ "GenSigSendType" SG_ 2152112128 PMVSS_Eng 10;
BA_ "GenSigSendOnInit" SG_ 2152112128 PMVSS_Eng 2;
BA_ "SignalType" SG_ 2152112128 PMVSS_Eng "ENM";
BA_ "PacketOrder" SG_ 2152112128 PMVSS_Eng 2;
BA_ "SignalLongName" SG_ 2152112128 PMVSS_Eng "Performance Mode Visualization Screen Status : Engine";
BA_ "VNSigAllNodes" SG_ 2152112128 PMVSS_Eng 1;
BA_ "GenSigSendType" SG_ 2152112128 PMVSS_Snd 10;
BA_ "GenSigSendOnInit" SG_ 2152112128 PMVSS_Snd 2;
BA_ "SignalType" SG_ 2152112128 PMVSS_Snd "ENM";
BA_ "PacketOrder" SG_ 2152112128 PMVSS_Snd 1;
BA_ "SignalLongName" SG_ 2152112128 PMVSS_Snd "Performance Mode Visualization Screen Status : Sound";
BA_ "VNSigAllNodes" SG_ 2152112128 PMVSS_Snd 1;
BA_ "GenSigDeltaValue" SG_ 2153857024 TnDrvTrCtrlEvntsRpt 1;
BA_ "GenSigSendType" SG_ 2153857024 TnDrvTrCtrlEvntsRpt 12;
BA_ "GenSigSendOnInit" SG_ 2153857024 TnDrvTrCtrlEvntsRpt 2;
BA_ "SignalType" SG_ 2153857024 TnDrvTrCtrlEvntsRpt "UNM";
BA_ "SignalLongName" SG_ 2153857024 TnDrvTrCtrlEvntsRpt "Teen Driver Traction Control Events Report";
BA_ "VNSigAllNodes" SG_ 2153857024 TnDrvTrCtrlEvntsRpt 1;
BA_ "GenSigDeltaValue" SG_ 2153857024 TnDrvDrowDrvAlrtsRpt 1;
BA_ "GenSigSendType" SG_ 2153857024 TnDrvDrowDrvAlrtsRpt 12;
BA_ "GenSigSendOnInit" SG_ 2153857024 TnDrvDrowDrvAlrtsRpt 2;
BA_ "SignalType" SG_ 2153857024 TnDrvDrowDrvAlrtsRpt "UNM";
BA_ "SignalLongName" SG_ 2153857024 TnDrvDrowDrvAlrtsRpt "Teen Driver Drowsy Driver Alerts Report";
BA_ "VNSigAllNodes" SG_ 2153857024 TnDrvDrowDrvAlrtsRpt 1;
BA_ "GenSigSendType" SG_ 2153857024 TDRCADD_WOTEvnts 10;
BA_ "GenSigSendOnInit" SG_ 2153857024 TDRCADD_WOTEvnts 2;
BA_ "SignalType" SG_ 2153857024 TDRCADD_WOTEvnts "BLN";
BA_ "PacketOrder" SG_ 2153857024 TDRCADD_WOTEvnts 12;
BA_ "SignalLongName" SG_ 2153857024 TDRCADD_WOTEvnts "Teen Driver Report Card Available Display Data : Wide Open Throttle Events";
BA_ "VNSigAllNodes" SG_ 2153857024 TDRCADD_WOTEvnts 1;
BA_ "GenSigSendType" SG_ 2153857024 TDRCADD_LDWEvnts 10;
BA_ "GenSigSendOnInit" SG_ 2153857024 TDRCADD_LDWEvnts 2;
BA_ "SignalType" SG_ 2153857024 TDRCADD_LDWEvnts "BLN";
BA_ "PacketOrder" SG_ 2153857024 TDRCADD_LDWEvnts 13;
BA_ "SignalLongName" SG_ 2153857024 TDRCADD_LDWEvnts "Teen Driver Report Card Available Display Data : Lane Departure Warning Events";
BA_ "VNSigAllNodes" SG_ 2153857024 TDRCADD_LDWEvnts 1;
BA_ "GenSigSendType" SG_ 2153857024 TDRCADD_FCMBrEvts 10;
BA_ "GenSigSendOnInit" SG_ 2153857024 TDRCADD_FCMBrEvts 2;
BA_ "SignalType" SG_ 2153857024 TDRCADD_FCMBrEvts "BLN";
BA_ "PacketOrder" SG_ 2153857024 TDRCADD_FCMBrEvts 10;
BA_ "SignalLongName" SG_ 2153857024 TDRCADD_FCMBrEvts "Teen Driver Report Card Available Display Data : Forward Collision Mitigation Braking Events";
BA_ "VNSigAllNodes" SG_ 2153857024 TDRCADD_FCMBrEvts 1;
BA_ "GenSigSendType" SG_ 2153857024 TDRCADD_DrwDrvAlrt 10;
BA_ "GenSigSendOnInit" SG_ 2153857024 TDRCADD_DrwDrvAlrt 2;
BA_ "SignalType" SG_ 2153857024 TDRCADD_DrwDrvAlrt "BLN";
BA_ "PacketOrder" SG_ 2153857024 TDRCADD_DrwDrvAlrt 11;
BA_ "SignalLongName" SG_ 2153857024 TDRCADD_DrwDrvAlrt "Teen Driver Report Card Available Display Data : Drowsy Driver Alerts";
BA_ "VNSigAllNodes" SG_ 2153857024 TDRCADD_DrwDrvAlrt 1;
BA_ "GenSigSendType" SG_ 2153857024 TDRCADD_RCMBrEvts 10;
BA_ "GenSigSendOnInit" SG_ 2153857024 TDRCADD_RCMBrEvts 2;
BA_ "SignalType" SG_ 2153857024 TDRCADD_RCMBrEvts "BLN";
BA_ "PacketOrder" SG_ 2153857024 TDRCADD_RCMBrEvts 9;
BA_ "SignalLongName" SG_ 2153857024 TDRCADD_RCMBrEvts "Teen Driver Report Card Available Display Data : Reverse Collision Mitigation Braking Events";
BA_ "VNSigAllNodes" SG_ 2153857024 TDRCADD_RCMBrEvts 1;
BA_ "GenSigSendType" SG_ 2153857024 TDRCADD_FCImntAlrts 10;
BA_ "GenSigSendOnInit" SG_ 2153857024 TDRCADD_FCImntAlrts 2;
BA_ "SignalType" SG_ 2153857024 TDRCADD_FCImntAlrts "BLN";
BA_ "PacketOrder" SG_ 2153857024 TDRCADD_FCImntAlrts 8;
BA_ "SignalLongName" SG_ 2153857024 TDRCADD_FCImntAlrts "Teen Driver Report Card Available Display Data : Forward Collision Imminent Alerts";
BA_ "VNSigAllNodes" SG_ 2153857024 TDRCADD_FCImntAlrts 1;
BA_ "GenSigSendType" SG_ 2153857024 TDRCADD_FCHdwyAlrt 10;
BA_ "GenSigSendOnInit" SG_ 2153857024 TDRCADD_FCHdwyAlrt 2;
BA_ "SignalType" SG_ 2153857024 TDRCADD_FCHdwyAlrt "BLN";
BA_ "PacketOrder" SG_ 2153857024 TDRCADD_FCHdwyAlrt 7;
BA_ "SignalLongName" SG_ 2153857024 TDRCADD_FCHdwyAlrt "Teen Driver Report Card Available Display Data : Forward Collision Headway Alerts";
BA_ "VNSigAllNodes" SG_ 2153857024 TDRCADD_FCHdwyAlrt 1;
BA_ "GenSigSendType" SG_ 2153857024 TDRCADD_StCtrlEvnts 10;
BA_ "GenSigSendOnInit" SG_ 2153857024 TDRCADD_StCtrlEvnts 2;
BA_ "SignalType" SG_ 2153857024 TDRCADD_StCtrlEvnts "BLN";
BA_ "PacketOrder" SG_ 2153857024 TDRCADD_StCtrlEvnts 5;
BA_ "SignalLongName" SG_ 2153857024 TDRCADD_StCtrlEvnts "Teen Driver Report Card Available Display Data : Stability Control Events";
BA_ "VNSigAllNodes" SG_ 2153857024 TDRCADD_StCtrlEvnts 1;
BA_ "GenSigSendType" SG_ 2153857024 TDRCADD_ABSAtvEvt 10;
BA_ "GenSigSendOnInit" SG_ 2153857024 TDRCADD_ABSAtvEvt 2;
BA_ "SignalType" SG_ 2153857024 TDRCADD_ABSAtvEvt "BLN";
BA_ "PacketOrder" SG_ 2153857024 TDRCADD_ABSAtvEvt 6;
BA_ "SignalLongName" SG_ 2153857024 TDRCADD_ABSAtvEvt "Teen Driver Report Card Available Display Data : Antilock Braking System Active Events";
BA_ "VNSigAllNodes" SG_ 2153857024 TDRCADD_ABSAtvEvt 1;
BA_ "GenSigSendType" SG_ 2153857024 TDRCADD_TrCtrlEvnts 10;
BA_ "GenSigSendOnInit" SG_ 2153857024 TDRCADD_TrCtrlEvnts 2;
BA_ "SignalType" SG_ 2153857024 TDRCADD_TrCtrlEvnts "BLN";
BA_ "PacketOrder" SG_ 2153857024 TDRCADD_TrCtrlEvnts 4;
BA_ "SignalLongName" SG_ 2153857024 TDRCADD_TrCtrlEvnts "Teen Driver Report Card Available Display Data : Traction Control Events";
BA_ "VNSigAllNodes" SG_ 2153857024 TDRCADD_TrCtrlEvnts 1;
BA_ "GenSigSendType" SG_ 2153857024 TDRCADD_OvSpdEvnt 10;
BA_ "GenSigSendOnInit" SG_ 2153857024 TDRCADD_OvSpdEvnt 2;
BA_ "SignalType" SG_ 2153857024 TDRCADD_OvSpdEvnt "BLN";
BA_ "PacketOrder" SG_ 2153857024 TDRCADD_OvSpdEvnt 3;
BA_ "SignalLongName" SG_ 2153857024 TDRCADD_OvSpdEvnt "Teen Driver Report Card Available Display Data : Overspeed Events";
BA_ "VNSigAllNodes" SG_ 2153857024 TDRCADD_OvSpdEvnt 1;
BA_ "GenSigSendType" SG_ 2153857024 TDRCADD_DistDrvn 10;
BA_ "GenSigSendOnInit" SG_ 2153857024 TDRCADD_DistDrvn 2;
BA_ "SignalType" SG_ 2153857024 TDRCADD_DistDrvn "BLN";
BA_ "PacketOrder" SG_ 2153857024 TDRCADD_DistDrvn 2;
BA_ "SignalLongName" SG_ 2153857024 TDRCADD_DistDrvn "Teen Driver Report Card Available Display Data : Distance Driven";
BA_ "VNSigAllNodes" SG_ 2153857024 TDRCADD_DistDrvn 1;
BA_ "GenSigSendType" SG_ 2153857024 TDRCADD_MaxSpd 10;
BA_ "GenSigSendOnInit" SG_ 2153857024 TDRCADD_MaxSpd 2;
BA_ "SignalType" SG_ 2153857024 TDRCADD_MaxSpd "BLN";
BA_ "PacketOrder" SG_ 2153857024 TDRCADD_MaxSpd 1;
BA_ "SignalLongName" SG_ 2153857024 TDRCADD_MaxSpd "Teen Driver Report Card Available Display Data : Maximum Speed";
BA_ "VNSigAllNodes" SG_ 2153857024 TDRCADD_MaxSpd 1;
BA_ "GenSigDeltaValue" SG_ 2153857024 TnDrvStblCtrlEvntsRpt 1;
BA_ "GenSigSendType" SG_ 2153857024 TnDrvStblCtrlEvntsRpt 12;
BA_ "GenSigSendOnInit" SG_ 2153857024 TnDrvStblCtrlEvntsRpt 2;
BA_ "SignalType" SG_ 2153857024 TnDrvStblCtrlEvntsRpt "UNM";
BA_ "SignalLongName" SG_ 2153857024 TnDrvStblCtrlEvntsRpt "Teen Driver Stability Control Events Report";
BA_ "VNSigAllNodes" SG_ 2153857024 TnDrvStblCtrlEvntsRpt 1;
BA_ "GenSigDeltaValue" SG_ 2153857024 TnDrvABSAtvEvntsRpt 1;
BA_ "GenSigSendType" SG_ 2153857024 TnDrvABSAtvEvntsRpt 12;
BA_ "GenSigSendOnInit" SG_ 2153857024 TnDrvABSAtvEvntsRpt 2;
BA_ "SignalType" SG_ 2153857024 TnDrvABSAtvEvntsRpt "UNM";
BA_ "SignalLongName" SG_ 2153857024 TnDrvABSAtvEvntsRpt "Teen Driver Antilock Brake System Active Events Report";
BA_ "VNSigAllNodes" SG_ 2153857024 TnDrvABSAtvEvntsRpt 1;
BA_ "GenSigDeltaValue" SG_ 2153857024 TeenDrvWOTEvntsRpt 1;
BA_ "GenSigSendType" SG_ 2153857024 TeenDrvWOTEvntsRpt 12;
BA_ "GenSigSendOnInit" SG_ 2153857024 TeenDrvWOTEvntsRpt 2;
BA_ "SignalType" SG_ 2153857024 TeenDrvWOTEvntsRpt "UNM";
BA_ "SignalLongName" SG_ 2153857024 TeenDrvWOTEvntsRpt "Teen Driver Wide Open Throttle Events Report";
BA_ "VNSigAllNodes" SG_ 2153857024 TeenDrvWOTEvntsRpt 1;
BA_ "GenSigSendType" SG_ 2153865216 TeenDrvReq 10;
BA_ "SignalType" SG_ 2153865216 TeenDrvReq "ENM";
BA_ "SignalLongName" SG_ 2153865216 TeenDrvReq "Teen Driver Request";
BA_ "VNSigAllNodes" SG_ 2153865216 TeenDrvReq 1;
BA_ "GenSigDeltaValue" SG_ 2153865216 TeenDrvPinCd 1;
BA_ "GenSigSendType" SG_ 2153865216 TeenDrvPinCd 12;
BA_ "SignalType" SG_ 2153865216 TeenDrvPinCd "BCD";
BA_ "SignalLongName" SG_ 2153865216 TeenDrvPinCd "Teen Driver PIN Code";
BA_ "VNSigAllNodes" SG_ 2153865216 TeenDrvPinCd 1;
BA_ "GenSigSendType" SG_ 2153865216 TnDrvSpdLmtCstStReq 10;
BA_ "SignalType" SG_ 2153865216 TnDrvSpdLmtCstStReq "ENM";
BA_ "SignalLongName" SG_ 2153865216 TnDrvSpdLmtCstStReq "Teen Driver Speed Limit Customization Setting Request";
BA_ "VNSigAllNodes" SG_ 2153865216 TnDrvSpdLmtCstStReq 1;
BA_ "GenSigSendType" SG_ 2153865216 TDOWCSR_StatReq 10;
BA_ "SignalType" SG_ 2153865216 TDOWCSR_StatReq "ENM";
BA_ "PacketOrder" SG_ 2153865216 TDOWCSR_StatReq 1;
BA_ "SignalLongName" SG_ 2153865216 TDOWCSR_StatReq "Teen Driver Overspeed Warning Customization Setting Request : Status Request";
BA_ "VNSigAllNodes" SG_ 2153865216 TDOWCSR_StatReq 1;
BA_ "GenSigSendType" SG_ 2153865216 TDOWCSR_IncSwAct 10;
BA_ "SignalType" SG_ 2153865216 TDOWCSR_IncSwAct "BLN";
BA_ "PacketOrder" SG_ 2153865216 TDOWCSR_IncSwAct 2;
BA_ "SignalLongName" SG_ 2153865216 TDOWCSR_IncSwAct "Teen Driver Overspeed Warning Customization Setting Request : Increment  Switch Active";
BA_ "VNSigAllNodes" SG_ 2153865216 TDOWCSR_IncSwAct 1;
BA_ "GenSigSendType" SG_ 2153865216 TDOWCSR_DecSwAct 10;
BA_ "SignalType" SG_ 2153865216 TDOWCSR_DecSwAct "BLN";
BA_ "PacketOrder" SG_ 2153865216 TDOWCSR_DecSwAct 3;
BA_ "SignalLongName" SG_ 2153865216 TDOWCSR_DecSwAct "Teen Driver Overspeed Warning Customization Setting Request : Decrement  Switch Active";
BA_ "VNSigAllNodes" SG_ 2153865216 TDOWCSR_DecSwAct 1;
BA_ "GenSigSendType" SG_ 2153840640 TnDrvDRLOffUnbIO 10;
BA_ "SignalType" SG_ 2153840640 TnDrvDRLOffUnbIO "BLN";
BA_ "SignalLongName" SG_ 2153840640 TnDrvDRLOffUnbIO "Teen Driver Daytime Running Lights Off Unavailable Indication On";
BA_ "VNSigAllNodes" SG_ 2153840640 TnDrvDRLOffUnbIO 1;
BA_ "GenSigSendType" SG_ 2153840640 TnDrvALCOffUnbIO 10;
BA_ "SignalType" SG_ 2153840640 TnDrvALCOffUnbIO "BLN";
BA_ "SignalLongName" SG_ 2153840640 TnDrvALCOffUnbIO "Teen Driver Automatic Light Control Off Unavailable Indication On";
BA_ "VNSigAllNodes" SG_ 2153840640 TnDrvALCOffUnbIO 1;
BA_ "GenSigDeltaValue" SG_ 2153840640 TeenDrvLDWEvntsRpt 1;
BA_ "GenSigSendType" SG_ 2153840640 TeenDrvLDWEvntsRpt 12;
BA_ "GenSigSendOnInit" SG_ 2153840640 TeenDrvLDWEvntsRpt 2;
BA_ "SignalType" SG_ 2153840640 TeenDrvLDWEvntsRpt "UNM";
BA_ "SignalLongName" SG_ 2153840640 TeenDrvLDWEvntsRpt "Teen Driver Lane Departure Warning Events Report";
BA_ "VNSigAllNodes" SG_ 2153840640 TeenDrvLDWEvntsRpt 1;
BA_ "GenSigDeltaValue" SG_ 2153840640 TeenDrvMaxSpdRpt 1;
BA_ "GenSigSendType" SG_ 2153840640 TeenDrvMaxSpdRpt 12;
BA_ "GenSigSendOnInit" SG_ 2153840640 TeenDrvMaxSpdRpt 2;
BA_ "SignalType" SG_ 2153840640 TeenDrvMaxSpdRpt "UNM";
BA_ "SignalLongName" SG_ 2153840640 TeenDrvMaxSpdRpt "Teen Driver Maximum Speed Report";
BA_ "VNSigAllNodes" SG_ 2153840640 TeenDrvMaxSpdRpt 1;
BA_ "GenSigDeltaValue" SG_ 2153840640 TDFwdClnImntAlrtsRpt 1;
BA_ "GenSigSendType" SG_ 2153840640 TDFwdClnImntAlrtsRpt 12;
BA_ "GenSigSendOnInit" SG_ 2153840640 TDFwdClnImntAlrtsRpt 2;
BA_ "SignalType" SG_ 2153840640 TDFwdClnImntAlrtsRpt "UNM";
BA_ "SignalLongName" SG_ 2153840640 TDFwdClnImntAlrtsRpt "Teen Driver Forward Collision Imminent Alerts Report";
BA_ "VNSigAllNodes" SG_ 2153840640 TDFwdClnImntAlrtsRpt 1;
BA_ "GenSigDeltaValue" SG_ 2153840640 TDRevClnMtgnBrEvRpt 1;
BA_ "GenSigSendType" SG_ 2153840640 TDRevClnMtgnBrEvRpt 12;
BA_ "GenSigSendOnInit" SG_ 2153840640 TDRevClnMtgnBrEvRpt 2;
BA_ "SignalType" SG_ 2153840640 TDRevClnMtgnBrEvRpt "UNM";
BA_ "SignalLongName" SG_ 2153840640 TDRevClnMtgnBrEvRpt "Teen Driver Reverse Collision Mitigation Braking Events Report";
BA_ "VNSigAllNodes" SG_ 2153840640 TDRevClnMtgnBrEvRpt 1;
BA_ "GenSigDeltaValue" SG_ 2153840640 TDFwdClnMtgnBrEvRpt 1;
BA_ "GenSigSendType" SG_ 2153840640 TDFwdClnMtgnBrEvRpt 12;
BA_ "GenSigSendOnInit" SG_ 2153840640 TDFwdClnMtgnBrEvRpt 2;
BA_ "SignalType" SG_ 2153840640 TDFwdClnMtgnBrEvRpt "UNM";
BA_ "SignalLongName" SG_ 2153840640 TDFwdClnMtgnBrEvRpt "Teen Driver Forward Collision Mitigation Braking Events Report";
BA_ "VNSigAllNodes" SG_ 2153840640 TDFwdClnMtgnBrEvRpt 1;
BA_ "GenSigDeltaValue" SG_ 2153840640 TDFwdClnHdwyAlrtsRpt 1;
BA_ "GenSigSendType" SG_ 2153840640 TDFwdClnHdwyAlrtsRpt 12;
BA_ "GenSigSendOnInit" SG_ 2153840640 TDFwdClnHdwyAlrtsRpt 2;
BA_ "SignalType" SG_ 2153840640 TDFwdClnHdwyAlrtsRpt "UNM";
BA_ "SignalLongName" SG_ 2153840640 TDFwdClnHdwyAlrtsRpt "Teen Driver Forward Collision Headway Alerts Report";
BA_ "VNSigAllNodes" SG_ 2153840640 TDFwdClnHdwyAlrtsRpt 1;
BA_ "GenSigDeltaValue" SG_ 2153824256 TeenDrvDistDrvnRpt 1;
BA_ "GenSigSendType" SG_ 2153824256 TeenDrvDistDrvnRpt 12;
BA_ "GenSigSendOnInit" SG_ 2153824256 TeenDrvDistDrvnRpt 2;
BA_ "SignalType" SG_ 2153824256 TeenDrvDistDrvnRpt "UNM";
BA_ "SignalLongName" SG_ 2153824256 TeenDrvDistDrvnRpt "Teen Driver Distance Driven Report";
BA_ "VNSigAllNodes" SG_ 2153824256 TeenDrvDistDrvnRpt 1;
BA_ "GenSigDeltaValue" SG_ 2153824256 TnDrvOvSpdEvntsRpt 1;
BA_ "GenSigSendType" SG_ 2153824256 TnDrvOvSpdEvntsRpt 12;
BA_ "GenSigSendOnInit" SG_ 2153824256 TnDrvOvSpdEvntsRpt 2;
BA_ "SignalType" SG_ 2153824256 TnDrvOvSpdEvntsRpt "UNM";
BA_ "SignalLongName" SG_ 2153824256 TnDrvOvSpdEvntsRpt "Teen Driver Overspeed Events Report";
BA_ "VNSigAllNodes" SG_ 2153824256 TnDrvOvSpdEvntsRpt 1;
BA_ "GenSigSendType" SG_ 2153824256 TeenDrvAct 10;
BA_ "GenSigSendOnInit" SG_ 2153824256 TeenDrvAct 2;
BA_ "SignalType" SG_ 2153824256 TeenDrvAct "BLN";
BA_ "SignalLongName" SG_ 2153824256 TeenDrvAct "Teen Driver Active";
BA_ "VNSigAllNodes" SG_ 2153824256 TeenDrvAct 1;
BA_ "GenSigSendType" SG_ 2153824256 TeenDrvRsp 10;
BA_ "GenSigSendOnInit" SG_ 2153824256 TeenDrvRsp 2;
BA_ "SignalType" SG_ 2153824256 TeenDrvRsp "ENM";
BA_ "SignalLongName" SG_ 2153824256 TeenDrvRsp "Teen Driver Response";
BA_ "VNSigAllNodes" SG_ 2153824256 TeenDrvRsp 1;
BA_ "GenSigSendType" SG_ 2153824256 TeenDrvFtrAvl 10;
BA_ "GenSigSendOnInit" SG_ 2153824256 TeenDrvFtrAvl 2;
BA_ "SignalType" SG_ 2153824256 TeenDrvFtrAvl "BLN";
BA_ "SignalLongName" SG_ 2153824256 TeenDrvFtrAvl "Teen Driver Feature Available";
BA_ "VNSigAllNodes" SG_ 2153824256 TeenDrvFtrAvl 1;
BA_ "GenSigSendType" SG_ 2153824256 TeenDrvPINStrd 10;
BA_ "GenSigSendOnInit" SG_ 2153824256 TeenDrvPINStrd 2;
BA_ "SignalType" SG_ 2153824256 TeenDrvPINStrd "BLN";
BA_ "SignalLongName" SG_ 2153824256 TeenDrvPINStrd "Teen Driver PIN Stored";
BA_ "VNSigAllNodes" SG_ 2153824256 TeenDrvPINStrd 1;
BA_ "GenSigSendType" SG_ 2153824256 TnDrvGapAdjUnbIO 10;
BA_ "SignalType" SG_ 2153824256 TnDrvGapAdjUnbIO "BLN";
BA_ "SignalLongName" SG_ 2153824256 TnDrvGapAdjUnbIO "Teen Driver Gap Adjust Unavailable Indication On";
BA_ "VNSigAllNodes" SG_ 2153824256 TnDrvGapAdjUnbIO 1;
BA_ "GenSigSendType" SG_ 2153824256 TnDrvOvrSpdIO 10;
BA_ "SignalType" SG_ 2153824256 TnDrvOvrSpdIO "BLN";
BA_ "SignalLongName" SG_ 2153824256 TnDrvOvrSpdIO "Teen Driver Overspeed Indication On";
BA_ "VNSigAllNodes" SG_ 2153824256 TnDrvOvrSpdIO 1;
BA_ "GenSigSendType" SG_ 2153824256 TDOvSpdWrnCstStAvl 10;
BA_ "GenSigSendOnInit" SG_ 2153824256 TDOvSpdWrnCstStAvl 2;
BA_ "SignalType" SG_ 2153824256 TDOvSpdWrnCstStAvl "BLN";
BA_ "SignalLongName" SG_ 2153824256 TDOvSpdWrnCstStAvl "Teen Driver Overspeed Warning Customization Setting Available";
BA_ "VNSigAllNodes" SG_ 2153824256 TDOvSpdWrnCstStAvl 1;
BA_ "GenSigDeltaValue" SG_ 2153824256 TDOWCCSV_CrStVl 1;
BA_ "GenSigSendType" SG_ 2153824256 TDOWCCSV_CrStVl 12;
BA_ "GenSigSendOnInit" SG_ 2153824256 TDOWCCSV_CrStVl 2;
BA_ "SignalType" SG_ 2153824256 TDOWCCSV_CrStVl "UNM";
BA_ "PacketOrder" SG_ 2153824256 TDOWCCSV_CrStVl 2;
BA_ "SignalLongName" SG_ 2153824256 TDOWCCSV_CrStVl "Teen Driver Overspeed Warning Customization Current Setting Value : Current Setting Value";
BA_ "VNSigAllNodes" SG_ 2153824256 TDOWCCSV_CrStVl 1;
BA_ "GenSigSendType" SG_ 2153824256 TDOWCCSV_CrStat 10;
BA_ "GenSigSendOnInit" SG_ 2153824256 TDOWCCSV_CrStat 2;
BA_ "SignalType" SG_ 2153824256 TDOWCCSV_CrStat "ENM";
BA_ "PacketOrder" SG_ 2153824256 TDOWCCSV_CrStat 1;
BA_ "SignalLongName" SG_ 2153824256 TDOWCCSV_CrStat "Teen Driver Overspeed Warning Customization Current Setting Value : Current Status";
BA_ "VNSigAllNodes" SG_ 2153824256 TDOWCCSV_CrStat 1;
BA_ "GenSigSendType" SG_ 2153824256 TnDrvSpdLmtCstStAvl 10;
BA_ "GenSigSendOnInit" SG_ 2153824256 TnDrvSpdLmtCstStAvl 2;
BA_ "SignalType" SG_ 2153824256 TnDrvSpdLmtCstStAvl "BLN";
BA_ "SignalLongName" SG_ 2153824256 TnDrvSpdLmtCstStAvl "Teen Driver Speed Limit Customization Setting Available";
BA_ "VNSigAllNodes" SG_ 2153824256 TnDrvSpdLmtCstStAvl 1;
BA_ "GenSigSendType" SG_ 2153824256 TDSLCCSV_SpLmtStat 10;
BA_ "GenSigSendOnInit" SG_ 2153824256 TDSLCCSV_SpLmtStat 2;
BA_ "SignalType" SG_ 2153824256 TDSLCCSV_SpLmtStat "ENM";
BA_ "PacketOrder" SG_ 2153824256 TDSLCCSV_SpLmtStat 1;
BA_ "SignalLongName" SG_ 2153824256 TDSLCCSV_SpLmtStat "Teen Driver Speed Limit Customization Current Setting Value : Speed Limit Status";
BA_ "VNSigAllNodes" SG_ 2153824256 TDSLCCSV_SpLmtStat 1;
BA_ "GenSigDeltaValue" SG_ 2153824256 TDSLCCSV_SpLmDisVl 1;
BA_ "GenSigSendType" SG_ 2153824256 TDSLCCSV_SpLmDisVl 12;
BA_ "GenSigSendOnInit" SG_ 2153824256 TDSLCCSV_SpLmDisVl 2;
BA_ "SignalType" SG_ 2153824256 TDSLCCSV_SpLmDisVl "UNM";
BA_ "PacketOrder" SG_ 2153824256 TDSLCCSV_SpLmDisVl 2;
BA_ "SignalLongName" SG_ 2153824256 TDSLCCSV_SpLmDisVl "Teen Driver Speed Limit Customization Current Setting Value : Speed Limit Display Value";
BA_ "VNSigAllNodes" SG_ 2153824256 TDSLCCSV_SpLmDisVl 1;
BA_ "GenSigSendType" SG_ 2150252544 ECHG_YAxisMaxVal 10;
BA_ "GenSigSendOnInit" SG_ 2150252544 ECHG_YAxisMaxVal 1;
BA_ "VNSigInfotainment" SG_ 2150252544 ECHG_YAxisMaxVal 1;
BA_ "SignalType" SG_ 2150252544 ECHG_YAxisMaxVal "ENM";
BA_ "PacketOrder" SG_ 2150252544 ECHG_YAxisMaxVal 14;
BA_ "SignalLongName" SG_ 2150252544 ECHG_YAxisMaxVal "Energy Consumption History Graph : Y Axis Maximum Value";
BA_ "VNSigAllNodes" SG_ 2150252544 ECHG_YAxisMaxVal 1;
BA_ "GenSigSendType" SG_ 2150252544 ECHG_XAxisTkMrkIntvl 10;
BA_ "GenSigSendOnInit" SG_ 2150252544 ECHG_XAxisTkMrkIntvl 1;
BA_ "VNSigInfotainment" SG_ 2150252544 ECHG_XAxisTkMrkIntvl 1;
BA_ "SignalType" SG_ 2150252544 ECHG_XAxisTkMrkIntvl "ENM";
BA_ "PacketOrder" SG_ 2150252544 ECHG_XAxisTkMrkIntvl 13;
BA_ "SignalLongName" SG_ 2150252544 ECHG_XAxisTkMrkIntvl "Energy Consumption History Graph : X Axis Tick Mark Interval";
BA_ "VNSigAllNodes" SG_ 2150252544 ECHG_XAxisTkMrkIntvl 1;
BA_ "GenSigDeltaValue" SG_ 2150252544 ECHG_Column10 1;
BA_ "GenSigSendType" SG_ 2150252544 ECHG_Column10 12;
BA_ "GenSigSendOnInit" SG_ 2150252544 ECHG_Column10 1;
BA_ "VNSigInfotainment" SG_ 2150252544 ECHG_Column10 1;
BA_ "SignalType" SG_ 2150252544 ECHG_Column10 "UNM";
BA_ "PacketOrder" SG_ 2150252544 ECHG_Column10 12;
BA_ "SignalLongName" SG_ 2150252544 ECHG_Column10 "Energy Consumption History Graph : Column 10";
BA_ "VNSigAllNodes" SG_ 2150252544 ECHG_Column10 1;
BA_ "GenSigDeltaValue" SG_ 2150252544 ECHG_Column09 1;
BA_ "GenSigSendType" SG_ 2150252544 ECHG_Column09 12;
BA_ "GenSigSendOnInit" SG_ 2150252544 ECHG_Column09 1;
BA_ "VNSigInfotainment" SG_ 2150252544 ECHG_Column09 1;
BA_ "SignalType" SG_ 2150252544 ECHG_Column09 "UNM";
BA_ "PacketOrder" SG_ 2150252544 ECHG_Column09 11;
BA_ "SignalLongName" SG_ 2150252544 ECHG_Column09 "Energy Consumption History Graph : Column 09";
BA_ "VNSigAllNodes" SG_ 2150252544 ECHG_Column09 1;
BA_ "GenSigDeltaValue" SG_ 2150252544 ECHG_Column08 1;
BA_ "GenSigSendType" SG_ 2150252544 ECHG_Column08 12;
BA_ "GenSigSendOnInit" SG_ 2150252544 ECHG_Column08 1;
BA_ "VNSigInfotainment" SG_ 2150252544 ECHG_Column08 1;
BA_ "SignalType" SG_ 2150252544 ECHG_Column08 "UNM";
BA_ "PacketOrder" SG_ 2150252544 ECHG_Column08 10;
BA_ "SignalLongName" SG_ 2150252544 ECHG_Column08 "Energy Consumption History Graph : Column 08";
BA_ "VNSigAllNodes" SG_ 2150252544 ECHG_Column08 1;
BA_ "GenSigDeltaValue" SG_ 2150252544 ECHG_Column07 1;
BA_ "GenSigSendType" SG_ 2150252544 ECHG_Column07 12;
BA_ "GenSigSendOnInit" SG_ 2150252544 ECHG_Column07 1;
BA_ "VNSigInfotainment" SG_ 2150252544 ECHG_Column07 1;
BA_ "SignalType" SG_ 2150252544 ECHG_Column07 "UNM";
BA_ "PacketOrder" SG_ 2150252544 ECHG_Column07 9;
BA_ "SignalLongName" SG_ 2150252544 ECHG_Column07 "Energy Consumption History Graph : Column 07";
BA_ "VNSigAllNodes" SG_ 2150252544 ECHG_Column07 1;
BA_ "GenSigDeltaValue" SG_ 2150252544 ECHG_Column06 1;
BA_ "GenSigSendType" SG_ 2150252544 ECHG_Column06 12;
BA_ "GenSigSendOnInit" SG_ 2150252544 ECHG_Column06 1;
BA_ "VNSigInfotainment" SG_ 2150252544 ECHG_Column06 1;
BA_ "SignalType" SG_ 2150252544 ECHG_Column06 "UNM";
BA_ "PacketOrder" SG_ 2150252544 ECHG_Column06 8;
BA_ "SignalLongName" SG_ 2150252544 ECHG_Column06 "Energy Consumption History Graph : Column 06";
BA_ "VNSigAllNodes" SG_ 2150252544 ECHG_Column06 1;
BA_ "GenSigDeltaValue" SG_ 2150252544 ECHG_Column05 1;
BA_ "GenSigSendType" SG_ 2150252544 ECHG_Column05 12;
BA_ "GenSigSendOnInit" SG_ 2150252544 ECHG_Column05 1;
BA_ "VNSigInfotainment" SG_ 2150252544 ECHG_Column05 1;
BA_ "SignalType" SG_ 2150252544 ECHG_Column05 "UNM";
BA_ "PacketOrder" SG_ 2150252544 ECHG_Column05 7;
BA_ "SignalLongName" SG_ 2150252544 ECHG_Column05 "Energy Consumption History Graph : Column 05";
BA_ "VNSigAllNodes" SG_ 2150252544 ECHG_Column05 1;
BA_ "GenSigDeltaValue" SG_ 2150252544 ECHG_Column04 1;
BA_ "GenSigSendType" SG_ 2150252544 ECHG_Column04 12;
BA_ "GenSigSendOnInit" SG_ 2150252544 ECHG_Column04 1;
BA_ "VNSigInfotainment" SG_ 2150252544 ECHG_Column04 1;
BA_ "SignalType" SG_ 2150252544 ECHG_Column04 "UNM";
BA_ "PacketOrder" SG_ 2150252544 ECHG_Column04 6;
BA_ "SignalLongName" SG_ 2150252544 ECHG_Column04 "Energy Consumption History Graph : Column 04";
BA_ "VNSigAllNodes" SG_ 2150252544 ECHG_Column04 1;
BA_ "GenSigDeltaValue" SG_ 2150252544 ECHG_Column03 1;
BA_ "GenSigSendType" SG_ 2150252544 ECHG_Column03 12;
BA_ "GenSigSendOnInit" SG_ 2150252544 ECHG_Column03 1;
BA_ "VNSigInfotainment" SG_ 2150252544 ECHG_Column03 1;
BA_ "SignalType" SG_ 2150252544 ECHG_Column03 "UNM";
BA_ "PacketOrder" SG_ 2150252544 ECHG_Column03 5;
BA_ "SignalLongName" SG_ 2150252544 ECHG_Column03 "Energy Consumption History Graph : Column 03";
BA_ "VNSigAllNodes" SG_ 2150252544 ECHG_Column03 1;
BA_ "GenSigDeltaValue" SG_ 2150252544 ECHG_Column02 1;
BA_ "GenSigSendType" SG_ 2150252544 ECHG_Column02 12;
BA_ "GenSigSendOnInit" SG_ 2150252544 ECHG_Column02 1;
BA_ "VNSigInfotainment" SG_ 2150252544 ECHG_Column02 1;
BA_ "SignalType" SG_ 2150252544 ECHG_Column02 "UNM";
BA_ "PacketOrder" SG_ 2150252544 ECHG_Column02 4;
BA_ "SignalLongName" SG_ 2150252544 ECHG_Column02 "Energy Consumption History Graph : Column 02";
BA_ "VNSigAllNodes" SG_ 2150252544 ECHG_Column02 1;
BA_ "GenSigDeltaValue" SG_ 2150252544 ECHG_Column01 1;
BA_ "GenSigSendType" SG_ 2150252544 ECHG_Column01 12;
BA_ "GenSigSendOnInit" SG_ 2150252544 ECHG_Column01 1;
BA_ "VNSigInfotainment" SG_ 2150252544 ECHG_Column01 1;
BA_ "SignalType" SG_ 2150252544 ECHG_Column01 "UNM";
BA_ "PacketOrder" SG_ 2150252544 ECHG_Column01 3;
BA_ "SignalLongName" SG_ 2150252544 ECHG_Column01 "Energy Consumption History Graph : Column 01";
BA_ "VNSigAllNodes" SG_ 2150252544 ECHG_Column01 1;
BA_ "GenSigDeltaValue" SG_ 2150252544 ECHG_EngyCnsmdAvg 1;
BA_ "GenSigSendType" SG_ 2150252544 ECHG_EngyCnsmdAvg 12;
BA_ "GenSigSendOnInit" SG_ 2150252544 ECHG_EngyCnsmdAvg 1;
BA_ "VNSigInfotainment" SG_ 2150252544 ECHG_EngyCnsmdAvg 1;
BA_ "SignalType" SG_ 2150252544 ECHG_EngyCnsmdAvg "UNM";
BA_ "PacketOrder" SG_ 2150252544 ECHG_EngyCnsmdAvg 2;
BA_ "SignalLongName" SG_ 2150252544 ECHG_EngyCnsmdAvg "Energy Consumption History Graph : Energy Consumed Average";
BA_ "VNSigAllNodes" SG_ 2150252544 ECHG_EngyCnsmdAvg 1;
BA_ "GenSigSendType" SG_ 2150252544 ECHG_MeasUnit 10;
BA_ "GenSigSendOnInit" SG_ 2150252544 ECHG_MeasUnit 1;
BA_ "VNSigInfotainment" SG_ 2150252544 ECHG_MeasUnit 1;
BA_ "SignalType" SG_ 2150252544 ECHG_MeasUnit "ENM";
BA_ "PacketOrder" SG_ 2150252544 ECHG_MeasUnit 1;
BA_ "SignalLongName" SG_ 2150252544 ECHG_MeasUnit "Energy Consumption History Graph : Measurement Unit";
BA_ "VNSigAllNodes" SG_ 2150252544 ECHG_MeasUnit 1;
BA_ "GenSigDeltaValue" SG_ 2150391808 EngRunAtvTm 1;
BA_ "GenSigSendType" SG_ 2150391808 EngRunAtvTm 12;
BA_ "GenSigSendOnInit" SG_ 2150391808 EngRunAtvTm 1;
BA_ "SignalType" SG_ 2150391808 EngRunAtvTm "UNM";
BA_ "SignalLongName" SG_ 2150391808 EngRunAtvTm "Engine Run Active Time";
BA_ "VNSigAllNodes" SG_ 2150391808 EngRunAtvTm 1;
BA_ "GenSigDeltaValue" SG_ 2150391808 EngIdlAtvTm 1;
BA_ "GenSigSendType" SG_ 2150391808 EngIdlAtvTm 12;
BA_ "GenSigSendOnInit" SG_ 2150391808 EngIdlAtvTm 1;
BA_ "SignalType" SG_ 2150391808 EngIdlAtvTm "UNM";
BA_ "SignalLongName" SG_ 2150391808 EngIdlAtvTm "Engine Idle Active Time";
BA_ "VNSigAllNodes" SG_ 2150391808 EngIdlAtvTm 1;
BA_ "SignalType" SG_ 2155913216 PFAS_SrvPedAlrtIO "BLN";
BA_ "PacketOrder" SG_ 2155913216 PFAS_SrvPedAlrtIO 7;
BA_ "SignalLongName" SG_ 2155913216 PFAS_SrvPedAlrtIO "Pedestrian Friendly Alert Status : Service Pedestrian Friendly Alert Indication On";
BA_ "VNSigAllNodes" SG_ 2155913216 PFAS_SrvPedAlrtIO 1;
BA_ "SignalType" SG_ 2155913216 PFAS_PFASysStat "ENM";
BA_ "PacketOrder" SG_ 2155913216 PFAS_PFASysStat 6;
BA_ "SignalLongName" SG_ 2155913216 PFAS_PFASysStat "Pedestrian Friendly Alert Status : Pedestrian Friendly Alert System Status";
BA_ "VNSigAllNodes" SG_ 2155913216 PFAS_PFASysStat 1;
BA_ "SignalType" SG_ 2155913216 PFAS_PFASndVolCtrl "UNM";
BA_ "PacketOrder" SG_ 2155913216 PFAS_PFASndVolCtrl 5;
BA_ "SignalLongName" SG_ 2155913216 PFAS_PFASndVolCtrl "Pedestrian Friendly Alert Status : Pedestrian Friendly Alert Sound Volume Control";
BA_ "VNSigAllNodes" SG_ 2155913216 PFAS_PFASndVolCtrl 1;
BA_ "SignalType" SG_ 2155913216 PFAS_PFASndGenEn "BLN";
BA_ "PacketOrder" SG_ 2155913216 PFAS_PFASndGenEn 1;
BA_ "SignalLongName" SG_ 2155913216 PFAS_PFASndGenEn "Pedestrian Friendly Alert Status : Pedestrian Friendly Alert Sound Generation Enable";
BA_ "VNSigAllNodes" SG_ 2155913216 PFAS_PFASndGenEn 1;
BA_ "SignalType" SG_ 2155913216 PFAS_PFARevSnd "ENM";
BA_ "PacketOrder" SG_ 2155913216 PFAS_PFARevSnd 3;
BA_ "SignalLongName" SG_ 2155913216 PFAS_PFARevSnd "Pedestrian Friendly Alert Status : Pedestrian Friendly Alert Reverse Sound";
BA_ "VNSigAllNodes" SG_ 2155913216 PFAS_PFARevSnd 1;
BA_ "SignalType" SG_ 2155913216 PFAS_PFAFwdSnd "ENM";
BA_ "PacketOrder" SG_ 2155913216 PFAS_PFAFwdSnd 2;
BA_ "SignalLongName" SG_ 2155913216 PFAS_PFAFwdSnd "Pedestrian Friendly Alert Status : Pedestrian Friendly Alert Forward Sound";
BA_ "VNSigAllNodes" SG_ 2155913216 PFAS_PFAFwdSnd 1;
BA_ "SignalType" SG_ 2155913216 PFAS_PFACrsOvrSpd "UNM";
BA_ "PacketOrder" SG_ 2155913216 PFAS_PFACrsOvrSpd 4;
BA_ "SignalLongName" SG_ 2155913216 PFAS_PFACrsOvrSpd "Pedestrian Friendly Alert Status : Pedestrian Friendly Alert Crossover Speed";
BA_ "VNSigAllNodes" SG_ 2155913216 PFAS_PFACrsOvrSpd 1;
BA_ "SignalType" SG_ 2155913216 PedFrndlyAlrtCsSetAvl "BLN";
BA_ "SignalLongName" SG_ 2155913216 PedFrndlyAlrtCsSetAvl "Pedestrian Friendly Alert Customization Setting Available";
BA_ "VNSigAllNodes" SG_ 2155913216 PedFrndlyAlrtCsSetAvl 1;
BA_ "SignalType" SG_ 2155913216 PedFrndlyAlrtCsCrStVal "ENM";
BA_ "SignalLongName" SG_ 2155913216 PedFrndlyAlrtCsCrStVal "Pedestrian Friendly Alert Customization Current Setting Value";
BA_ "VNSigAllNodes" SG_ 2155913216 PedFrndlyAlrtCsCrStVal 1;
BA_ "SignalType" SG_ 2155913216 DslExhFldRmngDstHRs "UNM";
BA_ "SignalLongName" SG_ 2155913216 DslExhFldRmngDstHRs "Diesel Exhaust Fluid Remaining Distance High Resolution";
BA_ "VNSigAllNodes" SG_ 2155913216 DslExhFldRmngDstHRs 1;
BA_ "SignalType" SG_ 2155913216 DslExhFldRmngDstHRsV "ENM";
BA_ "SignalLongName" SG_ 2155913216 DslExhFldRmngDstHRsV "Diesel Exhaust Fluid Remaining Distance High Resolution Validity";
BA_ "VNSigAllNodes" SG_ 2155913216 DslExhFldRmngDstHRsV 1;
BA_ "SignalType" SG_ 2034 DgnInf "UNM";
BA_ "SignalLongName" SG_ 2034 DgnInf "Diagnostic Information";
BA_ "VNSigDiagnostic" SG_ 2034 DgnInf 1;
BA_ "VNSigAllNodes" SG_ 2034 DgnInf 1;
BA_ "SignalType" SG_ 2032 DgnInf "UNM";
BA_ "SignalLongName" SG_ 2032 DgnInf "Diagnostic Information";
BA_ "VNSigDiagnostic" SG_ 2032 DgnInf 1;
BA_ "VNSigAllNodes" SG_ 2032 DgnInf 1;
BA_ "SignalType" SG_ 2150236160 AutoVehMdChecksum "UNM";
BA_ "SignalLongName" SG_ 2150236160 AutoVehMdChecksum "Autonomous Vehicle Mode Checksum";
BA_ "VNSigAllNodes" SG_ 2150236160 AutoVehMdChecksum 1;
BA_ "SignalType" SG_ 2150236160 AutoVehMdARC "UNM";
BA_ "SignalLongName" SG_ 2150236160 AutoVehMdARC "Autonomous Vehicle Mode Alive Rolling Count";
BA_ "VNSigAllNodes" SG_ 2150236160 AutoVehMdARC 1;
BA_ "SignalType" SG_ 2150236160 AutoVehMd "ENM";
BA_ "SignalLongName" SG_ 2150236160 AutoVehMd "Autonomous Vehicle Mode";
BA_ "VNSigAllNodes" SG_ 2150236160 AutoVehMd 1;
BA_ "VNSigInfotainment" SG_ 2159157248 ODI_CntrStck2TEL 1;
BA_ "SignalType" SG_ 2159157248 ODI_CntrStck2TEL "UNM";
BA_ "SignalLongName" SG_ 2159157248 ODI_CntrStck2TEL "Open Display Interface CenterStack 2 TEL";
BA_ "VNSigAllNodes" SG_ 2159157248 ODI_CntrStck2TEL 1;
BA_ "VNSigInfotainment" SG_ 2158927872 ODDC_InvldData 1;
BA_ "SignalType" SG_ 2158927872 ODDC_InvldData "BLN";
BA_ "PacketOrder" SG_ 2158927872 ODDC_InvldData 2;
BA_ "SignalLongName" SG_ 2158927872 ODDC_InvldData "Open Display Interface Dynamic Data Centerstack : Invalid Data";
BA_ "VNSigAllNodes" SG_ 2158927872 ODDC_InvldData 1;
BA_ "VNSigInfotainment" SG_ 2158927872 ODDC_FUCID 1;
BA_ "SignalType" SG_ 2158927872 ODDC_FUCID "UNM";
BA_ "PacketOrder" SG_ 2158927872 ODDC_FUCID 3;
BA_ "SignalLongName" SG_ 2158927872 ODDC_FUCID "Open Display Interface Dynamic Data Centerstack : Functional Unit Class ID";
BA_ "VNSigAllNodes" SG_ 2158927872 ODDC_FUCID 1;
BA_ "VNSigInfotainment" SG_ 2158927872 ODDC_DataVal 1;
BA_ "SignalType" SG_ 2158927872 ODDC_DataVal "UNM";
BA_ "PacketOrder" SG_ 2158927872 ODDC_DataVal 5;
BA_ "SignalLongName" SG_ 2158927872 ODDC_DataVal "Open Display Interface Dynamic Data Centerstack : Data Value";
BA_ "VNSigAllNodes" SG_ 2158927872 ODDC_DataVal 1;
BA_ "VNSigInfotainment" SG_ 2158927872 ODDC_DataType 1;
BA_ "SignalType" SG_ 2158927872 ODDC_DataType "ENM";
BA_ "PacketOrder" SG_ 2158927872 ODDC_DataType 1;
BA_ "SignalLongName" SG_ 2158927872 ODDC_DataType "Open Display Interface Dynamic Data Centerstack : Data Type";
BA_ "VNSigAllNodes" SG_ 2158927872 ODDC_DataType 1;
BA_ "VNSigInfotainment" SG_ 2158927872 ODDC_DataId 1;
BA_ "SignalType" SG_ 2158927872 ODDC_DataId "UNM";
BA_ "PacketOrder" SG_ 2158927872 ODDC_DataId 4;
BA_ "SignalLongName" SG_ 2158927872 ODDC_DataId "Open Display Interface Dynamic Data Centerstack : Data ID";
BA_ "VNSigAllNodes" SG_ 2158927872 ODDC_DataId 1;
BA_ "GenSigSendType" SG_ 2151702528 LnMrkngIndRgt 10;
BA_ "SignalType" SG_ 2151702528 LnMrkngIndRgt "ENM";
BA_ "SignalLongName" SG_ 2151702528 LnMrkngIndRgt "Lane Marking Indication Right";
BA_ "VNSigAllNodes" SG_ 2151702528 LnMrkngIndRgt 1;
BA_ "GenSigSendType" SG_ 2151702528 LnMrkngIndLft 10;
BA_ "SignalType" SG_ 2151702528 LnMrkngIndLft "ENM";
BA_ "SignalLongName" SG_ 2151702528 LnMrkngIndLft "Lane Marking Indication Left";
BA_ "VNSigAllNodes" SG_ 2151702528 LnMrkngIndLft 1;
BA_ "GenSigSendType" SG_ 2151702528 LnKepAsstStIndRgt 10;
BA_ "SignalType" SG_ 2151702528 LnKepAsstStIndRgt "ENM";
BA_ "SignalLongName" SG_ 2151702528 LnKepAsstStIndRgt "Lane Keeping Assist State Indication Right";
BA_ "VNSigAllNodes" SG_ 2151702528 LnKepAsstStIndRgt 1;
BA_ "GenSigSendType" SG_ 2151702528 LnKepAsstStIndLft 10;
BA_ "SignalType" SG_ 2151702528 LnKepAsstStIndLft "ENM";
BA_ "SignalLongName" SG_ 2151702528 LnKepAsstStIndLft "Lane Keeping Assist State Indication Left";
BA_ "VNSigAllNodes" SG_ 2151702528 LnKepAsstStIndLft 1;
BA_ "GenSigSendType" SG_ 2151702528 LnKpngAstRecfblIndRq 10;
BA_ "SignalType" SG_ 2151702528 LnKpngAstRecfblIndRq "ENM";
BA_ "SignalLongName" SG_ 2151702528 LnKpngAstRecfblIndRq "Lane Keeping Assist Reconfigurable Icon Indication Request";
BA_ "VNSigAllNodes" SG_ 2151702528 LnKpngAstRecfblIndRq 1;
BA_ "GenSigSendType" SG_ 2155970560 ClmCntLdShdLvlRq 10;
BA_ "SignalType" SG_ 2155970560 ClmCntLdShdLvlRq "ENM";
BA_ "SignalLongName" SG_ 2155970560 ClmCntLdShdLvlRq "Climate Control Load Shedding Level Request";
BA_ "VNSigAllNodes" SG_ 2155970560 ClmCntLdShdLvlRq 1;
BA_ "GenSigSendType" SG_ 2155970560 ClmCntBatSaverIO 10;
BA_ "SignalType" SG_ 2155970560 ClmCntBatSaverIO "BLN";
BA_ "SignalLongName" SG_ 2155970560 ClmCntBatSaverIO "Climate Control Battery Saver Indication On";
BA_ "VNSigAllNodes" SG_ 2155970560 ClmCntBatSaverIO 1;
BA_ "GenSigSendType" SG_ 2151178240 AFLGPSCstStReq 10;
BA_ "SignalType" SG_ 2151178240 AFLGPSCstStReq "ENM";
BA_ "SignalLongName" SG_ 2151178240 AFLGPSCstStReq "Adaptive Forward Lighting With GPS Customization Setting Request";
BA_ "VNSigAllNodes" SG_ 2151178240 AFLGPSCstStReq 1;
BA_ "GenSigSendType" SG_ 2151178240 AFLCstStReq 10;
BA_ "SignalType" SG_ 2151178240 AFLCstStReq "ENM";
BA_ "SignalLongName" SG_ 2151178240 AFLCstStReq "Adaptive Forward Lighting Customization Setting Request";
BA_ "VNSigAllNodes" SG_ 2151178240 AFLCstStReq 1;
BA_ "GenSigSendType" SG_ 2151178240 LtRtHnTrCstStReq 10;
BA_ "SignalType" SG_ 2151178240 LtRtHnTrCstStReq "ENM";
BA_ "SignalLongName" SG_ 2151178240 LtRtHnTrCstStReq "Left Right Hand Traffic Customization Setting Request";
BA_ "VNSigAllNodes" SG_ 2151178240 LtRtHnTrCstStReq 1;
BA_ "GenSigSendType" SG_ 2151178240 AdpHgBmAsSnCsStRq 10;
BA_ "SignalType" SG_ 2151178240 AdpHgBmAsSnCsStRq "ENM";
BA_ "SignalLongName" SG_ 2151178240 AdpHgBmAsSnCsStRq "Adaptive High Beam Assist With Sensitivity Customization Setting Request";
BA_ "VNSigAllNodes" SG_ 2151178240 AdpHgBmAsSnCsStRq 1;
BA_ "GenSigSendType" SG_ 2151178240 AdpHgBmAstCstStRq 10;
BA_ "SignalType" SG_ 2151178240 AdpHgBmAstCstStRq "ENM";
BA_ "SignalLongName" SG_ 2151178240 AdpHgBmAstCstStRq "Adaptive High Beam Assist Customization Setting Request";
BA_ "VNSigAllNodes" SG_ 2151178240 AdpHgBmAstCstStRq 1;
BA_ "GenSigSendType" SG_ 2151178240 LtRtHnTrGPSCstStRq 10;
BA_ "SignalType" SG_ 2151178240 LtRtHnTrGPSCstStRq "ENM";
BA_ "SignalLongName" SG_ 2151178240 LtRtHnTrGPSCstStRq "Left Right Hand Traffic With GPS Customization Setting Request";
BA_ "VNSigAllNodes" SG_ 2151178240 LtRtHnTrGPSCstStRq 1;
BA_ "GenSigSendType" SG_ 2151178240 AutHgBmAsSnCsStRq 10;
BA_ "SignalType" SG_ 2151178240 AutHgBmAsSnCsStRq "ENM";
BA_ "SignalLongName" SG_ 2151178240 AutHgBmAsSnCsStRq "Auto High Beam Assist With Sensitivity Customization Setting Request";
BA_ "VNSigAllNodes" SG_ 2151178240 AutHgBmAsSnCsStRq 1;
BA_ "GenSigSendType" SG_ 2151178240 AutHgBmAstCstStRq 10;
BA_ "SignalType" SG_ 2151178240 AutHgBmAstCstStRq "ENM";
BA_ "SignalLongName" SG_ 2151178240 AutHgBmAstCstStRq "Auto High Beam Assist Customization Setting Request";
BA_ "VNSigAllNodes" SG_ 2151178240 AutHgBmAstCstStRq 1;
BA_ "GenSigSendType" SG_ 2152013824 SmrtHgBmAstCstSetAvail 10;
BA_ "GenSigSendOnInit" SG_ 2152013824 SmrtHgBmAstCstSetAvail 2;
BA_ "SignalType" SG_ 2152013824 SmrtHgBmAstCstSetAvail "BLN";
BA_ "SignalLongName" SG_ 2152013824 SmrtHgBmAstCstSetAvail "Smart High Beam Assist Customization Setting Available";
BA_ "VNSigAllNodes" SG_ 2152013824 SmrtHgBmAstCstSetAvail 1;
BA_ "GenSigSendType" SG_ 2152013824 SmrtHgBmAstCstCurrSetVal 10;
BA_ "GenSigSendOnInit" SG_ 2152013824 SmrtHgBmAstCstCurrSetVal 2;
BA_ "SignalType" SG_ 2152013824 SmrtHgBmAstCstCurrSetVal "ENM";
BA_ "SignalLongName" SG_ 2152013824 SmrtHgBmAstCstCurrSetVal "Smart High Beam Assist Customization Current Setting Value";
BA_ "VNSigAllNodes" SG_ 2152013824 SmrtHgBmAstCstCurrSetVal 1;
BA_ "GenSigSendType" SG_ 2155536384 RevClnMtgnBrkReqAct 10;
BA_ "SignalType" SG_ 2155536384 RevClnMtgnBrkReqAct "BLN";
BA_ "SignalLongName" SG_ 2155536384 RevClnMtgnBrkReqAct "Reverse Collision Mitigation Braking Request Active";
BA_ "VNSigAllNodes" SG_ 2155536384 RevClnMtgnBrkReqAct 1;
BA_ "GenSigSendType" SG_ 2155536384 TnDrvRIMOffUnbIO 10;
BA_ "SignalType" SG_ 2155536384 TnDrvRIMOffUnbIO "BLN";
BA_ "SignalLongName" SG_ 2155536384 TnDrvRIMOffUnbIO "Teen Driver Reverse Impact Mitigation Off Unavailable Indication On";
BA_ "VNSigAllNodes" SG_ 2155536384 TnDrvRIMOffUnbIO 1;
BA_ "GenSigSendType" SG_ 2155536384 RVBUnblIO 10;
BA_ "GenSigSendOnInit" SG_ 2155536384 RVBUnblIO 2;
BA_ "SignalType" SG_ 2155536384 RVBUnblIO "BLN";
BA_ "SignalLongName" SG_ 2155536384 RVBUnblIO "Rear Virtual Bumper Unavailable Indication On";
BA_ "VNSigAllNodes" SG_ 2155536384 RVBUnblIO 1;
BA_ "GenSigSendType" SG_ 2155536384 RVBFldIO 10;
BA_ "SignalType" SG_ 2155536384 RVBFldIO "BLN";
BA_ "SignalLongName" SG_ 2155536384 RVBFldIO "Rear Virtual Bumper Failed Indication On";
BA_ "VNSigAllNodes" SG_ 2155536384 RVBFldIO 1;
BA_ "GenSigSendType" SG_ 2155536384 RVBEnbldIO 10;
BA_ "SignalType" SG_ 2155536384 RVBEnbldIO "BLN";
BA_ "SignalLongName" SG_ 2155536384 RVBEnbldIO "Rear Virtual Bumper Enabled Indication On";
BA_ "VNSigAllNodes" SG_ 2155536384 RVBEnbldIO 1;
BA_ "GenSigSendType" SG_ 2155536384 RVBDsbldIO 10;
BA_ "SignalType" SG_ 2155536384 RVBDsbldIO "BLN";
BA_ "SignalLongName" SG_ 2155536384 RVBDsbldIO "Rear Virtual Bumper Disabled Indication On";
BA_ "VNSigAllNodes" SG_ 2155536384 RVBDsbldIO 1;
BA_ "GenSigSendType" SG_ 2152742912 ShrtRngRdrOffIO 10;
BA_ "SignalType" SG_ 2152742912 ShrtRngRdrOffIO "BLN";
BA_ "SignalLongName" SG_ 2152742912 ShrtRngRdrOffIO "Short Range Radar Off Indication On";
BA_ "VNSigAllNodes" SG_ 2152742912 ShrtRngRdrOffIO 1;
BA_ "GenSigSendType" SG_ 2152742912 RrRdrFldIO 10;
BA_ "SignalType" SG_ 2152742912 RrRdrFldIO "BLN";
BA_ "SignalLongName" SG_ 2152742912 RrRdrFldIO "Rear Radar Failed Indication On";
BA_ "VNSigAllNodes" SG_ 2152742912 RrRdrFldIO 1;
BA_ "GenSigSendType" SG_ 2152742912 RrRdrBlckdIO 10;
BA_ "GenSigSendOnInit" SG_ 2152742912 RrRdrBlckdIO 2;
BA_ "SignalType" SG_ 2152742912 RrRdrBlckdIO "BLN";
BA_ "SignalLongName" SG_ 2152742912 RrRdrBlckdIO "Rear Radar Blocked Indication On";
BA_ "VNSigAllNodes" SG_ 2152742912 RrRdrBlckdIO 1;
BA_ "GenSigSendType" SG_ 2152742912 RrEOCMMdlFldIO 10;
BA_ "SignalType" SG_ 2152742912 RrEOCMMdlFldIO "BLN";
BA_ "SignalLongName" SG_ 2152742912 RrEOCMMdlFldIO "Rear External Object Calculating Module Failed Indication On";
BA_ "VNSigAllNodes" SG_ 2152742912 RrEOCMMdlFldIO 1;
BA_ "GenSigSendType" SG_ 2151481344 HdUpDsplyUnblIO 10;
BA_ "SignalType" SG_ 2151481344 HdUpDsplyUnblIO "BLN";
BA_ "SignalLongName" SG_ 2151481344 HdUpDsplyUnblIO "Head Up Display Unavailable Indication On";
BA_ "VNSigAllNodes" SG_ 2151481344 HdUpDsplyUnblIO 1;
BA_ "GenSigSendType" SG_ 2151481344 FSRACCFrstRsmPrssIO 10;
BA_ "SignalType" SG_ 2151481344 FSRACCFrstRsmPrssIO "BLN";
BA_ "SignalLongName" SG_ 2151481344 FSRACCFrstRsmPrssIO "Full Speed Range Adaptive Cruise Control First Resume Press Indication On";
BA_ "VNSigAllNodes" SG_ 2151481344 FSRACCFrstRsmPrssIO 1;
BA_ "GenSigSendType" SG_ 2151481344 FrtRdrBlckdIO 10;
BA_ "SignalType" SG_ 2151481344 FrtRdrBlckdIO "BLN";
BA_ "SignalLongName" SG_ 2151481344 FrtRdrBlckdIO "Front Radar Blocked Indication On";
BA_ "VNSigAllNodes" SG_ 2151481344 FrtRdrBlckdIO 1;
BA_ "GenSigSendType" SG_ 2151481344 ShtToPrkBfExtngVehIO 10;
BA_ "SignalType" SG_ 2151481344 ShtToPrkBfExtngVehIO "BLN";
BA_ "SignalLongName" SG_ 2151481344 ShtToPrkBfExtngVehIO "Shift to Park Before Exiting Vehicle Indication On";
BA_ "VNSigAllNodes" SG_ 2151481344 ShtToPrkBfExtngVehIO 1;
BA_ "GenSigSendType" SG_ 2151481344 AutoBrkRlsIO 10;
BA_ "SignalType" SG_ 2151481344 AutoBrkRlsIO "BLN";
BA_ "SignalLongName" SG_ 2151481344 AutoBrkRlsIO "Autonomous Brake Release Indication On";
BA_ "VNSigAllNodes" SG_ 2151481344 AutoBrkRlsIO 1;
BA_ "GenSigSendType" SG_ 2149957632 PrkAstRrObjSnsngRqAct 10;
BA_ "GenSigSendOnInit" SG_ 2149957632 PrkAstRrObjSnsngRqAct 2;
BA_ "SignalType" SG_ 2149957632 PrkAstRrObjSnsngRqAct "BLN";
BA_ "SignalLongName" SG_ 2149957632 PrkAstRrObjSnsngRqAct "Park Assistance Rear Object Sensing Request Active";
BA_ "VNSigAllNodes" SG_ 2149957632 PrkAstRrObjSnsngRqAct 1;
BA_ "GenSigSendType" SG_ 2149957632 PrkAstOprtrDsrdStat 10;
BA_ "GenSigSendOnInit" SG_ 2149957632 PrkAstOprtrDsrdStat 2;
BA_ "SignalType" SG_ 2149957632 PrkAstOprtrDsrdStat "ENM";
BA_ "SignalLongName" SG_ 2149957632 PrkAstOprtrDsrdStat "Park Assistance Operator Desired Status";
BA_ "VNSigAllNodes" SG_ 2149957632 PrkAstOprtrDsrdStat 1;
BA_ "GenSigSendType" SG_ 2149957632 PrkAstInhbtReq 10;
BA_ "GenSigSendOnInit" SG_ 2149957632 PrkAstInhbtReq 2;
BA_ "SignalType" SG_ 2149957632 PrkAstInhbtReq "BLN";
BA_ "SignalLongName" SG_ 2149957632 PrkAstInhbtReq "Park Assistance Inhibit Request";
BA_ "VNSigAllNodes" SG_ 2149957632 PrkAstInhbtReq 1;
BA_ "GenSigSendType" SG_ 2149957632 ClsnMtgtnInhbtd 10;
BA_ "GenSigSendOnInit" SG_ 2149957632 ClsnMtgtnInhbtd 2;
BA_ "SignalType" SG_ 2149957632 ClsnMtgtnInhbtd "BLN";
BA_ "SignalLongName" SG_ 2149957632 ClsnMtgtnInhbtd "Collision Mitigation Inhibited";
BA_ "VNSigAllNodes" SG_ 2149957632 ClsnMtgtnInhbtd 1;
BA_ "GenSigDeltaValue" SG_ 2153889792 LCArrwBlk5Offst 1;
BA_ "GenSigSendType" SG_ 2153889792 LCArrwBlk5Offst 12;
BA_ "GenSigSendOnInit" SG_ 2153889792 LCArrwBlk5Offst 2;
BA_ "SignalType" SG_ 2153889792 LCArrwBlk5Offst "SNM";
BA_ "SignalLongName" SG_ 2153889792 LCArrwBlk5Offst "Lane Centering Arrow Block 5 Offset";
BA_ "VNSigAllNodes" SG_ 2153889792 LCArrwBlk5Offst 1;
BA_ "GenSigSendType" SG_ 2153889792 LCArrwBlk5Act 10;
BA_ "GenSigSendOnInit" SG_ 2153889792 LCArrwBlk5Act 2;
BA_ "SignalType" SG_ 2153889792 LCArrwBlk5Act "BLN";
BA_ "SignalLongName" SG_ 2153889792 LCArrwBlk5Act "Lane Centering Arrow Block 5 Active";
BA_ "VNSigAllNodes" SG_ 2153889792 LCArrwBlk5Act 1;
BA_ "GenSigDeltaValue" SG_ 2153889792 LCArrwBlk4Offst 1;
BA_ "GenSigSendType" SG_ 2153889792 LCArrwBlk4Offst 12;
BA_ "GenSigSendOnInit" SG_ 2153889792 LCArrwBlk4Offst 2;
BA_ "SignalType" SG_ 2153889792 LCArrwBlk4Offst "SNM";
BA_ "SignalLongName" SG_ 2153889792 LCArrwBlk4Offst "Lane Centering Arrow Block 4 Offset";
BA_ "VNSigAllNodes" SG_ 2153889792 LCArrwBlk4Offst 1;
BA_ "GenSigSendType" SG_ 2153889792 LCArrwBlk4Act 10;
BA_ "GenSigSendOnInit" SG_ 2153889792 LCArrwBlk4Act 2;
BA_ "SignalType" SG_ 2153889792 LCArrwBlk4Act "BLN";
BA_ "SignalLongName" SG_ 2153889792 LCArrwBlk4Act "Lane Centering Arrow Block 4 Active";
BA_ "VNSigAllNodes" SG_ 2153889792 LCArrwBlk4Act 1;
BA_ "GenSigDeltaValue" SG_ 2153889792 LCArrwBlk3Offst 1;
BA_ "GenSigSendType" SG_ 2153889792 LCArrwBlk3Offst 12;
BA_ "GenSigSendOnInit" SG_ 2153889792 LCArrwBlk3Offst 2;
BA_ "SignalType" SG_ 2153889792 LCArrwBlk3Offst "SNM";
BA_ "SignalLongName" SG_ 2153889792 LCArrwBlk3Offst "Lane Centering Arrow Block 3 Offset";
BA_ "VNSigAllNodes" SG_ 2153889792 LCArrwBlk3Offst 1;
BA_ "GenSigSendType" SG_ 2153889792 LCArrwBlk3Act 10;
BA_ "GenSigSendOnInit" SG_ 2153889792 LCArrwBlk3Act 2;
BA_ "SignalType" SG_ 2153889792 LCArrwBlk3Act "BLN";
BA_ "SignalLongName" SG_ 2153889792 LCArrwBlk3Act "Lane Centering Arrow Block 3 Active";
BA_ "VNSigAllNodes" SG_ 2153889792 LCArrwBlk3Act 1;
BA_ "GenSigDeltaValue" SG_ 2153889792 LCArrwBlk2Offst 1;
BA_ "GenSigSendType" SG_ 2153889792 LCArrwBlk2Offst 12;
BA_ "GenSigSendOnInit" SG_ 2153889792 LCArrwBlk2Offst 2;
BA_ "SignalType" SG_ 2153889792 LCArrwBlk2Offst "SNM";
BA_ "SignalLongName" SG_ 2153889792 LCArrwBlk2Offst "Lane Centering Arrow Block 2 Offset";
BA_ "VNSigAllNodes" SG_ 2153889792 LCArrwBlk2Offst 1;
BA_ "GenSigSendType" SG_ 2153889792 LCArrwBlk2Act 10;
BA_ "GenSigSendOnInit" SG_ 2153889792 LCArrwBlk2Act 2;
BA_ "SignalType" SG_ 2153889792 LCArrwBlk2Act "BLN";
BA_ "SignalLongName" SG_ 2153889792 LCArrwBlk2Act "Lane Centering Arrow Block 2 Active";
BA_ "VNSigAllNodes" SG_ 2153889792 LCArrwBlk2Act 1;
BA_ "GenSigSendType" SG_ 2153889792 LCArrwBlk1Act 10;
BA_ "GenSigSendOnInit" SG_ 2153889792 LCArrwBlk1Act 2;
BA_ "SignalType" SG_ 2153889792 LCArrwBlk1Act "BLN";
BA_ "SignalLongName" SG_ 2153889792 LCArrwBlk1Act "Lane Centering Arrow Block 1 Active";
BA_ "VNSigAllNodes" SG_ 2153889792 LCArrwBlk1Act 1;
BA_ "GenSigSendType" SG_ 2153930752 LnCntrVhlStpd 10;
BA_ "GenSigSendOnInit" SG_ 2153930752 LnCntrVhlStpd 2;
BA_ "SignalType" SG_ 2153930752 LnCntrVhlStpd "BLN";
BA_ "SignalLongName" SG_ 2153930752 LnCntrVhlStpd "Lane Centering Vehicle Stopped";
BA_ "VNSigAllNodes" SG_ 2153930752 LnCntrVhlStpd 1;
BA_ "GenSigSendType" SG_ 2153930752 LnCntrSpchPrmtReq 10;
BA_ "GenSigSendOnInit" SG_ 2153930752 LnCntrSpchPrmtReq 2;
BA_ "SignalType" SG_ 2153930752 LnCntrSpchPrmtReq "ENM";
BA_ "SignalLongName" SG_ 2153930752 LnCntrSpchPrmtReq "Lane Centering Speech Prompt Request";
BA_ "VNSigAllNodes" SG_ 2153930752 LnCntrSpchPrmtReq 1;
BA_ "GenSigSendType" SG_ 2153930752 LCWrnIndReq 10;
BA_ "SignalType" SG_ 2153930752 LCWrnIndReq "ENM";
BA_ "SignalLongName" SG_ 2153930752 LCWrnIndReq "Lane Centering Warning Indication Request";
BA_ "VNSigAllNodes" SG_ 2153930752 LCWrnIndReq 1;
BA_ "GenSigSendType" SG_ 2153930752 LCCDrvrAwrnsIO 10;
BA_ "SignalType" SG_ 2153930752 LCCDrvrAwrnsIO "BLN";
BA_ "SignalLongName" SG_ 2153930752 LCCDrvrAwrnsIO "Lane Centering Driver Awareness Indication On";
BA_ "VNSigAllNodes" SG_ 2153930752 LCCDrvrAwrnsIO 1;
BA_ "GenSigSendType" SG_ 2153930752 LCConvMsgIndreq 10;
BA_ "SignalType" SG_ 2153930752 LCConvMsgIndreq "ENM";
BA_ "SignalLongName" SG_ 2153930752 LCConvMsgIndreq "Lane Centering Convenience Message Indication Request";
BA_ "VNSigAllNodes" SG_ 2153930752 LCConvMsgIndreq 1;
BA_ "GenSigSendType" SG_ 2153930752 LCCIndReq 10;
BA_ "SignalType" SG_ 2153930752 LCCIndReq "ENM";
BA_ "SignalLongName" SG_ 2153930752 LCCIndReq "Lane Centering Control Indication Request";
BA_ "VNSigAllNodes" SG_ 2153930752 LCCIndReq 1;
BA_ "GenSigSendType" SG_ 2153930752 LnCntrNonRspDrvrCnd 10;
BA_ "GenSigSendOnInit" SG_ 2153930752 LnCntrNonRspDrvrCnd 2;
BA_ "SignalType" SG_ 2153930752 LnCntrNonRspDrvrCnd "BLN";
BA_ "SignalLongName" SG_ 2153930752 LnCntrNonRspDrvrCnd "Lane Centering Non Responsive Driver Condition";
BA_ "VNSigAllNodes" SG_ 2153930752 LnCntrNonRspDrvrCnd 1;
BA_ "GenSigDeltaValue" SG_ 2153930752 LnCntrngCtlIcnLoctn 1;
BA_ "GenSigSendType" SG_ 2153930752 LnCntrngCtlIcnLoctn 12;
BA_ "SignalType" SG_ 2153930752 LnCntrngCtlIcnLoctn "SNM";
BA_ "SignalLongName" SG_ 2153930752 LnCntrngCtlIcnLoctn "Lane Centering Control Icon Location";
BA_ "VNSigAllNodes" SG_ 2153930752 LnCntrngCtlIcnLoctn 1;
BA_ "GenSigSendType" SG_ 2153930752 LnCntrEsclnStat 10;
BA_ "GenSigSendOnInit" SG_ 2153930752 LnCntrEsclnStat 2;
BA_ "SignalType" SG_ 2153930752 LnCntrEsclnStat "ENM";
BA_ "SignalLongName" SG_ 2153930752 LnCntrEsclnStat "Lane Centering Escalation Status";
BA_ "VNSigAllNodes" SG_ 2153930752 LnCntrEsclnStat 1;
BA_REL_ "GenSigSuprvResp" BU_SG_REL_ ECC_LS SG_ 2159132672 ODIAR_FUCID 1;
BA_REL_ "GenSigSuprvResp" BU_SG_REL_ ECC_LS SG_ 2159132672 ODIAR_DspMID 1;
BA_REL_ "GenSigSuprvResp" BU_SG_REL_ ECC_LS SG_ 2159132672 ODIAR_DaTy 1;
BA_REL_ "GenSigSuprvResp" BU_SG_REL_ ECC_LS SG_ 2159132672 ODIAR_ActnVal 1;
BA_REL_ "GenSigSuprvResp" BU_SG_REL_ ECC_LS SG_ 2159132672 ODIAR_ActnID 1;
BA_REL_ "GenSigRxStartValue" BU_SG_REL_ MCTM_LS SG_ 2158895104 ODI_CntrStck2RSD "0";
BA_REL_ "GenSigRxStartValue" BU_SG_REL_ MCTM_LS SG_ 2158960640 ODIIC_FUCID "0";
BA_REL_ "GenSigRxStartValue" BU_SG_REL_ MCTM_LS SG_ 2158960640 ODIIC_ODIInd9 "0";
BA_REL_ "GenSigRxStartValue" BU_SG_REL_ MCTM_LS SG_ 2158960640 ODIIC_ODIInd8 "0";
BA_REL_ "GenSigRxStartValue" BU_SG_REL_ MCTM_LS SG_ 2158960640 ODIIC_ODIInd7 "0";
BA_REL_ "GenSigRxStartValue" BU_SG_REL_ MCTM_LS SG_ 2158960640 ODIIC_ODIInd6 "0";
BA_REL_ "GenSigRxStartValue" BU_SG_REL_ MCTM_LS SG_ 2158960640 ODIIC_ODIInd56 "0";
BA_REL_ "GenSigRxStartValue" BU_SG_REL_ MCTM_LS SG_ 2158960640 ODIIC_ODIInd55 "0";
BA_REL_ "GenSigRxStartValue" BU_SG_REL_ MCTM_LS SG_ 2158960640 ODIIC_ODIInd54 "0";
BA_REL_ "GenSigRxStartValue" BU_SG_REL_ MCTM_LS SG_ 2158960640 ODIIC_ODIInd53 "0";
BA_REL_ "GenSigRxStartValue" BU_SG_REL_ MCTM_LS SG_ 2158960640 ODIIC_ODIInd52 "0";
BA_REL_ "GenSigRxStartValue" BU_SG_REL_ MCTM_LS SG_ 2158960640 ODIIC_ODIInd51 "0";
BA_REL_ "GenSigRxStartValue" BU_SG_REL_ MCTM_LS SG_ 2158960640 ODIIC_ODIInd50 "0";
BA_REL_ "GenSigRxStartValue" BU_SG_REL_ MCTM_LS SG_ 2158960640 ODIIC_ODIInd5 "0";
BA_REL_ "GenSigRxStartValue" BU_SG_REL_ MCTM_LS SG_ 2158960640 ODIIC_ODIInd49 "0";
BA_REL_ "GenSigRxStartValue" BU_SG_REL_ MCTM_LS SG_ 2158960640 ODIIC_ODIInd48 "0";
BA_REL_ "GenSigRxStartValue" BU_SG_REL_ MCTM_LS SG_ 2158960640 ODIIC_ODIInd47 "0";
BA_REL_ "GenSigRxStartValue" BU_SG_REL_ MCTM_LS SG_ 2158960640 ODIIC_ODIInd46 "0";
BA_REL_ "GenSigRxStartValue" BU_SG_REL_ MCTM_LS SG_ 2158960640 ODIIC_ODIInd45 "0";
BA_REL_ "GenSigRxStartValue" BU_SG_REL_ MCTM_LS SG_ 2158960640 ODIIC_ODIInd44 "0";
BA_REL_ "GenSigRxStartValue" BU_SG_REL_ MCTM_LS SG_ 2158960640 ODIIC_ODIInd43 "0";
BA_REL_ "GenSigRxStartValue" BU_SG_REL_ MCTM_LS SG_ 2158960640 ODIIC_ODIInd42 "0";
BA_REL_ "GenSigRxStartValue" BU_SG_REL_ MCTM_LS SG_ 2158960640 ODIIC_ODIInd41 "0";
BA_REL_ "GenSigRxStartValue" BU_SG_REL_ MCTM_LS SG_ 2158960640 ODIIC_ODIInd40 "0";
BA_REL_ "GenSigRxStartValue" BU_SG_REL_ MCTM_LS SG_ 2158960640 ODIIC_ODIInd4 "0";
BA_REL_ "GenSigRxStartValue" BU_SG_REL_ MCTM_LS SG_ 2158960640 ODIIC_ODIInd39 "0";
BA_REL_ "GenSigRxStartValue" BU_SG_REL_ MCTM_LS SG_ 2158960640 ODIIC_ODIInd38 "0";
BA_REL_ "GenSigRxStartValue" BU_SG_REL_ MCTM_LS SG_ 2158960640 ODIIC_ODIInd37 "0";
BA_REL_ "GenSigRxStartValue" BU_SG_REL_ MCTM_LS SG_ 2158960640 ODIIC_ODIInd36 "0";
BA_REL_ "GenSigRxStartValue" BU_SG_REL_ MCTM_LS SG_ 2158960640 ODIIC_ODIInd35 "0";
BA_REL_ "GenSigRxStartValue" BU_SG_REL_ MCTM_LS SG_ 2158960640 ODIIC_ODIInd34 "0";
BA_REL_ "GenSigRxStartValue" BU_SG_REL_ MCTM_LS SG_ 2158960640 ODIIC_ODIInd33 "0";
BA_REL_ "GenSigRxStartValue" BU_SG_REL_ MCTM_LS SG_ 2158960640 ODIIC_ODIInd32 "0";
BA_REL_ "GenSigRxStartValue" BU_SG_REL_ MCTM_LS SG_ 2158960640 ODIIC_ODIInd31 "0";
BA_REL_ "GenSigRxStartValue" BU_SG_REL_ MCTM_LS SG_ 2158960640 ODIIC_ODIInd30 "0";
BA_REL_ "GenSigRxStartValue" BU_SG_REL_ MCTM_LS SG_ 2158960640 ODIIC_ODIInd3 "0";
BA_REL_ "GenSigRxStartValue" BU_SG_REL_ MCTM_LS SG_ 2158960640 ODIIC_ODIInd29 "0";
BA_REL_ "GenSigRxStartValue" BU_SG_REL_ MCTM_LS SG_ 2158960640 ODIIC_ODIInd28 "0";
BA_REL_ "GenSigRxStartValue" BU_SG_REL_ MCTM_LS SG_ 2158960640 ODIIC_ODIInd27 "0";
BA_REL_ "GenSigRxStartValue" BU_SG_REL_ MCTM_LS SG_ 2158960640 ODIIC_ODIInd26 "0";
BA_REL_ "GenSigRxStartValue" BU_SG_REL_ MCTM_LS SG_ 2158960640 ODIIC_ODIInd25 "0";
BA_REL_ "GenSigRxStartValue" BU_SG_REL_ MCTM_LS SG_ 2158960640 ODIIC_ODIInd24 "0";
BA_REL_ "GenSigRxStartValue" BU_SG_REL_ MCTM_LS SG_ 2158960640 ODIIC_ODIInd23 "0";
BA_REL_ "GenSigRxStartValue" BU_SG_REL_ MCTM_LS SG_ 2158960640 ODIIC_ODIInd22 "0";
BA_REL_ "GenSigRxStartValue" BU_SG_REL_ MCTM_LS SG_ 2158960640 ODIIC_ODIInd21 "0";
BA_REL_ "GenSigRxStartValue" BU_SG_REL_ MCTM_LS SG_ 2158960640 ODIIC_ODIInd20 "0";
BA_REL_ "GenSigRxStartValue" BU_SG_REL_ MCTM_LS SG_ 2158960640 ODIIC_ODIInd2 "0";
BA_REL_ "GenSigRxStartValue" BU_SG_REL_ MCTM_LS SG_ 2158960640 ODIIC_ODIInd19 "0";
BA_REL_ "GenSigRxStartValue" BU_SG_REL_ MCTM_LS SG_ 2158960640 ODIIC_ODIInd18 "0";
BA_REL_ "GenSigRxStartValue" BU_SG_REL_ MCTM_LS SG_ 2158960640 ODIIC_ODIInd17 "0";
BA_REL_ "GenSigRxStartValue" BU_SG_REL_ MCTM_LS SG_ 2158960640 ODIIC_ODIInd16 "0";
BA_REL_ "GenSigRxStartValue" BU_SG_REL_ MCTM_LS SG_ 2158960640 ODIIC_ODIInd15 "0";
BA_REL_ "GenSigRxStartValue" BU_SG_REL_ MCTM_LS SG_ 2158960640 ODIIC_ODIInd14 "0";
BA_REL_ "GenSigRxStartValue" BU_SG_REL_ MCTM_LS SG_ 2158960640 ODIIC_ODIInd13 "0";
BA_REL_ "GenSigRxStartValue" BU_SG_REL_ MCTM_LS SG_ 2158960640 ODIIC_ODIInd12 "0";
BA_REL_ "GenSigRxStartValue" BU_SG_REL_ MCTM_LS SG_ 2158960640 ODIIC_ODIInd11 "0";
BA_REL_ "GenSigRxStartValue" BU_SG_REL_ MCTM_LS SG_ 2158960640 ODIIC_ODIInd10 "0";
BA_REL_ "GenSigRxStartValue" BU_SG_REL_ MCTM_LS SG_ 2158960640 ODIIC_ODIInd1 "0";
BA_REL_ "GenSigRxStartValue" BU_SG_REL_ MCTM_LS SG_ 2158977024 ODIEC_MultiFrRetCh "0";
BA_REL_ "GenSigRxStartValue" BU_SG_REL_ MCTM_LS SG_ 2158977024 ODIEC_FUCID "0";
BA_REL_ "GenSigRxStartValue" BU_SG_REL_ MCTM_LS SG_ 2158977024 ODIEC_EvID "0";
BA_REL_ "GenSigRxStartValue" BU_SG_REL_ PEPS_LS SG_ 2154397696 CrShrngFbsEnblStat "No Action";
BA_REL_ "GenSigSuprvResp" BU_SG_REL_ ECC_LS SG_ 2154725376 AuxHtrAtv378 1;
BA_REL_ "GenSigSuprvResp" BU_SG_REL_ ECC_LS SG_ 2154725376 AuxHtrRq 1;
BA_REL_ "GenSigRxStartValue" BU_SG_REL_ DLM_LS SG_ 2155364352 CstmrUsblSOCV "Valid";
BA_REL_ "GenSigVBitResp" BU_SG_REL_ DLM_LS SG_ 2155364352 CstmrUsblSOC 1;
BA_REL_ "GenSigRxStartValue" BU_SG_REL_ DLM_LS SG_ 2155364352 CstmrUsblSOC "0";
BA_REL_ "GenSigSuprvResp" BU_SG_REL_ MCTM_LS SG_ 2150260736 AV_Drv_Sys_Ena_Red 1;
BA_REL_ "GenSigSuprvResp" BU_SG_REL_ MCTM_LS SG_ 2150260736 Rear_Etr_Swtch_Ena_Red 1;
BA_REL_ "GenSigRxStartValue" BU_SG_REL_ SCCM_2_LS SG_ 2150260736 AutoVehMdBkcupChcksm "0";
BA_REL_ "GenSigRxStartValue" BU_SG_REL_ SCCM_1_LS SG_ 2150260736 AutoVehMdBkcupChcksm "0";
BA_REL_ "GenSigRxStartValue" BU_SG_REL_ SCCM_2_LS SG_ 2150260736 AutoVehMdBckupARC "0";
BA_REL_ "GenSigRxStartValue" BU_SG_REL_ SCCM_1_LS SG_ 2150260736 AutoVehMdBckupARC "0";
BA_REL_ "GenSigSuprvResp" BU_SG_REL_ MCTM_LS SG_ 2150260736 AutoVehMdBckup 1;
BA_REL_ "GenSigRxStartValue" BU_SG_REL_ PEPS_LS SG_ 2150260736 AutoVehMdBckup "Unknown";
BA_REL_ "GenSigSuprvResp" BU_SG_REL_ PEPS_LS SG_ 2150260736 AutoVehMdBckup 1;
BA_REL_ "GenSigRxStartValue" BU_SG_REL_ SCCM_2_LS SG_ 2150260736 AutoVehMdBckup "Unknown";
BA_REL_ "GenSigRxStartValue" BU_SG_REL_ SCCM_1_LS SG_ 2150260736 AutoVehMdBckup "Unknown";
BA_REL_ "GenSigSuprvResp" BU_SG_REL_ BCM_LS SG_ 2150260736 AutoVehMdBckup 1;
BA_REL_ "GenSigTimeoutMsg" BU_SG_REL_ BCM_LS SG_ 2150260736 AutoVehMdBckup 339;
BA_REL_ "GenSigTimeoutTime" BU_SG_REL_ BCM_LS SG_ 2150260736 AutoVehMdBckup 250;
BA_REL_ "GenSigRxStartValue" BU_SG_REL_ SCCM_2_LS SG_ 2152562688 BSCWB_ZnEnbd "0";
BA_REL_ "GenSigSuprvResp" BU_SG_REL_ SCCM_2_LS SG_ 2152562688 BSCWB_ZnEnbd 1;
BA_REL_ "GenSigRxStartValue" BU_SG_REL_ SCCM_2_LS SG_ 2152562688 BSCWB_Zn8 "0";
BA_REL_ "GenSigSuprvResp" BU_SG_REL_ SCCM_2_LS SG_ 2152562688 BSCWB_Zn8 1;
BA_REL_ "GenSigRxStartValue" BU_SG_REL_ SCCM_2_LS SG_ 2152562688 BSCWB_Zn7 "0";
BA_REL_ "GenSigSuprvResp" BU_SG_REL_ SCCM_2_LS SG_ 2152562688 BSCWB_Zn7 1;
BA_REL_ "GenSigRxStartValue" BU_SG_REL_ SCCM_2_LS SG_ 2152562688 BSCWB_Zn3 "0";
BA_REL_ "GenSigSuprvResp" BU_SG_REL_ SCCM_2_LS SG_ 2152562688 BSCWB_Zn3 1;
BA_REL_ "GenSigRxStartValue" BU_SG_REL_ SCCM_2_LS SG_ 2152562688 BSCWB_Zn2 "0";
BA_REL_ "GenSigSuprvResp" BU_SG_REL_ SCCM_2_LS SG_ 2152562688 BSCWB_Zn2 1;
BA_REL_ "GenSigRxStartValue" BU_SG_REL_ SCCM_2_LS SG_ 2152562688 BSCAB_ZnEnbd "0";
BA_REL_ "GenSigSuprvResp" BU_SG_REL_ SCCM_2_LS SG_ 2152562688 BSCAB_ZnEnbd 1;
BA_REL_ "GenSigRxStartValue" BU_SG_REL_ SCCM_2_LS SG_ 2152562688 BSCAB_Zn8 "0";
BA_REL_ "GenSigSuprvResp" BU_SG_REL_ SCCM_2_LS SG_ 2152562688 BSCAB_Zn8 1;
BA_REL_ "GenSigRxStartValue" BU_SG_REL_ SCCM_2_LS SG_ 2152562688 BSCAB_Zn7 "0";
BA_REL_ "GenSigSuprvResp" BU_SG_REL_ SCCM_2_LS SG_ 2152562688 BSCAB_Zn7 1;
BA_REL_ "GenSigRxStartValue" BU_SG_REL_ SCCM_2_LS SG_ 2152562688 BSCAB_Zn3 "0";
BA_REL_ "GenSigSuprvResp" BU_SG_REL_ SCCM_2_LS SG_ 2152562688 BSCAB_Zn3 1;
BA_REL_ "GenSigRxStartValue" BU_SG_REL_ SCCM_2_LS SG_ 2152562688 BSCAB_Zn2 "0";
BA_REL_ "GenSigSuprvResp" BU_SG_REL_ SCCM_2_LS SG_ 2152562688 BSCAB_Zn2 1;
BA_REL_ "GenSigSuprvResp" BU_SG_REL_ BCM_LS SG_ 2153865216 TeenDrvReq 1;
BA_REL_ "GenSigSuprvResp" BU_SG_REL_ BCM_LS SG_ 2153865216 TeenDrvPinCd 1;
BA_REL_ "GenSigSuprvResp" BU_SG_REL_ BCM_LS SG_ 2153865216 TnDrvSpdLmtCstStReq 1;
BA_REL_ "GenSigSuprvResp" BU_SG_REL_ BCM_LS SG_ 2153865216 TDOWCSR_StatReq 1;
BA_REL_ "GenSigSuprvResp" BU_SG_REL_ BCM_LS SG_ 2153865216 TDOWCSR_IncSwAct 1;
BA_REL_ "GenSigSuprvResp" BU_SG_REL_ BCM_LS SG_ 2153865216 TDOWCSR_DecSwAct 1;
BA_REL_ "GenSigSuprvResp" BU_SG_REL_ UPA_LS SG_ 2153824256 TeenDrvAct 1;
BA_REL_ "GenSigSuprvResp" BU_SG_REL_ BCM_LS SG_ 2150391808 EngRunAtvTm 1;
BA_REL_ "GenSigSuprvResp" BU_SG_REL_ BCM_LS SG_ 2150391808 EngIdlAtvTm 1;
BA_REL_ "GenSigRxStartValue" BU_SG_REL_ SCCM_2_LS SG_ 2150236160 AutoVehMdChecksum "0";
BA_REL_ "GenSigRxStartValue" BU_SG_REL_ SCCM_1_LS SG_ 2150236160 AutoVehMdChecksum "0";
BA_REL_ "GenSigRxStartValue" BU_SG_REL_ SDM_PR_LS SG_ 2150236160 AutoVehMdChecksum "0";
BA_REL_ "GenSigRxStartValue" BU_SG_REL_ SCCM_2_LS SG_ 2150236160 AutoVehMdARC "0";
BA_REL_ "GenSigRxStartValue" BU_SG_REL_ SCCM_1_LS SG_ 2150236160 AutoVehMdARC "0";
BA_REL_ "GenSigRxStartValue" BU_SG_REL_ SDM_PR_LS SG_ 2150236160 AutoVehMdARC "0";
BA_REL_ "GenSigRxStartValue" BU_SG_REL_ SCCM_2_LS SG_ 2150236160 AutoVehMd "Unknown";
BA_REL_ "GenSigSuprvResp" BU_SG_REL_ SCCM_2_LS SG_ 2150236160 AutoVehMd 1;
BA_REL_ "GenSigRxStartValue" BU_SG_REL_ SCCM_1_LS SG_ 2150236160 AutoVehMd "Unknown";
BA_REL_ "GenSigSuprvResp" BU_SG_REL_ SCCM_1_LS SG_ 2150236160 AutoVehMd 1;
BA_REL_ "GenSigRxStartValue" BU_SG_REL_ PEPS_LS SG_ 2150236160 AutoVehMd "Unknown";
BA_REL_ "GenSigSuprvResp" BU_SG_REL_ PEPS_LS SG_ 2150236160 AutoVehMd 1;
BA_REL_ "GenSigRxStartValue" BU_SG_REL_ SDM_PR_LS SG_ 2150236160 AutoVehMd "0";
BA_REL_ "GenSigRxStartValue" BU_SG_REL_ MCTM_LS SG_ 2158927872 ODDC_InvldData "0";
BA_REL_ "GenSigRxStartValue" BU_SG_REL_ MCTM_LS SG_ 2158927872 ODDC_FUCID "0";
BA_REL_ "GenSigRxStartValue" BU_SG_REL_ MCTM_LS SG_ 2158927872 ODDC_DataVal "0";
BA_REL_ "GenSigRxStartValue" BU_SG_REL_ MCTM_LS SG_ 2158927872 ODDC_DataType "0";
BA_REL_ "GenSigRxStartValue" BU_SG_REL_ MCTM_LS SG_ 2158927872 ODDC_DataId "0";
BA_REL_ "GenSigSuprvResp" BU_SG_REL_ EOCM2cp_K2_LS SG_ 2151178240 AFLGPSCstStReq 1;
BA_REL_ "GenSigSuprvResp" BU_SG_REL_ BCM_LS SG_ 2151178240 AFLGPSCstStReq 1;
BA_REL_ "GenSigSuprvResp" BU_SG_REL_ BCM_LS SG_ 2151178240 AFLCstStReq 1;
BA_REL_ "GenSigSuprvResp" BU_SG_REL_ EOCM2cp_K2_LS SG_ 2151178240 AFLCstStReq 1;
BA_REL_ "GenSigSuprvResp" BU_SG_REL_ BCM_LS SG_ 2151178240 LtRtHnTrCstStReq 1;
BA_REL_ "GenSigSuprvResp" BU_SG_REL_ BCM_LS SG_ 2151178240 AdpHgBmAsSnCsStRq 1;
BA_REL_ "GenSigSuprvResp" BU_SG_REL_ EOCM2cp_K2_LS SG_ 2151178240 AdpHgBmAsSnCsStRq 1;
BA_REL_ "GenSigSuprvResp" BU_SG_REL_ BCM_LS SG_ 2151178240 AdpHgBmAstCstStRq 1;
BA_REL_ "GenSigSuprvResp" BU_SG_REL_ EOCM2cp_K2_LS SG_ 2151178240 AdpHgBmAstCstStRq 1;
BA_REL_ "GenSigSuprvResp" BU_SG_REL_ BCM_LS SG_ 2151178240 LtRtHnTrGPSCstStRq 1;
BA_REL_ "GenSigSuprvResp" BU_SG_REL_ BCM_LS SG_ 2151178240 AutHgBmAsSnCsStRq 1;
BA_REL_ "GenSigSuprvResp" BU_SG_REL_ EOCM2cp_K2_LS SG_ 2151178240 AutHgBmAsSnCsStRq 1;
BA_REL_ "GenSigSuprvResp" BU_SG_REL_ BCM_LS SG_ 2151178240 AutHgBmAstCstStRq 1;
BA_REL_ "GenSigSuprvResp" BU_SG_REL_ EOCM2cp_K2_LS SG_ 2151178240 AutHgBmAstCstStRq 1;
VAL_ 2159132672 ODIAR_DspMID 128 "Reserved" 64 "Reserved" 32 "OTIM" 16 "RearDisplayTwo" 8 "RearDisplayOne" 4 "AuxIP" 2 "CenterStack" 1 "IPC" ;
VAL_ 2159132672 ODIAR_DaTy 21 "Bitmap" 20 "DecimalShort" 19 "HoursOfDay" 18 "Character" 17 "Fuel Consumption Inverted" 16 "Fuel Consumption" 15 "Pressure" 14 "Temperature" 13 "Volume" 12 "DistanceShort" 11 "DistanceLong" 10 "BitmapId" 9 "TextId" 8 "Pictogram" 7 "List " 6 "Date" 5 "Time " 4 "Decimal" 3 "EnumerationValue" 2 "Integer" 1 "String" 0 "Speed" ;
VAL_ 2158960640 ODIIC_ODIInd9 1 "true" 0 "false" ;
VAL_ 2158960640 ODIIC_ODIInd8 1 "true" 0 "false" ;
VAL_ 2158960640 ODIIC_ODIInd7 1 "true" 0 "false" ;
VAL_ 2158960640 ODIIC_ODIInd6 1 "true" 0 "false" ;
VAL_ 2158960640 ODIIC_ODIInd56 1 "true" 0 "false" ;
VAL_ 2158960640 ODIIC_ODIInd55 1 "true" 0 "false" ;
VAL_ 2158960640 ODIIC_ODIInd54 1 "true" 0 "false" ;
VAL_ 2158960640 ODIIC_ODIInd53 1 "true" 0 "false" ;
VAL_ 2158960640 ODIIC_ODIInd52 1 "true" 0 "false" ;
VAL_ 2158960640 ODIIC_ODIInd51 1 "true" 0 "false" ;
VAL_ 2158960640 ODIIC_ODIInd50 1 "true" 0 "false" ;
VAL_ 2158960640 ODIIC_ODIInd5 1 "true" 0 "false" ;
VAL_ 2158960640 ODIIC_ODIInd49 1 "true" 0 "false" ;
VAL_ 2158960640 ODIIC_ODIInd48 1 "true" 0 "false" ;
VAL_ 2158960640 ODIIC_ODIInd47 1 "true" 0 "false" ;
VAL_ 2158960640 ODIIC_ODIInd46 1 "true" 0 "false" ;
VAL_ 2158960640 ODIIC_ODIInd45 1 "true" 0 "false" ;
VAL_ 2158960640 ODIIC_ODIInd44 1 "true" 0 "false" ;
VAL_ 2158960640 ODIIC_ODIInd43 1 "true" 0 "false" ;
VAL_ 2158960640 ODIIC_ODIInd42 1 "true" 0 "false" ;
VAL_ 2158960640 ODIIC_ODIInd41 1 "true" 0 "false" ;
VAL_ 2158960640 ODIIC_ODIInd40 1 "true" 0 "false" ;
VAL_ 2158960640 ODIIC_ODIInd4 1 "true" 0 "false" ;
VAL_ 2158960640 ODIIC_ODIInd39 1 "true" 0 "false" ;
VAL_ 2158960640 ODIIC_ODIInd38 1 "true" 0 "false" ;
VAL_ 2158960640 ODIIC_ODIInd37 1 "true" 0 "false" ;
VAL_ 2158960640 ODIIC_ODIInd36 1 "true" 0 "false" ;
VAL_ 2158960640 ODIIC_ODIInd35 1 "true" 0 "false" ;
VAL_ 2158960640 ODIIC_ODIInd34 1 "true" 0 "false" ;
VAL_ 2158960640 ODIIC_ODIInd33 1 "true" 0 "false" ;
VAL_ 2158960640 ODIIC_ODIInd32 1 "true" 0 "false" ;
VAL_ 2158960640 ODIIC_ODIInd31 1 "true" 0 "false" ;
VAL_ 2158960640 ODIIC_ODIInd30 1 "true" 0 "false" ;
VAL_ 2158960640 ODIIC_ODIInd3 1 "true" 0 "false" ;
VAL_ 2158960640 ODIIC_ODIInd29 1 "true" 0 "false" ;
VAL_ 2158960640 ODIIC_ODIInd28 1 "true" 0 "false" ;
VAL_ 2158960640 ODIIC_ODIInd27 1 "true" 0 "false" ;
VAL_ 2158960640 ODIIC_ODIInd26 1 "true" 0 "false" ;
VAL_ 2158960640 ODIIC_ODIInd25 1 "true" 0 "false" ;
VAL_ 2158960640 ODIIC_ODIInd24 1 "true" 0 "false" ;
VAL_ 2158960640 ODIIC_ODIInd23 1 "true" 0 "false" ;
VAL_ 2158960640 ODIIC_ODIInd22 1 "true" 0 "false" ;
VAL_ 2158960640 ODIIC_ODIInd21 1 "true" 0 "false" ;
VAL_ 2158960640 ODIIC_ODIInd20 1 "true" 0 "false" ;
VAL_ 2158960640 ODIIC_ODIInd2 1 "true" 0 "false" ;
VAL_ 2158960640 ODIIC_ODIInd19 1 "true" 0 "false" ;
VAL_ 2158960640 ODIIC_ODIInd18 1 "true" 0 "false" ;
VAL_ 2158960640 ODIIC_ODIInd17 1 "true" 0 "false" ;
VAL_ 2158960640 ODIIC_ODIInd16 1 "true" 0 "false" ;
VAL_ 2158960640 ODIIC_ODIInd15 1 "true" 0 "false" ;
VAL_ 2158960640 ODIIC_ODIInd14 1 "true" 0 "false" ;
VAL_ 2158960640 ODIIC_ODIInd13 1 "true" 0 "false" ;
VAL_ 2158960640 ODIIC_ODIInd12 1 "true" 0 "false" ;
VAL_ 2158960640 ODIIC_ODIInd11 1 "true" 0 "false" ;
VAL_ 2158960640 ODIIC_ODIInd10 1 "true" 0 "false" ;
VAL_ 2158960640 ODIIC_ODIInd1 1 "true" 0 "false" ;
VAL_ 2158944256 ODDLR_WrpArnd 1 "true" 0 "false" ;
VAL_ 2158944256 ODDLR_ReqType 0 "Subscribe: FU sends DynData back and then on change) " 1 "Unsubscribe: cancel previous Subscribe" ;
VAL_ 2158944256 ODDLR_ReqDir 1 "true" 0 "false" ;
VAL_ 2158944256 ODDLR_DspMID 128 "Reserved" 64 "Reserved" 32 "OTIM" 16 "RearDisplayTwo" 8 "RearDisplayOne" 4 "AuxIP" 2 "CenterStack" 1 "IPC" ;
VAL_ 2158944256 ODDLR_BckgndFlag 1 "Background response" 0 "Immediate response required" ;
VAL_ 2151120896 FrlftPasSeatbltRemOccSt 1 "Occupied" 0 "Empty" ;
VAL_ 2151120896 FrlftPasSeatResCtrlOccStV 1 "Invalid" 0 "Valid" ;
VAL_ 2151120896 FrtlftPasSeatResCtrlOccSt 2 "Occupied" 1 "Empty" 0 "Unknown" ;
VAL_ 2151120896 FrtlftPsSeatOccSnsOpMd 3 "SystemInitMod" 2 "BarrierMod" 1 "ZeroSetCheckMod" 0 "FieldMod" ;
VAL_ 2151120896 FrlftPsSeatOccFltSt 2 "Fault Present - Vehicle Mismatch" 1 "Fault Present" 0 "No Faults Present" ;
VAL_ 2151120896 FrntlftPassClass 7 "Large Adult" 6 "Small Adult" 5 "Large Child" 4 "Small Child" 3 "Child Seat Unknown" 2 "Child Seat Forward" 1 "Child Seat Rearward" 0 "Classification Not Applicable" ;
VAL_ 2154397696 CrShrngConnStat 3 "Terminate Connection" 2 "Ignore Connection" 1 "Valid Connection" 0 "No Action" ;
VAL_ 2154397696 CSPS_RspVerf 4 "Command Response Verification Not Successful" 3 "Command Response Verification Successful" 2 "Zone Response Verification Not Successful" 1 "Zone Response Verification Successful" 0 "No Action" ;
VAL_ 2154397696 CSPS_ConnStat 15 "Reject All Certificates" 14 "Incorrect Fleet ID" 13 "Send Intermediate Certificate" 12 "Send User Certificate" 11 "Send all Authentication Data" 10 "Invalid VIN" 9 "Intermediate Certificate Expired" 8 "Invalid Intermediate Certificate" 7 "Resrvation End Time Exceeded " 6 "Resrvtion Start Tim Not Achieved" 5 "Cert Revoked Via Mobile Device" 4 "Cert Revoked Via Telematics" 3 "Certificate Expired" 2 "Invalid Certificate" 1 "Valid Certificate" 0 "No Action" ;
VAL_ 2154397696 CrShrngFbsEnblStat 3 "Fail" 2 "Enabled" 1 "Disabled" 0 "No Action" ;
VAL_ 2154397696 CrShrngRvkCertfctRsp 4 "No CertIDs Stored" 3 "CertID Not Matched" 2 "Revoke Certificate Successful" 1 "Write Failure" 0 "No Action" ;
VAL_ 2150531072 RegPwrLmtdDspPrcntVs 1 "true" 0 "false" ;
VAL_ 2150531072 RegPwrLmtdIO 1 "true" 0 "false" ;
VAL_ 2154725376 AuxHtrAtv378 1 "true" 0 "false" ;
VAL_ 2154725376 AuxHtrRq 1 "On" 0 "Off" ;
VAL_ 2158133248 HTRCsStAvail 1 "true" 0 "false" ;
VAL_ 2158133248 HTRCsCrStVal 4 "On Away" 3 "On Home" 2 "On" 1 "Off" 0 "No Action" ;
VAL_ 2158133248 HTRCA_Res3Avail 1 "true" 0 "false" ;
VAL_ 2158133248 HTRCA_Res2Avail 1 "true" 0 "false" ;
VAL_ 2158133248 HTRCA_Res1Avail 1 "true" 0 "false" ;
VAL_ 2158133248 HTRCA_OnAwAvail 1 "true" 0 "false" ;
VAL_ 2158133248 HTRCA_OnHmAvail 1 "true" 0 "false" ;
VAL_ 2158133248 HTRCA_OnAvail 1 "true" 0 "false" ;
VAL_ 2158133248 HTRCA_OffAvail 1 "true" 0 "false" ;
VAL_ 2151931904 ElctShfPriLtdPerfMdIO 1 "true" 0 "false" ;
VAL_ 2151931904 RegVltCtlEngyRcvryAct 1 "true" 0 "false" ;
VAL_ 2151931904 VehSpdCntlSystmType 2 "Adaptive Cruise Control" 1 "Conventional Cruise Control" 0 "No Vehicle Speed Control" ;
VAL_ 2151931904 PTExPrtclFltWrng3IO 1 "true" 0 "false" ;
VAL_ 2151931904 PTExPartFltManRegStat 7 "Reserved 3" 6 "Reserved 2" 5 "Reserved 1" 4 "Complete" 3 "In Progress" 2 "Not Allowed" 1 "Allowed" 0 "Cleaning Not Required" ;
VAL_ 2151931904 AWDRecmndIO 1 "true" 0 "false" ;
VAL_ 2155028480 RgtLnChgThrt 1 "true" 0 "false" ;
VAL_ 2151915520 ElecShfRngDisp 15 "Unused and Reserved 3" 14 "Unused and Reserved 2" 13 "Unused and Reserved 1" 12 "Park Requested And Denied" 11 "Drive Requested And In Progress" 10 "Neutral Requested And In Progress" 9 "Reverse Requested And In Progress" 8 "Park Requested And In Progress" 7 "Reserved" 6 "Manual Nominal" 5 "Low Nominal" 4 "Drive Nominal" 3 "Neutral Nominal" 2 "Reverse Nominal" 1 "Park Nominal" 0 "No Display " ;
VAL_ 2151915520 ESPTransMalfIO 1 "true" 0 "false" ;
VAL_ 2151915520 ESPRngInvldReqIO 1 "true" 0 "false" ;
VAL_ 2151915520 ESPPrkInvldReqIO 1 "true" 0 "false" ;
VAL_ 2151915520 ESPHldShfLvrToEngRgIO 1 "true" 0 "false" ;
VAL_ 2151915520 ESPDrvrPrkIlkSftAtdIO 1 "true" 0 "false" ;
VAL_ 2151915520 ESPDrvrIlkShfAtdIO 1 "true" 0 "false" ;
VAL_ 2151915520 AHAct 1 "true" 0 "false" ;
VAL_ 2151915520 AHEnbld 1 "true" 0 "false" ;
VAL_ 2151915520 ShfToPrkBfExtngIO 1 "true" 0 "false" ;
VAL_ 2151915520 AHServcIO 1 "true" 0 "false" ;
VAL_ 2151915520 AHAppBrkPedlIO 1 "true" 0 "false" ;
VAL_ 2151915520 AHDisbldStbltIO 1 "true" 0 "false" ;
VAL_ 2151915520 AHDisbldDrOpnIO 1 "true" 0 "false" ;
VAL_ 2151915520 ElcTransRngSlctVDA 1 "VirtualDeviceAvailable" 0 "VirtualDeviceUnavailable" ;
VAL_ 2155364352 CstmrUsblSOCV 1 "Invalid" 0 "Valid" ;
VAL_ 2155364352 BattCntrlPrcssrVDA 1 "VirtualDeviceAvailable" 0 "VirtualDeviceUnavailable" ;
VAL_ 2155364352 JmpStrtStat 0 "Inactive" 1 "In Progress" 2 "Complete" 3 "Power Mode" 4 "Disabled" ;
VAL_ 2155364352 SvcHybridSysIO 1 "true" 0 "false" ;
VAL_ 2155364352 HybMdDisp 15 "Engine Charging Battery While Idle" 14 "Engine Charging Battery Moving" 13 "Engine Power Load Sharing" 12 "Battery Power Load Sharing" 11 "Undetermined" 10 "Charging With Engine On" 9 "Charging With Engine Off" 8 "Hybrid Power 4WD" 7 "Hybrid Power 2WD" 6 "Engine Power 4WD" 5 "Engine Power 2WD" 4 "Battery Power 4WD" 3 "Battery Power 2WD" 2 "Auto Stop" 1 "Engine Idle" 0 "Default / Accessory" ;
VAL_ 2150260736 AV_Drv_Sys_Ena_Red 1 "true" 0 "false" ;
VAL_ 2150260736 Rear_Etr_Swtch_Ena_Red 1 "true" 0 "false" ;
VAL_ 2150260736 AVrdcmpltrtndefRed 1 "true" 0 "false" ;
VAL_ 2150260736 VehHlthMngrStBckup 6 "Normal Operation" 5 "Degraded Mode 5" 4 "Degraded Mode 4" 3 "Degraded Mode 3" 2 "Degraded Mode 2" 1 "Degraded Mode 1" 0 "Initialization" ;
VAL_ 2150260736 AutoVehMdBckup 5 "Failed" 4 "Autonomous Unsupervised" 3 "Supervisor Override" 2 "Autonomous Supervised" 1 "Manual" 0 "Unknown" ;
VAL_ 2152562688 BSCWB_ZnEnbd 1 "true" 0 "false" ;
VAL_ 2152562688 BSCAB_ZnEnbd 1 "true" 0 "false" ;
VAL_ 2152112128 PMVSS_Disps 7 "Visualization Type 7" 6 "Visualization Type 6" 5 "Visualization Type 5" 4 "Visualization Type 4" 3 "Visualization Type 3" 2 "Visualization Type 2" 1 "Visualization Type 1" 0 "No Action" ;
VAL_ 2152112128 PMVSS_Exhst 7 "Visualization Type 7" 6 "Visualization Type 6" 5 "Visualization Type 5" 4 "Visualization Type 4" 3 "Visualization Type 3" 2 "Visualization Type 2" 1 "Visualization Type 1" 0 "No Action" ;
VAL_ 2152112128 PMVSS_PsngrSeat 7 "Visualization Type 7" 6 "Visualization Type 6" 5 "Visualization Type 5" 4 "Visualization Type 4" 3 "Visualization Type 3" 2 "Visualization Type 2" 1 "Visualization Type 1" 0 "No Action" ;
VAL_ 2152112128 PMVSS_DrvrSeat 7 "Visualization Type 7" 6 "Visualization Type 6" 5 "Visualization Type 5" 4 "Visualization Type 4" 3 "Visualization Type 3" 2 "Visualization Type 2" 1 "Visualization Type 1" 0 "No Action" ;
VAL_ 2152112128 PMVSS_AdptCrsCnt 7 "Visualization Type 7" 6 "Visualization Type 6" 5 "Visualization Type 5" 4 "Visualization Type 4" 3 "Visualization Type 3" 2 "Visualization Type 2" 1 "Visualization Type 1" 0 "No Action" ;
VAL_ 2152112128 PMVSS_Drvln 7 "Visualization Type 7" 6 "Visualization Type 6" 5 "Visualization Type 5" 4 "Visualization Type 4" 3 "Visualization Type 3" 2 "Visualization Type 2" 1 "Visualization Type 1" 0 "No Action" ;
VAL_ 2152112128 PMVSS_Susp 7 "Visualization Type 7" 6 "Visualization Type 6" 5 "Visualization Type 5" 4 "Visualization Type 4" 3 "Visualization Type 3" 2 "Visualization Type 2" 1 "Visualization Type 1" 0 "No Action" ;
VAL_ 2152112128 PMVSS_Strng 7 "Visualization Type 7" 6 "Visualization Type 6" 5 "Visualization Type 5" 4 "Visualization Type 4" 3 "Visualization Type 3" 2 "Visualization Type 2" 1 "Visualization Type 1" 0 "No Action" ;
VAL_ 2152112128 PMVSS_Trans 7 "Visualization Type 7" 6 "Visualization Type 6" 5 "Visualization Type 5" 4 "Visualization Type 4" 3 "Visualization Type 3" 2 "Visualization Type 2" 1 "Visualization Type 1" 0 "No Action" ;
VAL_ 2152112128 PMVSS_Eng 7 "Visualization Type 7" 6 "Visualization Type 6" 5 "Visualization Type 5" 4 "Visualization Type 4" 3 "Visualization Type 3" 2 "Visualization Type 2" 1 "Visualization Type 1" 0 "No Action" ;
VAL_ 2152112128 PMVSS_Snd 7 "Visualization Type 7" 6 "Visualization Type 6" 5 "Visualization Type 5" 4 "Visualization Type 4" 3 "Visualization Type 3" 2 "Visualization Type 2" 1 "Visualization Type 1" 0 "No Action" ;
VAL_ 2153857024 TDRCADD_WOTEvnts 1 "true" 0 "false" ;
VAL_ 2153857024 TDRCADD_LDWEvnts 1 "true" 0 "false" ;
VAL_ 2153857024 TDRCADD_FCMBrEvts 1 "true" 0 "false" ;
VAL_ 2153857024 TDRCADD_DrwDrvAlrt 1 "true" 0 "false" ;
VAL_ 2153857024 TDRCADD_RCMBrEvts 1 "true" 0 "false" ;
VAL_ 2153857024 TDRCADD_FCImntAlrts 1 "true" 0 "false" ;
VAL_ 2153857024 TDRCADD_FCHdwyAlrt 1 "true" 0 "false" ;
VAL_ 2153857024 TDRCADD_StCtrlEvnts 1 "true" 0 "false" ;
VAL_ 2153857024 TDRCADD_ABSAtvEvt 1 "true" 0 "false" ;
VAL_ 2153857024 TDRCADD_TrCtrlEvnts 1 "true" 0 "false" ;
VAL_ 2153857024 TDRCADD_OvSpdEvnt 1 "true" 0 "false" ;
VAL_ 2153857024 TDRCADD_DistDrvn 1 "true" 0 "false" ;
VAL_ 2153857024 TDRCADD_MaxSpd 1 "true" 0 "false" ;
VAL_ 2153865216 TeenDrvReq 0 "No Action" 1 "Verify Teen PIN" 2 "Update Teen PIN" 3 "Set Teen Key" 4 "Clear Teen Key" 5 "Check for Teen Key" 6 "Clear Teen Keys and PIN" 7 "Reset Report Card" 8 "Request Report Card Data" ;
VAL_ 2153865216 TnDrvSpdLmtCstStReq 0 "No Action" 1 "Off" 2 "On" ;
VAL_ 2153865216 TDOWCSR_StatReq 0 "No Action" 1 "Off" 2 "On" ;
VAL_ 2153865216 TDOWCSR_IncSwAct 1 "true" 0 "false" ;
VAL_ 2153865216 TDOWCSR_DecSwAct 1 "true" 0 "false" ;
VAL_ 2153840640 TnDrvDRLOffUnbIO 1 "true" 0 "false" ;
VAL_ 2153840640 TnDrvALCOffUnbIO 1 "true" 0 "false" ;
VAL_ 2153824256 TeenDrvAct 1 "true" 0 "false" ;
VAL_ 2153824256 TeenDrvRsp 0 "No Action" 1 "Teen PIN Verified" 2 "Teen PIN Updated" 3 "Teen PIN Mismatch" 4 "Teen Key Set Complete" 5 "Teen Key Clear Complete" 6 "Key Not Present" 7 "Key Detected as Teen Key" 8 "Key Detected as NOT Teen Key" ;
VAL_ 2153824256 TeenDrvFtrAvl 1 "true" 0 "false" ;
VAL_ 2153824256 TeenDrvPINStrd 1 "true" 0 "false" ;
VAL_ 2153824256 TnDrvGapAdjUnbIO 1 "true" 0 "false" ;
VAL_ 2153824256 TnDrvOvrSpdIO 1 "true" 0 "false" ;
VAL_ 2153824256 TDOvSpdWrnCstStAvl 1 "true" 0 "false" ;
VAL_ 2153824256 TDOWCCSV_CrStat 0 "No Action" 1 "Off" 2 "On" ;
VAL_ 2153824256 TnDrvSpdLmtCstStAvl 1 "true" 0 "false" ;
VAL_ 2153824256 TDSLCCSV_SpLmtStat 0 "No Action" 1 "Off" 2 "On" ;
VAL_ 2150252544 ECHG_YAxisMaxVal 0 "6" 1 "12" 2 "16" 3 "20" 4 "32" 5 "40" 6 "48" 7 "60" ;
VAL_ 2150252544 ECHG_XAxisTkMrkIntvl 0 "0.5" 1 "1" 2 "5" 3 "10" 4 "20" 5 "50" 6 "80" 7 "100" ;
VAL_ 2150252544 ECHG_MeasUnit 0 "km/kWh" 1 "mi/kWh" 2 "kWh/100km" 3 "km/L" 4 "mi/gal" 5 "L/100km" 6 "mi/kg" 7 "kg/100km" ;
VAL_ 2155913216 PFAS_SrvPedAlrtIO 1 "true" 0 "false" ;
VAL_ 2155913216 PFAS_PFASysStat 0 "Disable" 1 "Active" 2 "Fault" 3 "Unused and Reserved" ;
VAL_ 2155913216 PFAS_PFASndGenEn 1 "true" 0 "false" ;
VAL_ 2155913216 PFAS_PFARevSnd 0 "No Action" 1 "Sound #1" 2 "Sound #2" 3 "Sound #3" ;
VAL_ 2155913216 PFAS_PFAFwdSnd 0 "No Action" 1 "Sound #1" 2 "Sound #2" 3 "Sound #3" ;
VAL_ 2155913216 PedFrndlyAlrtCsSetAvl 1 "true" 0 "false" ;
VAL_ 2155913216 PedFrndlyAlrtCsCrStVal 0 "No Value" 1 "Off" 2 "On" ;
VAL_ 2155913216 DslExhFldRmngDstHRsV 1 "Invalid" 0 "Valid" ;
VAL_ 2150236160 AutoVehMd 5 "Failed" 4 "Autonomous Unsupervised" 3 "Supervisor Override" 2 "Autonomous Supervised" 1 "Manual" 0 "Unknown" ;
VAL_ 2158927872 ODDC_InvldData 1 "true" 0 "false" ;
VAL_ 2158927872 ODDC_DataType 21 "Bitmap" 20 "DecimalShort" 19 "HoursOfDay" 18 "Character" 17 "Fuel Consumption Inverted" 16 "Fuel Consumption" 15 "Pressure" 14 "Temperature" 13 "Volume" 12 "DistanceShort" 11 "DistanceLong" 10 "BitmapId" 9 "TextId" 8 "Pictogram" 7 "List " 6 "Date" 5 "Time " 4 "Decimal" 3 "EnumerationValue" 2 "Integer" 1 "String" 0 "Speed" ;
VAL_ 2151702528 LnMrkngIndRgt 3 "Unused and Reserved 1" 2 "Green Indicator" 1 "White Indicator" 0 "Indicator Off" ;
VAL_ 2151702528 LnMrkngIndLft 3 "Unused and Reserved 1" 2 "Green Indicator" 1 "White Indicator" 0 "Indicator Off" ;
VAL_ 2151702528 LnKepAsstStIndRgt 7 "Unused and Reserved 2" 6 "Unused and Reserved 1" 5 "Yellow Indicator" 4 "Red Indicator" 3 "Blue Indicator" 2 "Green Indicator" 1 "White Indicator" 0 "Indicator Off" ;
VAL_ 2151702528 LnKepAsstStIndLft 7 "Unused and Reserved 2" 6 "Unused and Reserved 1" 5 "Yellow Indicator" 4 "Red Indicator" 3 "Blue Indicator" 2 "Green Indicator" 1 "White Indicator" 0 "Indicator Off" ;
VAL_ 2151702528 LnKpngAstRecfblIndRq 7 "Unused and Reserved 2" 6 "Unused and Reserved 1" 5 "Yellow Solid Indicator" 4 "Yellow Flashing Indicator" 3 "Blue Solid Indicator" 2 "Green Solid Indicator" 1 "White Solid Indicator" 0 "Indicator Off" ;
VAL_ 2155970560 ClmCntLdShdLvlRq 0 "No Load Shedding" 1 "Load Shed Level 1" 2 "Load Shed Level 2" 3 "Load Shed Level 3" 4 "Load Shed Level 4" ;
VAL_ 2155970560 ClmCntBatSaverIO 1 "true" 0 "false" ;
VAL_ 2151178240 AFLGPSCstStReq 0 "No Action" 1 "Corner And Curve Lighting Only" 2 "Intelligent Light Distribution" 3 "GPS Assistance" 4 "Reserved1" 5 "Reserved2" 6 "Reserved3" 7 "Off" ;
VAL_ 2151178240 AFLCstStReq 0 "No Action" 1 "Corner And Curve Lighting Only" 2 "Intelligent Light Distribution" 3 "Reserved1" 4 "Reserved2" 5 "Reserved3" 6 "Reserved4" 7 "Off" ;
VAL_ 2151178240 LtRtHnTrCstStReq 0 "No Action" 1 "Left Hand Traffic" 2 "Right Hand Traffic" ;
VAL_ 2151178240 AdpHgBmAsSnCsStRq 0 "No Action" 1 "Off" 2 "Normal Sensitivity" 3 "Reduced Sensitivity" 4 "Reserved1" 5 "Reserved2" 6 "Reserved3" 7 "Reserved4" ;
VAL_ 2151178240 AdpHgBmAstCstStRq 0 "No Action" 1 "Off" 2 "On" 3 "Reserved1" 4 "Reserved2" 5 "Reserved3" 6 "Reserved4" 7 "Reserved5" ;
VAL_ 2151178240 LtRtHnTrGPSCstStRq 0 "No Action" 1 "Left Hand Traffic" 2 "Right Hand Traffic" 3 "Automatic" 4 "Reserved1" 5 "Reserved2" 6 "Reserved3" 7 "Reserved4" ;
VAL_ 2151178240 AutHgBmAsSnCsStRq 0 "No Action" 1 "Off" 2 "On Normal Sensitivity" 3 "On Reduced Sensitivity" 4 "Reserved1" 5 "Reserved2" 6 "Reserved3" 7 "Reserved4" ;
VAL_ 2151178240 AutHgBmAstCstStRq 0 "No Action" 1 "Off" 2 "On" 3 "Reserved1" 4 "Reserved2" 5 "Reserved3" 6 "Reserved4" 7 "Reserved5" ;
VAL_ 2152013824 SmrtHgBmAstCstSetAvail 1 "true" 0 "false" ;
VAL_ 2152013824 SmrtHgBmAstCstCurrSetVal 7 "Unused and Reserved 5" 6 "Unused and Reserved 4" 5 "Unused and Reserved 3" 4 "Unused and Reserved 2" 3 "Unused and Reserved 1" 2 "Adaptive High Beam" 1 "Auto High Beam" 0 "No Action" ;
VAL_ 2155536384 RevClnMtgnBrkReqAct 1 "true" 0 "false" ;
VAL_ 2155536384 TnDrvRIMOffUnbIO 1 "true" 0 "false" ;
VAL_ 2155536384 RVBUnblIO 1 "true" 0 "false" ;
VAL_ 2155536384 RVBFldIO 1 "true" 0 "false" ;
VAL_ 2155536384 RVBEnbldIO 1 "true" 0 "false" ;
VAL_ 2155536384 RVBDsbldIO 1 "true" 0 "false" ;
VAL_ 2152742912 ShrtRngRdrOffIO 1 "true" 0 "false" ;
VAL_ 2152742912 RrRdrFldIO 1 "true" 0 "false" ;
VAL_ 2152742912 RrRdrBlckdIO 1 "true" 0 "false" ;
VAL_ 2152742912 RrEOCMMdlFldIO 1 "true" 0 "false" ;
VAL_ 2151481344 HdUpDsplyUnblIO 1 "true" 0 "false" ;
VAL_ 2151481344 FSRACCFrstRsmPrssIO 1 "true" 0 "false" ;
VAL_ 2151481344 FrtRdrBlckdIO 1 "true" 0 "false" ;
VAL_ 2151481344 ShtToPrkBfExtngVehIO 1 "true" 0 "false" ;
VAL_ 2151481344 AutoBrkRlsIO 1 "true" 0 "false" ;
VAL_ 2149957632 PrkAstRrObjSnsngRqAct 1 "true" 0 "false" ;
VAL_ 2149957632 PrkAstOprtrDsrdStat 0 "Off" 1 "On" 2 "Tow Bar Attached" ;
VAL_ 2149957632 PrkAstInhbtReq 1 "true" 0 "false" ;
VAL_ 2149957632 ClsnMtgtnInhbtd 1 "true" 0 "false" ;
VAL_ 2153889792 LCArrwBlk5Act 1 "true" 0 "false" ;
VAL_ 2153889792 LCArrwBlk4Act 1 "true" 0 "false" ;
VAL_ 2153889792 LCArrwBlk3Act 1 "true" 0 "false" ;
VAL_ 2153889792 LCArrwBlk2Act 1 "true" 0 "false" ;
VAL_ 2153889792 LCArrwBlk1Act 1 "true" 0 "false" ;
VAL_ 2153930752 LnCntrVhlStpd 1 "true" 0 "false" ;
VAL_ 2153930752 LnCntrSpchPrmtReq 3 "Unused and Reserved" 2 "Take Vehicle Control" 1 "Take Steering" 0 "No Prompt" ;
VAL_ 2153930752 LCWrnIndReq 11 "Take Steering" 10 "Due to Weather" 9 "Can not See Eyes" 8 "Canceled Take Steering" 7 "Adaptive Cruise Disengaging" 6 "Vehicles Too Close" 5 "Excessive Speed" 4 "Construction" 3 "Freeway Ends" 2 "Tight Curve" 1 "Can not See Lanes" 0 "No Indication" 14 "Lane Following Locked Out" 13 "Service Driver Assist System" 12 "Take Vehicle Control" ;
VAL_ 2153930752 LCCDrvrAwrnsIO 1 "true" 0 "false" ;
VAL_ 2153930752 LCConvMsgIndreq 31 "Reserved" 30 "Reserved" 29 "Reserved" 28 "Reserved" 27 "Reserved" 26 "Reserved" 25 "Reserved" 24 "Reserved" 23 "Reserved" 22 "Reserved" 21 "Reserved" 20 "Reserved" 19 "Show Fuel Range" 18 "Show Fuel Level" 17 "Take Time to Look at Road" 16 "Road Detour Detected" 15 "Lane Ending Ahead" 14 "Exit Only Lane Ahead" 13 "Road Exit Detected Ahead" 12 "Major Road Interchange Ahead" 11 "Slow Moving Traffic in Right Lane" 10 "Slow Moving Traffic Ahead" 9 "Slow Moving Traffic in Left Lane" 8 "Merging Vehicle" 7 "Heavy Traffic" 6 "Right Blind Spot Occupied" 5 "Left Blind Spot Occupied" 4 "Tailgater Detected" 3 "Being Passed on Right" 2 "Being Passed on Left" 1 "Behind Slow Vehicle" 0 "No Indication" ;
VAL_ 2153930752 LCCIndReq 7 "Reserved" 6 "Reserved" 5 "Reserved" 4 "Red Indicator" 3 "Blue Indicator" 2 "Green Indicator" 1 "White Indicator" 0 "Indicator Off" ;
VAL_ 2153930752 LnCntrNonRspDrvrCnd 1 "true" 0 "false" ;
VAL_ 2153930752 LnCntrEsclnStat 3 "System Faulted" 2 "Limit Condition" 1 "Driver Not Looking to Roadway" 0 "None" ;
SIG_GROUP_ 2159132672 ODIActn_RSD 1 : ODIAR_FUCID ODIAR_DspMID ODIAR_DaTy ODIAR_ActnVal ODIAR_ActnID;
SIG_GROUP_ 2158960640 ODIInd_CntrStck 1 : ODIIC_FUCID ODIIC_ODIInd9 ODIIC_ODIInd8 ODIIC_ODIInd7 ODIIC_ODIInd6 ODIIC_ODIInd56 ODIIC_ODIInd55 ODIIC_ODIInd54 ODIIC_ODIInd53 ODIIC_ODIInd52 ODIIC_ODIInd51 ODIIC_ODIInd50 ODIIC_ODIInd5 ODIIC_ODIInd49 ODIIC_ODIInd48 ODIIC_ODIInd47 ODIIC_ODIInd46 ODIIC_ODIInd45 ODIIC_ODIInd44 ODIIC_ODIInd43 ODIIC_ODIInd42 ODIIC_ODIInd41 ODIIC_ODIInd40 ODIIC_ODIInd4 ODIIC_ODIInd39 ODIIC_ODIInd38 ODIIC_ODIInd37 ODIIC_ODIInd36 ODIIC_ODIInd35 ODIIC_ODIInd34 ODIIC_ODIInd33 ODIIC_ODIInd32 ODIIC_ODIInd31 ODIIC_ODIInd30 ODIIC_ODIInd3 ODIIC_ODIInd29 ODIIC_ODIInd28 ODIIC_ODIInd27 ODIIC_ODIInd26 ODIIC_ODIInd25 ODIIC_ODIInd24 ODIIC_ODIInd23 ODIIC_ODIInd22 ODIIC_ODIInd21 ODIIC_ODIInd20 ODIIC_ODIInd2 ODIIC_ODIInd19 ODIIC_ODIInd18 ODIIC_ODIInd17 ODIIC_ODIInd16 ODIIC_ODIInd15 ODIIC_ODIInd14 ODIIC_ODIInd13 ODIIC_ODIInd12 ODIIC_ODIInd11 ODIIC_ODIInd10 ODIIC_ODIInd1;
SIG_GROUP_ 2158977024 ODIEvntPkt_CntrStck 1 : ODIEC_MultiFrRetCh ODIEC_FUCID ODIEC_EvID;
SIG_GROUP_ 2158944256 ODIDynDataLstRq_RSD 1 : ODDLR_SubIdReqM ODDLR_WrpArnd ODDLR_ReqType ODDLR_ReqDir ODDLR_NmEntries ODDLR_Idx ODDLR_FUCID ODDLR_DspMID ODDLR_DataId ODDLR_BckgndFlag;
SIG_GROUP_ 2154397696 CrShrngPhStat 1 : CSPS_RspVerf CSPS_ConnStat CSPS_CertfctId;
SIG_GROUP_ 2158133248 HTRCsAvail 1 : HTRCA_Res3Avail HTRCA_Res2Avail HTRCA_Res1Avail HTRCA_OnAwAvail HTRCA_OnHmAvail HTRCA_OnAvail HTRCA_OffAvail;
SIG_GROUP_ 2150244352 EngyCnsHsGrphDspDtVal 1 : ECHGDDV_Col10 ECHGDDV_Col9 ECHGDDV_Col8 ECHGDDV_Col7 ECHGDDV_Col6 ECHGDDV_Col5 ECHGDDV_Col4 ECHGDDV_Col3 ECHGDDV_Col2 ECHGDDV_Col1 ECHGDDV_EngyConsAvg;
SIG_GROUP_ 2152562688 BckupSnsrClngWshB 1 : BSCWB_ZnEnbd BSCWB_Zn8 BSCWB_Zn7 BSCWB_Zn3 BSCWB_Zn2;
SIG_GROUP_ 2152562688 BckupSnsrClngAirB 1 : BSCAB_ZnEnbd BSCAB_Zn8 BSCAB_Zn7 BSCAB_Zn3 BSCAB_Zn2;
SIG_GROUP_ 2152112128 PerfMdVislztnScrnStat 1 : PMVSS_Disps PMVSS_Exhst PMVSS_PsngrSeat PMVSS_DrvrSeat PMVSS_AdptCrsCnt PMVSS_Drvln PMVSS_Susp PMVSS_Strng PMVSS_Trans PMVSS_Eng PMVSS_Snd;
SIG_GROUP_ 2153857024 TnDrvRptCrdAvlDspDat 1 : TDRCADD_WOTEvnts TDRCADD_LDWEvnts TDRCADD_FCMBrEvts TDRCADD_DrwDrvAlrt TDRCADD_RCMBrEvts TDRCADD_FCImntAlrts TDRCADD_FCHdwyAlrt TDRCADD_StCtrlEvnts TDRCADD_ABSAtvEvt TDRCADD_TrCtrlEvnts TDRCADD_OvSpdEvnt TDRCADD_DistDrvn TDRCADD_MaxSpd;
SIG_GROUP_ 2153865216 TDOvSpdWrnCstStReq 1 : TDOWCSR_StatReq TDOWCSR_IncSwAct TDOWCSR_DecSwAct;
SIG_GROUP_ 2153824256 TDOvSpdWrnCstCrStVl 1 : TDOWCCSV_CrStVl TDOWCCSV_CrStat;
SIG_GROUP_ 2153824256 TnDrvSpdLmtCstCrStVl 1 : TDSLCCSV_SpLmtStat TDSLCCSV_SpLmDisVl;
SIG_GROUP_ 2150252544 EngyConsmpHistGrph 1 : ECHG_YAxisMaxVal ECHG_XAxisTkMrkIntvl ECHG_Column10 ECHG_Column09 ECHG_Column08 ECHG_Column07 ECHG_Column06 ECHG_Column05 ECHG_Column04 ECHG_Column03 ECHG_Column02 ECHG_Column01 ECHG_EngyCnsmdAvg ECHG_MeasUnit;
SIG_GROUP_ 2155913216 PedFrndlyAlrtStat 1 : PFAS_SrvPedAlrtIO PFAS_PFASysStat PFAS_PFASndVolCtrl PFAS_PFASndGenEn PFAS_PFARevSnd PFAS_PFAFwdSnd PFAS_PFACrsOvrSpd;
SIG_GROUP_ 2158927872 ODIDynData_CntrStck 1 : ODDC_InvldData ODDC_FUCID ODDC_DataVal ODDC_DataType ODDC_DataId;
